// *************************************************************************** *
// *                                                                           *
// *                      Mentor Graphics Corporation                          *
// *                          All rights reserved                              *
// *                                                                           *
// *************************************************************************** *
// *                                                                           *
// * Description:         CANDB File                                           *
// * Generated at:        2019-08-28 11:46:03                                  *
// * System:              xMA19024                                             *
// * Variant:             LSPA                                                 *
// * Network:             PropulsionCAN                                        *
// *                                                                           *
// *************************************************************************** *
// *                                                                           *
// *             THIS CONFIGURATION MIGHT CONTAIN SOME ERRORS                  *
// *              IF THE INPUT MODEL WAS NOT PROPERLY FORMED!                  *
// *                    Do Not Use this File directly!                         *
// *                                                                           *
// *************************************************************************** *
VERSION "PropulsionCAN"

NS_ :

BS_:

BU_:  BECM DEM ECM EGSM ESM ETC IEM IGM ISGM MVBM MVCM MVEM OBC SRS TACM TCM VDDM VGM

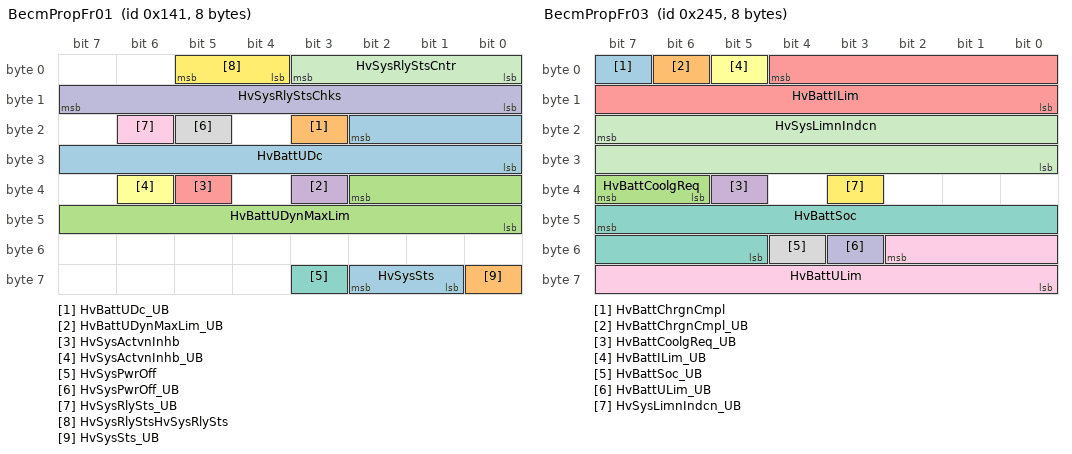
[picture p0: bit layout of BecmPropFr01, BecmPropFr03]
BO_ 321 BecmPropFr01: 8 BECM
 SG_ HvBattUDc : 18|11@0+ (0.25,0.0) [0.0|511.0] "Volt" ECM,IEM,IGM,OBC,VDDM
 SG_ HvBattUDc_UB : 19|1@0+ (1,0) [0|1] "" ECM,IEM,IGM,OBC,VDDM
 SG_ HvBattUDynMaxLim : 34|11@0+ (0.25,0.0) [0.0|511.0] "Volt" IEM,IGM,VDDM
 SG_ HvBattUDynMaxLim_UB : 35|1@0+ (1,0) [0|1] "" IEM,IGM,VDDM
 SG_ HvSysActvnInhb : 37|1@0+ (1,0) [0|1] "" ECM,VDDM
 SG_ HvSysActvnInhb_UB : 38|1@0+ (1,0) [0|1] "" ECM,VDDM
 SG_ HvSysPwrOff : 59|1@0+ (1,0) [0|1] "" ECM
 SG_ HvSysPwrOff_UB : 21|1@0+ (1,0) [0|1] "" ECM
 SG_ HvSysRlySts_UB : 22|1@0+ (1,0) [0|1] "" ECM,ESM,IEM,IGM,OBC,VDDM
 SG_ HvSysRlyStsChks : 15|8@0+ (1.0,0.0) [0.0|255.0] "Unitless" ECM,ESM,IEM,IGM,OBC,VDDM
 SG_ HvSysRlyStsCntr : 3|4@0+ (1.0,0.0) [0.0|15.0] "Unitless" ECM,ESM,IEM,IGM,OBC,VDDM
 SG_ HvSysRlyStsHvSysRlySts : 5|2@0+ (1,0) [0|3] "" ECM,ESM,IEM,IGM,OBC,VDDM
 SG_ HvSysSts : 58|2@0+ (1,0) [0|3] "" ECM,VDDM
 SG_ HvSysSts_UB : 56|1@0+ (1,0) [0|1] "" ECM,VDDM

BO_ 373 BecmPropFr02: 8 BECM
 SG_ ACChrgnConnectSts : 43|1@0+ (1,0) [0|1] "" OBC
 SG_ ACChrgnConnectSts_UB : 42|1@0+ (1,0) [0|1] "" OBC
 SG_ ACChrgnCPSts : 41|1@0+ (1,0) [0|1] "" OBC
 SG_ ACChrgnCPSts_UB : 40|1@0+ (1,0) [0|1] "" OBC
 SG_ ACChrgnCurrentLimn : 55|8@0+ (1.0,0.0) [0.0|255.0] "Unitless" OBC
 SG_ ACChrgnCurrentLimn_UB : 61|1@0+ (1,0) [0|1] "" OBC
 SG_ ACChrgnIfErr : 46|3@0+ (1.0,0.0) [0.0|7.0] "Unitless" OBC
 SG_ ACChrgnIfErr_UB : 60|1@0+ (1,0) [0|1] "" OBC
 SG_ ACChrgnS2Sts : 63|1@0+ (1,0) [0|1] "" OBC
 SG_ ACChrgnS2Sts_UB : 62|1@0+ (1,0) [0|1] "" OBC
 SG_ HvBattLimnIndcn_UB : 47|1@0+ (1,0) [0|1] "" ECM,VDDM
 SG_ HvBattLimnIndcnChks : 7|8@0+ (1.0,0.0) [0.0|255.0] "Unitless" ECM,VDDM
 SG_ HvBattLimnIndcnCntr : 31|4@0+ (1.0,0.0) [0.0|15.0] "Unitless" ECM,VDDM
 SG_ HvBattLimnIndcnHvBattLimnIndcn : 15|16@0+ (1.0,0.0) [0.0|65535.0] "Unitless" ECM,VDDM
 SG_ HvBattUDynMinLim : 26|11@0+ (0.25,0.0) [0.0|511.0] "Volt" IEM,IGM,VDDM
 SG_ HvBattUDynMinLim_UB : 27|1@0+ (1,0) [0|1] "" IEM,IGM,VDDM
 SG_ MaintainBattTFb : 59|2@0+ (1,0) [0|3] "" VDDM
 SG_ MaintainBattTFb_UB : 57|1@0+ (1,0) [0|1] "" VDDM

BO_ 581 BecmPropFr03: 8 BECM
 SG_ HvBattChrgnCmpl : 7|1@0+ (1,0) [0|1] "" ECM,OBC
 SG_ HvBattChrgnCmpl_UB : 6|1@0+ (1,0) [0|1] "" ECM,OBC
 SG_ HvBattCoolgReq : 39|2@0+ (1,0) [0|3] "" ECM,VDDM
 SG_ HvBattCoolgReq_UB : 37|1@0+ (1,0) [0|1] "" ECM,VDDM
 SG_ HvBattILim : 4|13@0+ (0.1,0.0) [0.0|819.1] "A" ECM,VDDM
 SG_ HvBattILim_UB : 5|1@0+ (1,0) [0|1] "" ECM,VDDM
 SG_ HvBattSoc : 47|11@0+ (0.05,0.0) [0.0|100.0] "%" ECM,IEM,IGM,VDDM
 SG_ HvBattSoc_UB : 52|1@0+ (1,0) [0|1] "" ECM,IEM,IGM,VDDM
 SG_ HvBattULim : 50|11@0+ (0.25,0.0) [0.0|511.0] "Volt" OBC,VDDM
 SG_ HvBattULim_UB : 51|1@0+ (1,0) [0|1] "" OBC,VDDM
 SG_ HvSysLimnIndcn : 23|16@0+ (1.0,0.0) [0.0|65535.0] "Unitless" ECM,VDDM
 SG_ HvSysLimnIndcn_UB : 35|1@0+ (1,0) [0|1] "" ECM,VDDM

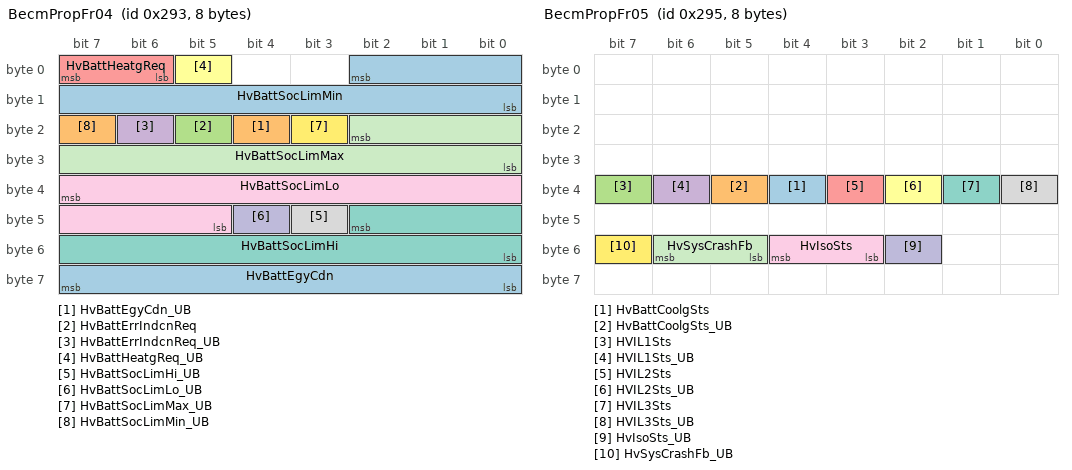
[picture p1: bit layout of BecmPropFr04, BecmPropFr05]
BO_ 659 BecmPropFr04: 8 BECM
 SG_ HvBattEgyCdn : 63|8@0+ (0.5,0.0) [0.0|100.0] "%" ECM,VDDM
 SG_ HvBattEgyCdn_UB : 20|1@0+ (1,0) [0|1] "" ECM,VDDM
 SG_ HvBattErrIndcnReq : 21|1@0+ (1,0) [0|1] "" ECM
 SG_ HvBattErrIndcnReq_UB : 22|1@0+ (1,0) [0|1] "" ECM
 SG_ HvBattHeatgReq : 7|2@0+ (1,0) [0|3] "" ECM,VDDM
 SG_ HvBattHeatgReq_UB : 5|1@0+ (1,0) [0|1] "" ECM,VDDM
 SG_ HvBattSocLimHi : 42|11@0+ (0.05,0.0) [0.0|100.0] "%" ECM,VDDM
 SG_ HvBattSocLimHi_UB : 43|1@0+ (1,0) [0|1] "" ECM,VDDM
 SG_ HvBattSocLimLo : 39|11@0+ (0.05,0.0) [0.0|100.0] "%" ECM,VDDM
 SG_ HvBattSocLimLo_UB : 44|1@0+ (1,0) [0|1] "" ECM,VDDM
 SG_ HvBattSocLimMax : 18|11@0+ (0.05,0.0) [0.0|100.0] "%" ECM,VDDM
 SG_ HvBattSocLimMax_UB : 19|1@0+ (1,0) [0|1] "" ECM,VDDM
 SG_ HvBattSocLimMin : 2|11@0+ (0.05,0.0) [0.0|100.0] "%" ECM,VDDM
 SG_ HvBattSocLimMin_UB : 23|1@0+ (1,0) [0|1] "" ECM,VDDM

BO_ 661 BecmPropFr05: 8 BECM
 SG_ HvBattCoolgSts : 36|1@0+ (1,0) [0|1] "" ECM,VDDM
 SG_ HvBattCoolgSts_UB : 37|1@0+ (1,0) [0|1] "" ECM,VDDM
 SG_ HVIL1Sts : 39|1@0+ (1,0) [0|1] "" ECM,VDDM
 SG_ HVIL1Sts_UB : 38|1@0+ (1,0) [0|1] "" ECM,VDDM
 SG_ HVIL2Sts : 35|1@0+ (1,0) [0|1] "" ECM,VDDM
 SG_ HVIL2Sts_UB : 34|1@0+ (1,0) [0|1] "" ECM,VDDM
 SG_ HVIL3Sts : 33|1@0+ (1,0) [0|1] "" ECM,VDDM
 SG_ HVIL3Sts_UB : 32|1@0+ (1,0) [0|1] "" ECM,VDDM
 SG_ HvIsoSts : 52|2@0+ (1,0) [0|3] "" ECM,VDDM
 SG_ HvIsoSts_UB : 50|1@0+ (1,0) [0|1] "" ECM,VDDM
 SG_ HvSysCrashFb : 54|2@0+ (1,0) [0|3] "" VDDM
 SG_ HvSysCrashFb_UB : 55|1@0+ (1,0) [0|1] "" VDDM

BO_ 662 BecmPropFr07: 8 BECM
 SG_ FastChrgnLockCtrl : 14|1@0+ (1,0) [0|1] "" OBC
 SG_ FastChrgnLockCtrl_UB : 13|1@0+ (1,0) [0|1] "" OBC
 SG_ HvBattCooltTReq : 7|8@0+ (1.0,-50.0) [-50.0|200.0] "degC" ECM,VDDM
 SG_ HvBattCooltTReq_UB : 15|1@0+ (1,0) [0|1] "" ECM,VDDM

BO_ 834 BecmPropFr08: 8 BECM
 SG_ HvBattCodLen : 23|8@0+ (1.0,0.0) [0.0|250.0] "Unitless" VDDM
 SG_ HvBattCodLen_UB : 39|1@0+ (1,0) [0|1] "" VDDM
 SG_ HvBattMismatchFlt : 7|1@0+ (1,0) [0|1] "" VDDM
 SG_ HvBattMismatchFlt_UB : 38|1@0+ (1,0) [0|1] "" VDDM
 SG_ HvBattNr : 31|8@0+ (1.0,0.0) [0.0|250.0] "Unitless" VDDM
 SG_ HvBattNr_UB : 37|1@0+ (1,0) [0|1] "" VDDM
 SG_ HvCellTDifFlt : 6|2@0+ (1,0) [0|3] "" VDDM
 SG_ HvCellTDifFlt_UB : 4|1@0+ (1,0) [0|1] "" VDDM
 SG_ HvCellTOverFlt : 55|2@0+ (1,0) [0|3] "" VDDM
 SG_ HvCellTOverFlt_UB : 35|1@0+ (1,0) [0|1] "" VDDM
 SG_ HvCellUDifFlt : 3|2@0+ (1,0) [0|3] "" VDDM
 SG_ HvCellUDifFlt_UB : 1|1@0+ (1,0) [0|1] "" VDDM
 SG_ HvCellUOverFlt : 53|2@0+ (1,0) [0|3] "" VDDM
 SG_ HvCellUOverFlt_UB : 34|1@0+ (1,0) [0|1] "" VDDM
 SG_ HvCellUUnderFlt : 15|2@0+ (1,0) [0|3] "" VDDM
 SG_ HvCellUUnderFlt_UB : 33|1@0+ (1,0) [0|1] "" VDDM
 SG_ HvilFlt : 0|1@0+ (1,0) [0|1] "" VDDM
 SG_ HvilFlt_UB : 42|1@0+ (1,0) [0|1] "" VDDM
 SG_ HvIsoFlt : 13|2@0+ (1,0) [0|3] "" VDDM
 SG_ HvIsoFlt_UB : 41|1@0+ (1,0) [0|1] "" VDDM
 SG_ HvPackOverChrgFlt : 11|2@0+ (1,0) [0|3] "" VDDM
 SG_ HvPackOverChrgFlt_UB : 40|1@0+ (1,0) [0|1] "" VDDM
 SG_ HvPackUOverFlt : 9|2@0+ (1,0) [0|3] "" VDDM
 SG_ HvPackUOverFlt_UB : 36|1@0+ (1,0) [0|1] "" VDDM
 SG_ HvPackUUnderFlt : 47|2@0+ (1,0) [0|3] "" VDDM
 SG_ HvPackUUnderFlt_UB : 32|1@0+ (1,0) [0|1] "" VDDM
 SG_ HvSocHiFlt : 63|2@0+ (1,0) [0|3] "" VDDM
 SG_ HvSocHiFlt_UB : 48|1@0+ (1,0) [0|1] "" VDDM
 SG_ HvSocHopFlt : 45|2@0+ (1,0) [0|3] "" VDDM
 SG_ HvSocHopFlt_UB : 43|1@0+ (1,0) [0|1] "" VDDM
 SG_ HvSocLoFlt : 51|2@0+ (1,0) [0|3] "" VDDM
 SG_ HvSocLoFlt_UB : 49|1@0+ (1,0) [0|1] "" VDDM

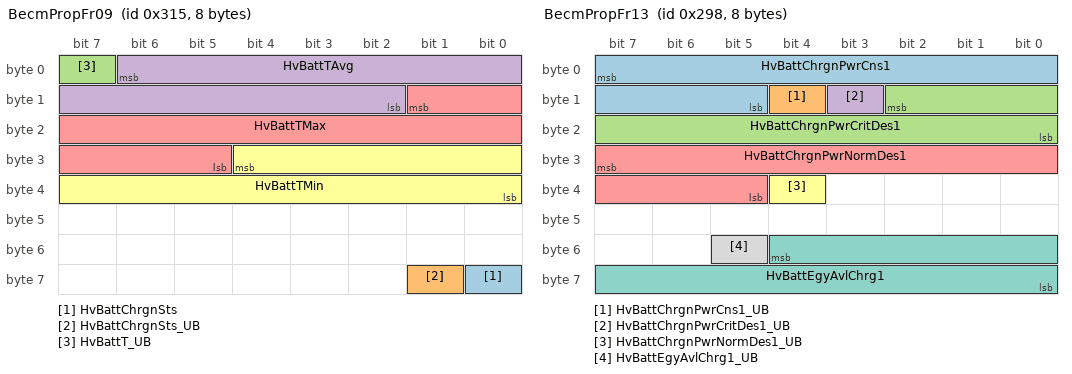
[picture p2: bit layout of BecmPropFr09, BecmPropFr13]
BO_ 789 BecmPropFr09: 8 BECM
 SG_ HvBattChrgnSts : 56|1@0+ (1,0) [0|1] "" ECM,VDDM
 SG_ HvBattChrgnSts_UB : 57|1@0+ (1,0) [0|1] "" ECM,VDDM
 SG_ HvBattT_UB : 7|1@0+ (1,0) [0|1] "" ECM,VDDM
 SG_ HvBattTAvg : 6|13@0- (0.1,0.0) [-256.0|255.9] "degC" ECM,VDDM
 SG_ HvBattTMax : 9|13@0- (0.1,0.0) [-256.0|255.9] "degC" ECM,VDDM
 SG_ HvBattTMin : 28|13@0- (0.1,0.0) [-256.0|255.9] "degC" ECM,VDDM

BO_ 817 BecmPropFr11: 8 BECM
 SG_ HvBattCoolgEgyReq1 : 7|10@0+ (20.0,0.0) [0.0|20460.0] "Wh" ECM,VDDM
 SG_ HvBattCoolgEgyReq1_UB : 39|1@0+ (1,0) [0|1] "" ECM,VDDM
 SG_ HvBattCooltFlowReq : 8|9@0+ (0.1,0.0) [0.0|51.1] "L / min" ECM,VDDM
 SG_ HvBattCooltFlowReq_UB : 38|1@0+ (1,0) [0|1] "" ECM,VDDM
 SG_ HvBattCooltT : 47|8@0+ (1.0,-50.0) [-50.0|200.0] "degC" ECM,VDDM
 SG_ HvBattCooltT_UB : 37|1@0+ (1,0) [0|1] "" ECM,VDDM

BO_ 769 BecmPropFr12: 8 BECM
 SG_ HvBattPwrCdn : 7|8@0+ (0.5,0.0) [0.0|100.0] "%" ECM,VDDM
 SG_ HvBattPwrCdn_UB : 15|1@0+ (1,0) [0|1] "" ECM,VDDM

BO_ 664 BecmPropFr13: 8 BECM
 SG_ HvBattChrgnPwrCns1 : 7|11@0+ (100.0,0.0) [0.0|204700.0] "W" ECM,VDDM
 SG_ HvBattChrgnPwrCns1_UB : 12|1@0+ (1,0) [0|1] "" ECM,VDDM
 SG_ HvBattChrgnPwrCritDes1 : 10|11@0+ (100.0,0.0) [0.0|204700.0] "W" ECM
 SG_ HvBattChrgnPwrCritDes1_UB : 11|1@0+ (1,0) [0|1] "" ECM
 SG_ HvBattChrgnPwrNormDes1 : 31|11@0+ (100.0,0.0) [0.0|204700.0] "W" ECM
 SG_ HvBattChrgnPwrNormDes1_UB : 36|1@0+ (1,0) [0|1] "" ECM
 SG_ HvBattEgyAvlChrg1 : 52|13@0+ (20.0,0.0) [0.0|163820.0] "Wh" ECM,VDDM
 SG_ HvBattEgyAvlChrg1_UB : 53|1@0+ (1,0) [0|1] "" ECM,VDDM

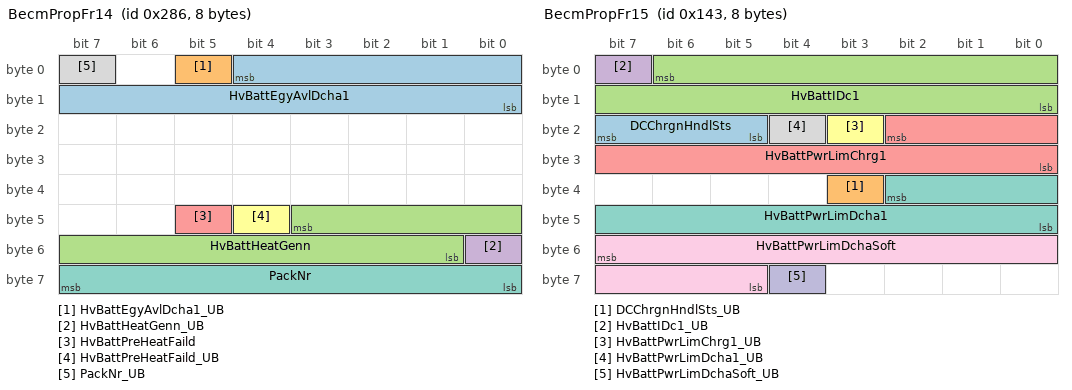
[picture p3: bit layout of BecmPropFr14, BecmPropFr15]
BO_ 646 BecmPropFr14: 8 BECM
 SG_ HvBattEgyAvlDcha1 : 4|13@0+ (20.0,0.0) [0.0|163820.0] "Wh" ECM,VDDM
 SG_ HvBattEgyAvlDcha1_UB : 5|1@0+ (1,0) [0|1] "" ECM,VDDM
 SG_ HvBattHeatGenn : 43|11@0+ (100.0,0.0) [0.0|204700.0] "W" ECM,VDDM
 SG_ HvBattHeatGenn_UB : 48|1@0+ (1,0) [0|1] "" ECM,VDDM
 SG_ HvBattPreHeatFaild : 45|1@0+ (1,0) [0|1] "" VDDM
 SG_ HvBattPreHeatFaild_UB : 44|1@0+ (1,0) [0|1] "" VDDM
 SG_ PackNr : 63|8@0+ (1.0,0.0) [0.0|250.0] "Unitless" VDDM
 SG_ PackNr_UB : 7|1@0+ (1,0) [0|1] "" VDDM

BO_ 323 BecmPropFr15: 8 BECM
 SG_ DCChrgnHndlSts : 23|3@0+ (1,0) [0|7] "" VDDM
 SG_ DCChrgnHndlSts_UB : 35|1@0+ (1,0) [0|1] "" VDDM
 SG_ HvBattIDc1 : 6|15@0+ (0.1,-1638.0) [-1638.0|1638.7000000000003] "A" ECM,VDDM
 SG_ HvBattIDc1_UB : 7|1@0+ (1,0) [0|1] "" ECM,VDDM
 SG_ HvBattPwrLimChrg1 : 18|11@0+ (0.25,0.0) [0.0|511.75] "kW" ECM
 SG_ HvBattPwrLimChrg1_UB : 19|1@0+ (1,0) [0|1] "" ECM
 SG_ HvBattPwrLimDcha1 : 34|11@0+ (0.25,0.0) [0.0|511.75] "kW" ECM
 SG_ HvBattPwrLimDcha1_UB : 20|1@0+ (1,0) [0|1] "" ECM
 SG_ HvBattPwrLimDchaSoft : 55|11@0+ (0.25,0.0) [0.0|511.75] "kW" ECM,VDDM
 SG_ HvBattPwrLimDchaSoft_UB : 60|1@0+ (1,0) [0|1] "" ECM,VDDM

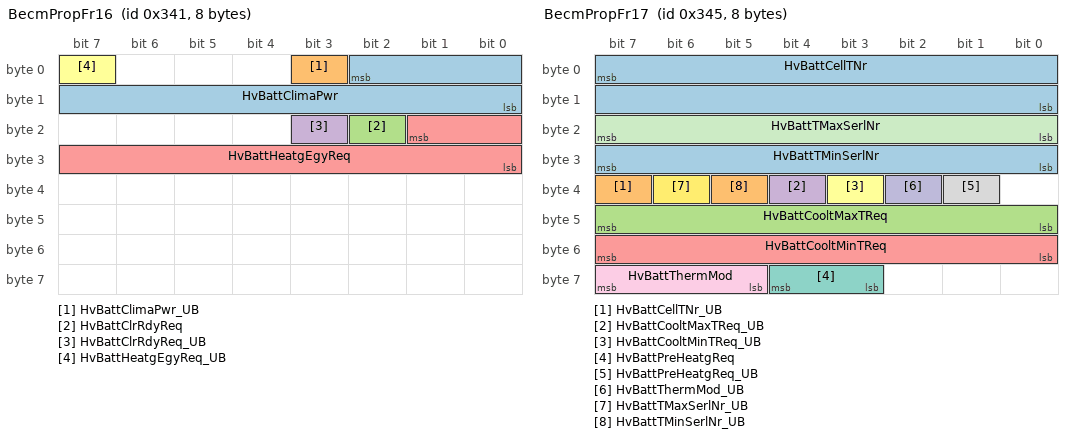
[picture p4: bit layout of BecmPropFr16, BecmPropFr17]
BO_ 833 BecmPropFr16: 8 BECM
 SG_ HvBattClimaPwr : 2|11@0+ (100.0,0.0) [0.0|204700.0] "W" ECM,VDDM
 SG_ HvBattClimaPwr_UB : 3|1@0+ (1,0) [0|1] "" ECM,VDDM
 SG_ HvBattClrRdyReq : 18|1@0+ (1,0) [0|1] "" ECM
 SG_ HvBattClrRdyReq_UB : 19|1@0+ (1,0) [0|1] "" ECM
 SG_ HvBattHeatgEgyReq : 17|10@0+ (20.0,0.0) [0.0|20460.0] "Wh" ECM,VDDM
 SG_ HvBattHeatgEgyReq_UB : 7|1@0+ (1,0) [0|1] "" ECM,VDDM

BO_ 837 BecmPropFr17: 8 BECM
 SG_ HvBattCellTNr : 7|16@0+ (1.0,0.0) [0.0|65531.0] "Unitless" VDDM
 SG_ HvBattCellTNr_UB : 39|1@0+ (1,0) [0|1] "" VDDM
 SG_ HvBattCooltMaxTReq : 47|8@0+ (1.0,-50.0) [-50.0|200.0] "degC" ECM
 SG_ HvBattCooltMaxTReq_UB : 36|1@0+ (1,0) [0|1] "" ECM
 SG_ HvBattCooltMinTReq : 55|8@0+ (1.0,-50.0) [-50.0|200.0] "degC" ECM
 SG_ HvBattCooltMinTReq_UB : 35|1@0+ (1,0) [0|1] "" ECM
 SG_ HvBattPreHeatgReq : 60|2@0+ (1,0) [0|3] "" ECM,OBC,VDDM
 SG_ HvBattPreHeatgReq_UB : 33|1@0+ (1,0) [0|1] "" ECM,OBC,VDDM
 SG_ HvBattThermMod : 63|3@0+ (1,0) [0|7] "" ECM,VDDM
 SG_ HvBattThermMod_UB : 34|1@0+ (1,0) [0|1] "" ECM,VDDM
 SG_ HvBattTMaxSerlNr : 23|8@0+ (1.0,0.0) [0.0|250.0] "Unitless" VDDM
 SG_ HvBattTMaxSerlNr_UB : 38|1@0+ (1,0) [0|1] "" VDDM
 SG_ HvBattTMinSerlNr : 31|8@0+ (1.0,0.0) [0.0|250.0] "Unitless" VDDM
 SG_ HvBattTMinSerlNr_UB : 37|1@0+ (1,0) [0|1] "" VDDM

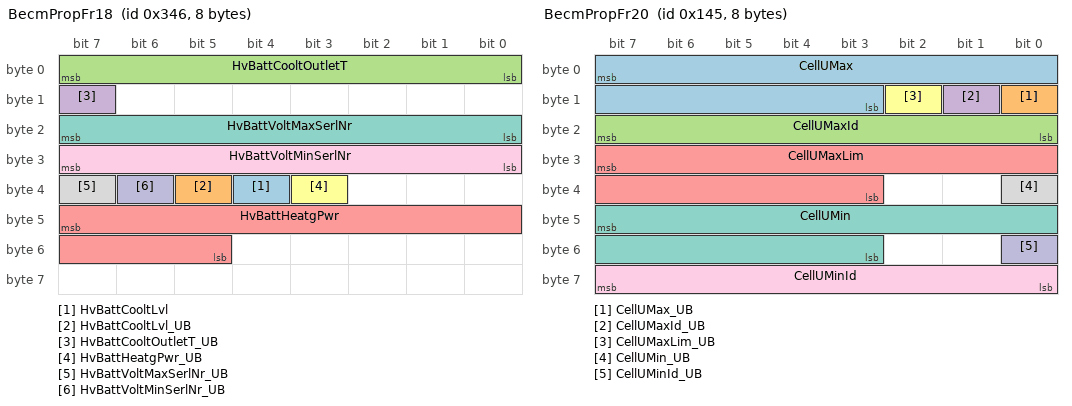
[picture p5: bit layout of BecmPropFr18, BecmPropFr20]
BO_ 838 BecmPropFr18: 8 BECM
 SG_ HvBattCooltLvl : 36|1@0+ (1,0) [0|1] "" ECM,VDDM
 SG_ HvBattCooltLvl_UB : 37|1@0+ (1,0) [0|1] "" ECM,VDDM
 SG_ HvBattCooltOutletT : 7|8@0+ (1.0,-50.0) [-50.0|200.0] "degC" ECM,VDDM
 SG_ HvBattCooltOutletT_UB : 15|1@0+ (1,0) [0|1] "" ECM,VDDM
 SG_ HvBattHeatgPwr : 47|11@0+ (100.0,0.0) [0.0|204700.0] "W" ECM,VDDM
 SG_ HvBattHeatgPwr_UB : 35|1@0+ (1,0) [0|1] "" ECM,VDDM
 SG_ HvBattVoltMaxSerlNr : 23|8@0+ (1.0,0.0) [0.0|250.0] "Unitless" VDDM
 SG_ HvBattVoltMaxSerlNr_UB : 39|1@0+ (1,0) [0|1] "" VDDM
 SG_ HvBattVoltMinSerlNr : 31|8@0+ (1.0,0.0) [0.0|250.0] "Unitless" VDDM
 SG_ HvBattVoltMinSerlNr_UB : 38|1@0+ (1,0) [0|1] "" VDDM

BO_ 839 BecmPropFr19: 8 BECM
 SG_ HvBattCod_UB : 63|1@0+ (1,0) [0|1] "" VDDM
 SG_ HvBattCodPackCodeX1 : 7|8@0+ (1.0,0.0) [0.0|255.0] "Unitless" VDDM
 SG_ HvBattCodPackCodeX2 : 15|8@0+ (1.0,0.0) [0.0|255.0] "Unitless" VDDM
 SG_ HvBattCodPackCodeX3 : 23|8@0+ (1.0,0.0) [0.0|255.0] "Unitless" VDDM
 SG_ HvBattCodPackCodeX4 : 31|8@0+ (1.0,0.0) [0.0|255.0] "Unitless" VDDM
 SG_ HvBattCodPackCodeX5 : 39|8@0+ (1.0,0.0) [0.0|255.0] "Unitless" VDDM
 SG_ HvBattCodPackCodeX6 : 47|8@0+ (1.0,0.0) [0.0|255.0] "Unitless" VDDM
 SG_ HvBattCodPackIndex : 55|8@0+ (1.0,0.0) [0.0|255.0] "Unitless" VDDM

BO_ 325 BecmPropFr20: 8 BECM
 SG_ CellUMax : 7|13@0+ (0.001,0.0) [0.0|5.0] "Volt" ECM,VDDM
 SG_ CellUMax_UB : 8|1@0+ (1,0) [0|1] "" ECM,VDDM
 SG_ CellUMaxId : 23|8@0+ (1.0,0.0) [0.0|250.0] "Unitless" ECM,VDDM
 SG_ CellUMaxId_UB : 9|1@0+ (1,0) [0|1] "" ECM,VDDM
 SG_ CellUMaxLim : 31|13@0+ (0.001,0.0) [0.0|5.0] "Volt" ECM
 SG_ CellUMaxLim_UB : 10|1@0+ (1,0) [0|1] "" ECM
 SG_ CellUMin : 47|13@0+ (0.001,0.0) [0.0|5.0] "Volt" ECM,VDDM
 SG_ CellUMin_UB : 32|1@0+ (1,0) [0|1] "" ECM,VDDM
 SG_ CellUMinId : 63|8@0+ (1.0,0.0) [0.0|250.0] "Unitless" ECM,VDDM
 SG_ CellUMinId_UB : 48|1@0+ (1,0) [0|1] "" ECM,VDDM

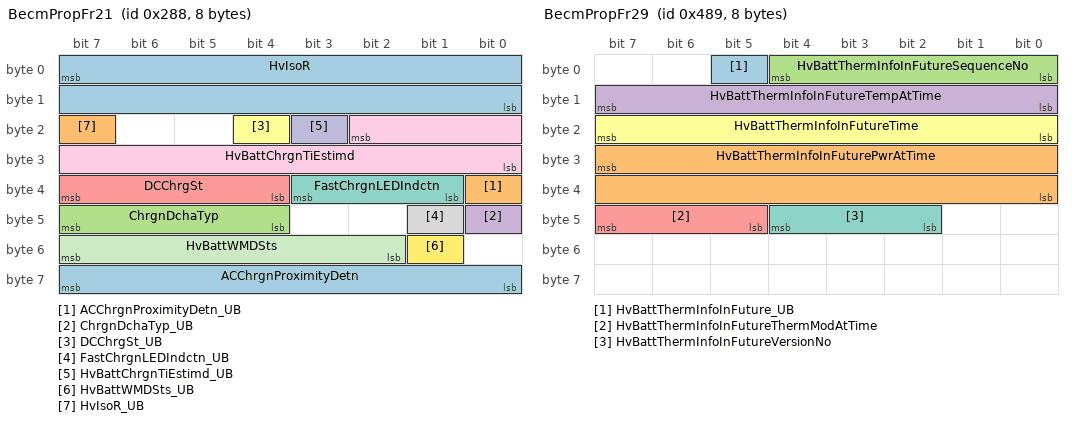
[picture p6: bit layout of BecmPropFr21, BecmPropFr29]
BO_ 648 BecmPropFr21: 8 BECM
 SG_ ACChrgnProximityDetn : 63|8@0+ (1.0,0.0) [0.0|255.0] "Unitless" OBC
 SG_ ACChrgnProximityDetn_UB : 32|1@0+ (1,0) [0|1] "" OBC
 SG_ ChrgnDchaTyp : 47|4@0+ (1.0,0.0) [0.0|15.0] "Unitless" OBC
 SG_ ChrgnDchaTyp_UB : 40|1@0+ (1,0) [0|1] "" OBC
 SG_ DCChrgSt : 39|4@0+ (1,0) [0|15] "" VDDM
 SG_ DCChrgSt_UB : 20|1@0+ (1,0) [0|1] "" VDDM
 SG_ FastChrgnLEDIndctn : 35|3@0+ (1,0) [0|7] "" Vector_XXX
 SG_ FastChrgnLEDIndctn_UB : 41|1@0+ (1,0) [0|1] "" Vector_XXX
 SG_ HvBattChrgnTiEstimd : 18|11@0+ (1.0,0.0) [0.0|2047.0] "Mins" VDDM
 SG_ HvBattChrgnTiEstimd_UB : 19|1@0+ (1,0) [0|1] "" VDDM
 SG_ HvBattWMDSts : 55|6@0+ (1.0,0.0) [0.0|63.0] "Unitless" ECM
 SG_ HvBattWMDSts_UB : 49|1@0+ (1,0) [0|1] "" ECM
 SG_ HvIsoR : 7|16@0+ (1.0,0.0) [0.0|60000.0] "kOhm" VDDM
 SG_ HvIsoR_UB : 23|1@0+ (1,0) [0|1] "" VDDM

BO_ 83 BecmPropFr22: 8 BECM
 SG_ ChrgEquipIDc : 47|15@0+ (0.1,-1638.0) [-1638.0|1638.7000000000003] "A" Vector_XXX
 SG_ ChrgEquipIDc_UB : 48|1@0+ (1,0) [0|1] "" Vector_XXX
 SG_ CpAmp : 7|8@0+ (0.1,0.0) [0.0|16.0] "Volt" OBC
 SG_ CpAmp_UB : 27|1@0+ (1,0) [0|1] "" OBC
 SG_ CpDuty : 15|8@0+ (0.5,0.0) [0.0|100.0] "%" OBC
 SG_ CpDuty_UB : 28|1@0+ (1,0) [0|1] "" OBC

BO_ 322 BecmPropFr23: 8 BECM
 SG_ HvBattCellUInfo_UB : 32|1@0+ (1,0) [0|1] "" VDDM
 SG_ HvBattCellUInfoU1 : 7|8@0+ (1.0,0.0) [0.0|255.0] "Unitless" VDDM
 SG_ HvBattCellUInfoU2 : 15|8@0+ (1.0,0.0) [0.0|255.0] "Unitless" VDDM
 SG_ HvBattCellUInfoU3 : 23|8@0+ (1.0,0.0) [0.0|255.0] "Unitless" VDDM
 SG_ HvBattCellUInfoU4 : 31|13@0+ (1.0,0.0) [0.0|8191.0] "Unitless" VDDM

BO_ 656 BecmPropFr24: 8 BECM
 SG_ HvBattCellTInfo_UB : 55|1@0+ (1,0) [0|1] "" VDDM
 SG_ HvBattCellTInfoHvBattSnsrT : 7|8@0+ (1.0,-40.0) [-40.0|215.0] "degC" VDDM
 SG_ HvBattCellTInfoHvBattTMax : 15|8@0+ (1.0,-40.0) [-40.0|215.0] "degC" VDDM
 SG_ HvBattCellTInfoHvBattTMin : 23|8@0+ (1.0,-40.0) [-40.0|215.0] "degC" VDDM
 SG_ HvBattCellTInfoHvBattTSnsrNr : 31|8@0+ (1.0,0.0) [0.0|255.0] "Unitless" VDDM
 SG_ HvBattCellTInfoHvTempSnsrTMaxsSerlNr : 39|8@0+ (1.0,0.0) [0.0|255.0] "Unitless" VDDM
 SG_ HvBattCellTInfoHvTempSnsrTMinSerlNr : 47|8@0+ (1.0,0.0) [0.0|255.0] "Unitless" VDDM

BO_ 654 BecmPropFr25: 8 BECM
 SG_ OnceChrgnEgy : 7|20@0+ (1.0,0.0) [0.0|1048574.0] "Unitless" VDDM
 SG_ OnceChrgnEgy_UB : 56|1@0+ (1,0) [0|1] "" VDDM
 SG_ OnceDchaEgy : 19|20@0+ (1.0,0.0) [0.0|1048574.0] "Unitless" VDDM
 SG_ OnceDchaEgy_UB : 57|1@0+ (1,0) [0|1] "" VDDM

BO_ 1177 BecmPropFr27: 8 BECM
 SG_ HvBattCap : 7|16@0+ (0.1,0.0) [0.0|6553.5] "Ah" VDDM
 SG_ HvBattCap_UB : 23|1@0+ (1,0) [0|1] "" VDDM
 SG_ TotChrgCap : 39|32@0+ (0.01,0.0) [0.0|42949672.95] "Ah" VDDM
 SG_ TotChrgCap_UB : 22|1@0+ (1,0) [0|1] "" VDDM

BO_ 1180 BecmPropFr28: 8 BECM
 SG_ TotDchaCap : 7|32@0+ (0.01,0.0) [0.0|42949672.95] "Ah" VDDM
 SG_ TotDchaCap_UB : 39|1@0+ (1,0) [0|1] "" VDDM

BO_ 1161 BecmPropFr29: 8 BECM
 SG_ HvBattThermInfoInFuture_UB : 5|1@0+ (1,0) [0|1] "" ECM
 SG_ HvBattThermInfoInFuturePwrAtTime : 31|16@0+ (50.0,-25000.0) [-25000.0|25000.0] "W" ECM
 SG_ HvBattThermInfoInFutureSequenceNo : 4|5@0+ (1.0,0.0) [0.0|31.0] "Unitless" ECM
 SG_ HvBattThermInfoInFutureTempAtTime : 15|8@0+ (1.0,-50.0) [-50.0|205.0] "degC" ECM
 SG_ HvBattThermInfoInFutureThermModAtTime : 47|3@0+ (1,0) [0|7] "" ECM
 SG_ HvBattThermInfoInFutureTime : 23|8@0+ (1.0,0.0) [0.0|255.0] "Unitless" ECM
 SG_ HvBattThermInfoInFutureVersionNo : 44|3@0+ (1.0,0.0) [0.0|7.0] "Unitless" ECM

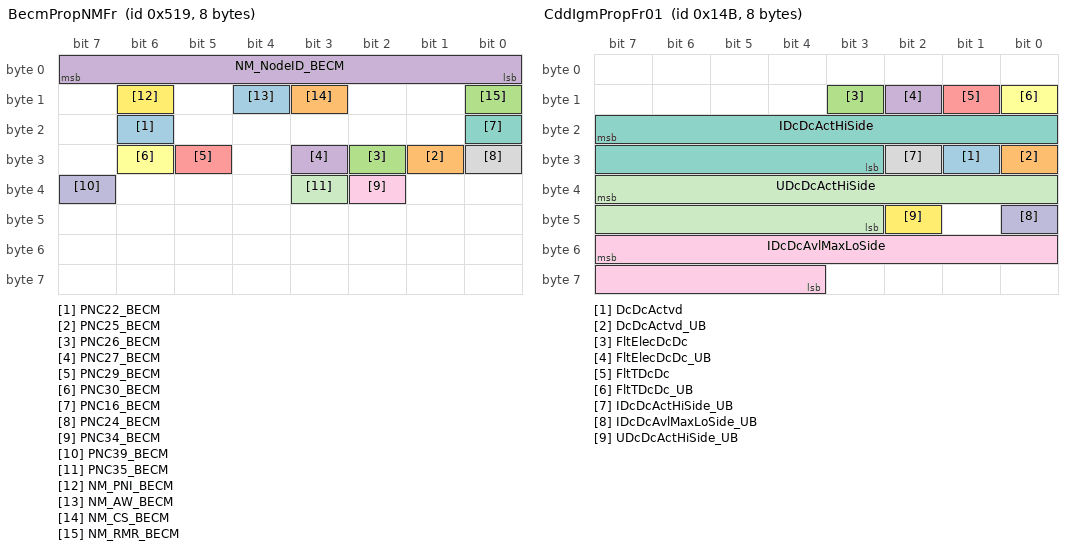
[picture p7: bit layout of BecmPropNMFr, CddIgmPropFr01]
BO_ 1305 BecmPropNMFr: 8 BECM
 SG_ PNC22_BECM : 22|1@0+ (1,0) [0|0] "" VGM
 SG_ PNC25_BECM : 25|1@0+ (1,0) [0|0] "" VGM
 SG_ PNC26_BECM : 26|1@0+ (1,0) [0|0] "" VGM
 SG_ PNC27_BECM : 27|1@0+ (1,0) [0|0] "" VGM
 SG_ PNC29_BECM : 29|1@0+ (1,0) [0|0] "" VGM
 SG_ PNC30_BECM : 30|1@0+ (1,0) [0|0] "" VGM
 SG_ PNC16_BECM : 16|1@0+ (1,0) [0|0] "" VGM
 SG_ PNC24_BECM : 24|1@0+ (1,0) [0|0] "" VGM
 SG_ PNC34_BECM : 34|1@0+ (1,0) [0|0] "" VGM
 SG_ PNC39_BECM : 39|1@0+ (1,0) [0|0] "" VGM
 SG_ PNC35_BECM : 35|1@0+ (1,0) [0|0] "" VGM
 SG_ NM_PNI_BECM : 14|1@0+ (1,0) [0|0] "" VGM
 SG_ NM_AW_BECM : 12|1@0+ (1,0) [0|0] "" VGM
 SG_ NM_CS_BECM : 11|1@0+ (1,0) [0|0] "" VGM
 SG_ NM_RMR_BECM : 8|1@0+ (1,0) [0|0] "" VGM
 SG_ NM_NodeID_BECM : 7|8@0+ (1,0) [0|0] "" VGM

BO_ 1345 BecmPropVFCVectorFr: 8 BECM
 SG_ VFCVectorBECMBlockID : 1|2@0+ (1.0,0.0) [0.0|3.0] "Unitless" ETC
 SG_ VFCVectorBECMVFCid0 : 2|1@0+ (1,0) [0|1] "" ETC
 SG_ VFCVectorBECMVFCid1 : 3|1@0+ (1,0) [0|1] "" ETC
 SG_ VFCVectorBECMVFCid10 : 12|1@0+ (1,0) [0|1] "" ETC
 SG_ VFCVectorBECMVFCid11 : 13|1@0+ (1,0) [0|1] "" ETC
 SG_ VFCVectorBECMVFCid12 : 14|1@0+ (1,0) [0|1] "" ETC
 SG_ VFCVectorBECMVFCid13 : 15|1@0+ (1,0) [0|1] "" ETC
 SG_ VFCVectorBECMVFCid14 : 16|1@0+ (1,0) [0|1] "" ETC
 SG_ VFCVectorBECMVFCid15 : 17|1@0+ (1,0) [0|1] "" ETC
 SG_ VFCVectorBECMVFCid16 : 18|1@0+ (1,0) [0|1] "" ETC
 SG_ VFCVectorBECMVFCid17 : 19|1@0+ (1,0) [0|1] "" ETC
 SG_ VFCVectorBECMVFCid18 : 20|1@0+ (1,0) [0|1] "" ETC
 SG_ VFCVectorBECMVFCid19 : 21|1@0+ (1,0) [0|1] "" ETC
 SG_ VFCVectorBECMVFCid2 : 4|1@0+ (1,0) [0|1] "" ETC
 SG_ VFCVectorBECMVFCid20 : 22|1@0+ (1,0) [0|1] "" ETC
 SG_ VFCVectorBECMVFCid21 : 23|1@0+ (1,0) [0|1] "" ETC
 SG_ VFCVectorBECMVFCid22 : 24|1@0+ (1,0) [0|1] "" ETC
 SG_ VFCVectorBECMVFCid23 : 25|1@0+ (1,0) [0|1] "" ETC
 SG_ VFCVectorBECMVFCid24 : 26|1@0+ (1,0) [0|1] "" ETC
 SG_ VFCVectorBECMVFCid25 : 27|1@0+ (1,0) [0|1] "" ETC
 SG_ VFCVectorBECMVFCid26 : 28|1@0+ (1,0) [0|1] "" ETC
 SG_ VFCVectorBECMVFCid27 : 29|1@0+ (1,0) [0|1] "" ETC
 SG_ VFCVectorBECMVFCid28 : 30|1@0+ (1,0) [0|1] "" ETC
 SG_ VFCVectorBECMVFCid29 : 31|1@0+ (1,0) [0|1] "" ETC
 SG_ VFCVectorBECMVFCid3 : 5|1@0+ (1,0) [0|1] "" ETC
 SG_ VFCVectorBECMVFCid30 : 32|1@0+ (1,0) [0|1] "" ETC
 SG_ VFCVectorBECMVFCid31 : 33|1@0+ (1,0) [0|1] "" ETC
 SG_ VFCVectorBECMVFCid32 : 34|1@0+ (1,0) [0|1] "" ETC
 SG_ VFCVectorBECMVFCid33 : 35|1@0+ (1,0) [0|1] "" ETC
 SG_ VFCVectorBECMVFCid34 : 36|1@0+ (1,0) [0|1] "" ETC
 SG_ VFCVectorBECMVFCid35 : 37|1@0+ (1,0) [0|1] "" ETC
 SG_ VFCVectorBECMVFCid36 : 38|1@0+ (1,0) [0|1] "" ETC
 SG_ VFCVectorBECMVFCid37 : 39|1@0+ (1,0) [0|1] "" ETC
 SG_ VFCVectorBECMVFCid38 : 40|1@0+ (1,0) [0|1] "" ETC
 SG_ VFCVectorBECMVFCid39 : 41|1@0+ (1,0) [0|1] "" ETC
 SG_ VFCVectorBECMVFCid4 : 6|1@0+ (1,0) [0|1] "" ETC
 SG_ VFCVectorBECMVFCid40 : 42|1@0+ (1,0) [0|1] "" ETC
 SG_ VFCVectorBECMVFCid41 : 43|1@0+ (1,0) [0|1] "" ETC
 SG_ VFCVectorBECMVFCid42 : 44|1@0+ (1,0) [0|1] "" ETC
 SG_ VFCVectorBECMVFCid43 : 45|1@0+ (1,0) [0|1] "" ETC
 SG_ VFCVectorBECMVFCid44 : 46|1@0+ (1,0) [0|1] "" ETC
 SG_ VFCVectorBECMVFCid45 : 47|1@0+ (1,0) [0|1] "" ETC
 SG_ VFCVectorBECMVFCid46 : 48|1@0+ (1,0) [0|1] "" ETC
 SG_ VFCVectorBECMVFCid47 : 49|1@0+ (1,0) [0|1] "" ETC
 SG_ VFCVectorBECMVFCid48 : 50|1@0+ (1,0) [0|1] "" ETC
 SG_ VFCVectorBECMVFCid49 : 51|1@0+ (1,0) [0|1] "" ETC
 SG_ VFCVectorBECMVFCid5 : 7|1@0+ (1,0) [0|1] "" ETC
 SG_ VFCVectorBECMVFCid50 : 52|1@0+ (1,0) [0|1] "" ETC
 SG_ VFCVectorBECMVFCid51 : 53|1@0+ (1,0) [0|1] "" ETC
 SG_ VFCVectorBECMVFCid52 : 54|1@0+ (1,0) [0|1] "" ETC
 SG_ VFCVectorBECMVFCid53 : 55|1@0+ (1,0) [0|1] "" ETC
 SG_ VFCVectorBECMVFCid54 : 56|1@0+ (1,0) [0|1] "" ETC
 SG_ VFCVectorBECMVFCid55 : 57|1@0+ (1,0) [0|1] "" ETC
 SG_ VFCVectorBECMVFCid56 : 58|1@0+ (1,0) [0|1] "" ETC
 SG_ VFCVectorBECMVFCid57 : 59|1@0+ (1,0) [0|1] "" ETC
 SG_ VFCVectorBECMVFCid58 : 60|1@0+ (1,0) [0|1] "" ETC
 SG_ VFCVectorBECMVFCid59 : 61|1@0+ (1,0) [0|1] "" ETC
 SG_ VFCVectorBECMVFCid6 : 8|1@0+ (1,0) [0|1] "" ETC
 SG_ VFCVectorBECMVFCid60 : 62|1@0+ (1,0) [0|1] "" ETC
 SG_ VFCVectorBECMVFCid61 : 63|1@0+ (1,0) [0|1] "" ETC
 SG_ VFCVectorBECMVFCid7 : 9|1@0+ (1,0) [0|1] "" ETC
 SG_ VFCVectorBECMVFCid8 : 10|1@0+ (1,0) [0|1] "" ETC
 SG_ VFCVectorBECMVFCid9 : 11|1@0+ (1,0) [0|1] "" ETC

BO_ 1589 BecmToVddmPropDiagResFrame: 8 BECM
 SG_ BecmToVddmPropDiagResNpdu : 7|64@0+ (1,0) [0|0] "" VDDM

BO_ 2026 BecmToVgmJ1979OBDPropDiagResFrame11: 8 BECM
 SG_ BecmToVgmJ1979OBDPropDiagResNpdu11 : 7|64@0+ (1,0) [0|0] "" VGM

BO_ 331 CddIgmPropFr01: 8 IGM
 SG_ DcDcActvd : 25|1@0+ (1,0) [0|1] "" ECM,VDDM
 SG_ DcDcActvd_UB : 24|1@0+ (1,0) [0|1] "" ECM,VDDM
 SG_ FltElecDcDc : 11|1@0+ (1,0) [0|1] "" VDDM
 SG_ FltElecDcDc_UB : 10|1@0+ (1,0) [0|1] "" VDDM
 SG_ FltTDcDc : 9|1@0+ (1,0) [0|1] "" VDDM
 SG_ FltTDcDc_UB : 8|1@0+ (1,0) [0|1] "" VDDM
 SG_ IDcDcActHiSide : 23|13@0+ (0.1,-410.0) [-410.0|409.1] "A" ECM,VDDM
 SG_ IDcDcActHiSide_UB : 26|1@0+ (1,0) [0|1] "" ECM,VDDM
 SG_ IDcDcAvlMaxLoSide : 55|12@0+ (0.1,0.0) [0.0|409.5] "A" VDDM
 SG_ IDcDcAvlMaxLoSide_UB : 40|1@0+ (1,0) [0|1] "" VDDM
 SG_ UDcDcActHiSide : 39|13@0+ (0.125,0.0) [0.0|1023.0] "Volt" ECM,VDDM
 SG_ UDcDcActHiSide_UB : 42|1@0+ (1,0) [0|1] "" ECM,VDDM

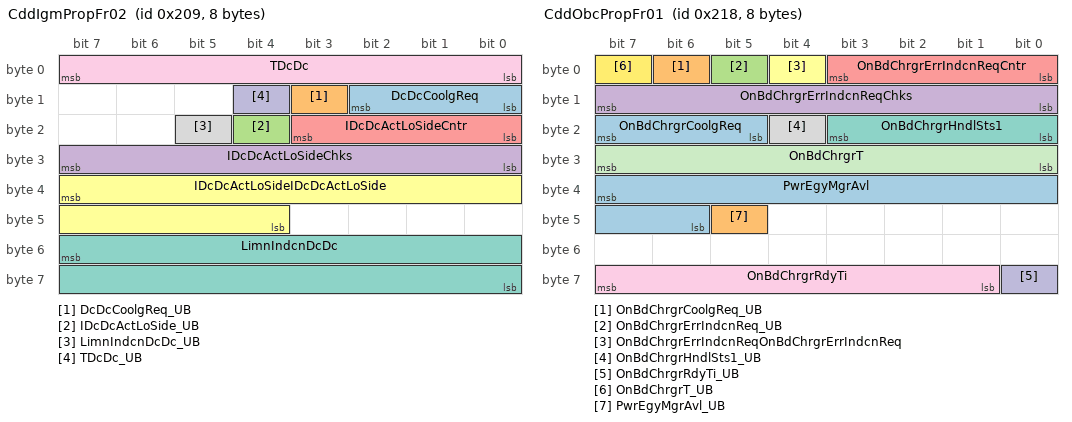
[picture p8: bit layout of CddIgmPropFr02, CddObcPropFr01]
BO_ 521 CddIgmPropFr02: 8 IGM
 SG_ DcDcCoolgReq : 10|3@0+ (1,0) [0|7] "" ECM,VDDM
 SG_ DcDcCoolgReq_UB : 11|1@0+ (1,0) [0|1] "" ECM,VDDM
 SG_ IDcDcActLoSide_UB : 20|1@0+ (1,0) [0|1] "" VDDM
 SG_ IDcDcActLoSideChks : 31|8@0+ (1.0,0.0) [0.0|255.0] "Unitless" VDDM
 SG_ IDcDcActLoSideCntr : 19|4@0+ (1.0,0.0) [0.0|15.0] "Unitless" VDDM
 SG_ IDcDcActLoSideIDcDcActLoSide : 39|12@0+ (0.1,0.0) [0.0|409.5] "A" VDDM
 SG_ LimnIndcnDcDc : 55|16@0+ (1.0,0.0) [0.0|65535.0] "Unitless" ECM,VDDM
 SG_ LimnIndcnDcDc_UB : 21|1@0+ (1,0) [0|1] "" ECM,VDDM
 SG_ TDcDc : 7|8@0+ (1.0,-40.0) [-40.0|215.0] "degC" ECM,VDDM
 SG_ TDcDc_UB : 12|1@0+ (1,0) [0|1] "" ECM,VDDM

BO_ 1109 CddIgmPropFr05: 8 IGM
 SG_ DcDcMinCooltFlow : 7|7@0+ (0.1,0.0) [0.0|12.700000000000001] "L / min" ECM
 SG_ DcDcMinCooltFlow_UB : 0|1@0+ (1,0) [0|1] "" ECM
 SG_ DcDcNetIntHeatg : 15|11@0+ (1.0,-1000.0) [-1000.0|1000.0] "W" ECM
 SG_ DcDcNetIntHeatg_UB : 20|1@0+ (1,0) [0|1] "" ECM
 SG_ TDcDcCoolt : 31|8@0+ (1.0,-40.0) [-40.0|215.0] "degC" ECM,VDDM
 SG_ TDcDcCoolt_UB : 16|1@0+ (1,0) [0|1] "" ECM,VDDM

BO_ 536 CddObcPropFr01: 8 OBC
 SG_ OnBdChrgrCoolgReq : 23|3@0+ (1,0) [0|7] "" ECM
 SG_ OnBdChrgrCoolgReq_UB : 6|1@0+ (1,0) [0|1] "" ECM
 SG_ OnBdChrgrErrIndcnReq_UB : 5|1@0+ (1,0) [0|1] "" ECM,VDDM
 SG_ OnBdChrgrErrIndcnReqChks : 15|8@0+ (1.0,0.0) [0.0|255.0] "Unitless" ECM,VDDM
 SG_ OnBdChrgrErrIndcnReqCntr : 3|4@0+ (1.0,0.0) [0.0|15.0] "Unitless" ECM,VDDM
 SG_ OnBdChrgrErrIndcnReqOnBdChrgrErrIndcnReq : 4|1@0+ (1,0) [0|1] "" ECM,VDDM
 SG_ OnBdChrgrHndlSts1 : 19|4@0+ (1,0) [0|15] "" BECM,ECM,VDDM
 SG_ OnBdChrgrHndlSts1_UB : 20|1@0+ (1,0) [0|1] "" BECM,ECM,VDDM
 SG_ OnBdChrgrRdyTi : 63|7@0+ (100.0,0.0) [0.0|12700.0] "Milliseconds" VDDM
 SG_ OnBdChrgrRdyTi_UB : 56|1@0+ (1,0) [0|1] "" VDDM
 SG_ OnBdChrgrT : 31|8@0+ (1.0,-40.0) [-40.0|215.0] "degC" ECM,VDDM
 SG_ OnBdChrgrT_UB : 7|1@0+ (1,0) [0|1] "" ECM,VDDM
 SG_ PwrEgyMgrAvl : 39|10@0+ (20.0,0.0) [0.0|20460.0] "W" BECM,ECM,VDDM
 SG_ PwrEgyMgrAvl_UB : 45|1@0+ (1,0) [0|1] "" BECM,ECM,VDDM

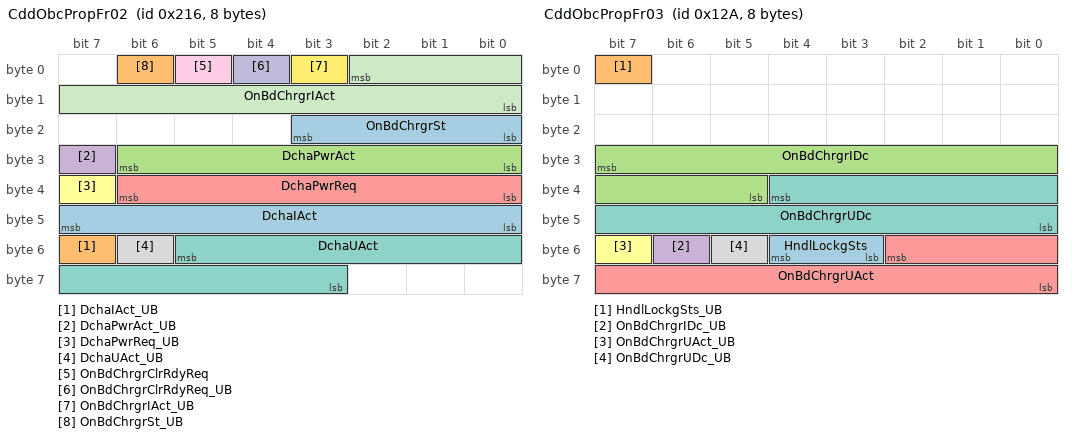
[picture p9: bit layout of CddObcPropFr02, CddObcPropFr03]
BO_ 534 CddObcPropFr02: 8 OBC
 SG_ DchaIAct : 47|8@0+ (0.1,0.0) [0.0|25.5] "A" VDDM
 SG_ DchaIAct_UB : 55|1@0+ (1,0) [0|1] "" VDDM
 SG_ DchaPwrAct : 30|7@0+ (100.0,0.0) [0.0|6600.0] "W" ECM,VDDM
 SG_ DchaPwrAct_UB : 31|1@0+ (1,0) [0|1] "" ECM,VDDM
 SG_ DchaPwrReq : 38|7@0+ (100.0,0.0) [0.0|6600.0] "W" ECM
 SG_ DchaPwrReq_UB : 39|1@0+ (1,0) [0|1] "" ECM
 SG_ DchaUAct : 53|11@0+ (0.25,0.0) [0.0|511.0] "Volt" VDDM
 SG_ DchaUAct_UB : 54|1@0+ (1,0) [0|1] "" VDDM
 SG_ OnBdChrgrClrRdyReq : 5|1@0+ (1,0) [0|1] "" ECM
 SG_ OnBdChrgrClrRdyReq_UB : 4|1@0+ (1,0) [0|1] "" ECM
 SG_ OnBdChrgrIAct : 2|11@0+ (0.05,-32.0) [-32.0|64.0] "A" BECM,VDDM
 SG_ OnBdChrgrIAct_UB : 3|1@0+ (1,0) [0|1] "" BECM,VDDM
 SG_ OnBdChrgrSt : 19|4@0+ (1,0) [0|15] "" BECM,ECM,VDDM
 SG_ OnBdChrgrSt_UB : 6|1@0+ (1,0) [0|1] "" BECM,ECM,VDDM

BO_ 298 CddObcPropFr03: 8 OBC
 SG_ HndlLockgSts : 52|2@0+ (1,0) [0|3] "" BECM,VDDM
 SG_ HndlLockgSts_UB : 7|1@0+ (1,0) [0|1] "" BECM,VDDM
 SG_ OnBdChrgrIDc : 31|11@0+ (0.05,-32.0) [-32.0|64.0] "A" BECM,VDDM
 SG_ OnBdChrgrIDc_UB : 54|1@0+ (1,0) [0|1] "" BECM,VDDM
 SG_ OnBdChrgrUAct : 50|11@0+ (0.25,0.0) [0.0|511.0] "Volt" BECM,VDDM
 SG_ OnBdChrgrUAct_UB : 55|1@0+ (1,0) [0|1] "" BECM,VDDM
 SG_ OnBdChrgrUDc : 36|13@0+ (0.1,0.0) [0.0|600.0] "Volt" BECM,VDDM
 SG_ OnBdChrgrUDc_UB : 53|1@0+ (1,0) [0|1] "" BECM,VDDM

BO_ 1041 CddObcPropFr04: 8 OBC
 SG_ OnBdChrgrCooltT : 7|8@0+ (1.0,-40.0) [-40.0|215.0] "degC" ECM
 SG_ OnBdChrgrCooltT_UB : 27|1@0+ (1,0) [0|1] "" ECM
 SG_ OnBdChrgrMinCooltFlow : 15|7@0+ (0.1,0.0) [0.0|12.700000000000001] "L / min" ECM
 SG_ OnBdChrgrMinCooltFlow_UB : 8|1@0+ (1,0) [0|1] "" ECM
 SG_ OnBdChrgrNetIntHeatg : 23|11@0+ (1.0,-1000.0) [-1000.0|1000.0] "W" ECM
 SG_ OnBdChrgrNetIntHeatg_UB : 28|1@0+ (1,0) [0|1] "" ECM

BO_ 1249 DemPropFr01: 8 DEM
 SG_ DftlCtrlInfo10 : 7|8@0+ (1.0,0.0) [0.0|255.0] "Unitless" ETC
 SG_ DftlCtrlInfo11 : 15|8@0+ (1.0,0.0) [0.0|255.0] "Unitless" ETC
 SG_ DftlCtrlInfo12 : 23|8@0+ (1.0,0.0) [0.0|255.0] "Unitless" ETC
 SG_ DftlCtrlInfo13 : 31|8@0+ (1.0,0.0) [0.0|255.0] "Unitless" ETC
 SG_ DftlCtrlInfo14 : 39|8@0+ (1.0,0.0) [0.0|255.0] "Unitless" ETC
 SG_ DftlCtrlInfo15 : 47|8@0+ (1.0,0.0) [0.0|255.0] "Unitless" ETC
 SG_ DftlCtrlInfo16 : 55|8@0+ (1.0,0.0) [0.0|255.0] "Unitless" ETC
 SG_ DftlCtrlInfo17 : 63|8@0+ (1.0,0.0) [0.0|255.0] "Unitless" ETC

BO_ 1250 DemPropFr02: 8 DEM
 SG_ DftlCtrlInfo20 : 7|8@0+ (1.0,0.0) [0.0|255.0] "Unitless" ETC
 SG_ DftlCtrlInfo21 : 15|8@0+ (1.0,0.0) [0.0|255.0] "Unitless" ETC
 SG_ DftlCtrlInfo22 : 23|8@0+ (1.0,0.0) [0.0|255.0] "Unitless" ETC
 SG_ DftlCtrlInfo23 : 31|8@0+ (1.0,0.0) [0.0|255.0] "Unitless" ETC
 SG_ DftlCtrlInfo24 : 39|8@0+ (1.0,0.0) [0.0|255.0] "Unitless" ETC
 SG_ DftlCtrlInfo25 : 47|8@0+ (1.0,0.0) [0.0|255.0] "Unitless" ETC
 SG_ DftlCtrlInfo26 : 55|8@0+ (1.0,0.0) [0.0|255.0] "Unitless" ETC
 SG_ DftlCtrlInfo27 : 63|8@0+ (1.0,0.0) [0.0|255.0] "Unitless" ETC

BO_ 1251 DemPropFr03: 8 DEM
 SG_ DftlCtrlInfo30 : 7|8@0+ (1.0,0.0) [0.0|255.0] "Unitless" ETC
 SG_ DftlCtrlInfo31 : 15|8@0+ (1.0,0.0) [0.0|255.0] "Unitless" ETC
 SG_ DftlCtrlInfo32 : 23|8@0+ (1.0,0.0) [0.0|255.0] "Unitless" ETC
 SG_ DftlCtrlInfo33 : 31|8@0+ (1.0,0.0) [0.0|255.0] "Unitless" ETC
 SG_ DftlCtrlInfo34 : 39|8@0+ (1.0,0.0) [0.0|255.0] "Unitless" ETC
 SG_ DftlCtrlInfo35 : 47|8@0+ (1.0,0.0) [0.0|255.0] "Unitless" ETC
 SG_ DftlCtrlInfo36 : 55|8@0+ (1.0,0.0) [0.0|255.0] "Unitless" ETC
 SG_ DftlCtrlInfo37 : 63|8@0+ (1.0,0.0) [0.0|255.0] "Unitless" ETC

BO_ 1252 DemPropFr04: 8 DEM
 SG_ DftlCtrlInfo40 : 7|8@0+ (1.0,0.0) [0.0|255.0] "Unitless" ETC
 SG_ DftlCtrlInfo41 : 15|8@0+ (1.0,0.0) [0.0|255.0] "Unitless" ETC
 SG_ DftlCtrlInfo42 : 23|8@0+ (1.0,0.0) [0.0|255.0] "Unitless" ETC
 SG_ DftlCtrlInfo43 : 31|8@0+ (1.0,0.0) [0.0|255.0] "Unitless" ETC
 SG_ DftlCtrlInfo44 : 39|8@0+ (1.0,0.0) [0.0|255.0] "Unitless" ETC
 SG_ DftlCtrlInfo45 : 47|8@0+ (1.0,0.0) [0.0|255.0] "Unitless" ETC
 SG_ DftlCtrlInfo46 : 55|8@0+ (1.0,0.0) [0.0|255.0] "Unitless" ETC
 SG_ DftlCtrlInfo47 : 63|8@0+ (1.0,0.0) [0.0|255.0] "Unitless" ETC

BO_ 1253 DemPropFr05: 8 DEM
 SG_ DftlCtrlInfo50 : 7|8@0+ (1.0,0.0) [0.0|255.0] "Unitless" ETC
 SG_ DftlCtrlInfo51 : 15|8@0+ (1.0,0.0) [0.0|255.0] "Unitless" ETC
 SG_ DftlCtrlInfo52 : 23|8@0+ (1.0,0.0) [0.0|255.0] "Unitless" ETC
 SG_ DftlCtrlInfo53 : 31|8@0+ (1.0,0.0) [0.0|255.0] "Unitless" ETC
 SG_ DftlCtrlInfo54 : 39|8@0+ (1.0,0.0) [0.0|255.0] "Unitless" ETC
 SG_ DftlCtrlInfo55 : 47|8@0+ (1.0,0.0) [0.0|255.0] "Unitless" ETC
 SG_ DftlCtrlInfo56 : 55|8@0+ (1.0,0.0) [0.0|255.0] "Unitless" ETC
 SG_ DftlCtrlInfo57 : 63|8@0+ (1.0,0.0) [0.0|255.0] "Unitless" ETC

BO_ 1254 DemPropFr06: 8 DEM
 SG_ DftlCtrlInfo60 : 7|8@0+ (1.0,0.0) [0.0|255.0] "Unitless" ETC
 SG_ DftlCtrlInfo61 : 15|8@0+ (1.0,0.0) [0.0|255.0] "Unitless" ETC
 SG_ DftlCtrlInfo62 : 23|8@0+ (1.0,0.0) [0.0|255.0] "Unitless" ETC
 SG_ DftlCtrlInfo63 : 31|8@0+ (1.0,0.0) [0.0|255.0] "Unitless" ETC
 SG_ DftlCtrlInfo64 : 39|8@0+ (1.0,0.0) [0.0|255.0] "Unitless" ETC
 SG_ DftlCtrlInfo65 : 47|8@0+ (1.0,0.0) [0.0|255.0] "Unitless" ETC
 SG_ DftlCtrlInfo66 : 55|8@0+ (1.0,0.0) [0.0|255.0] "Unitless" ETC
 SG_ DftlCtrlInfo67 : 63|8@0+ (1.0,0.0) [0.0|255.0] "Unitless" ETC

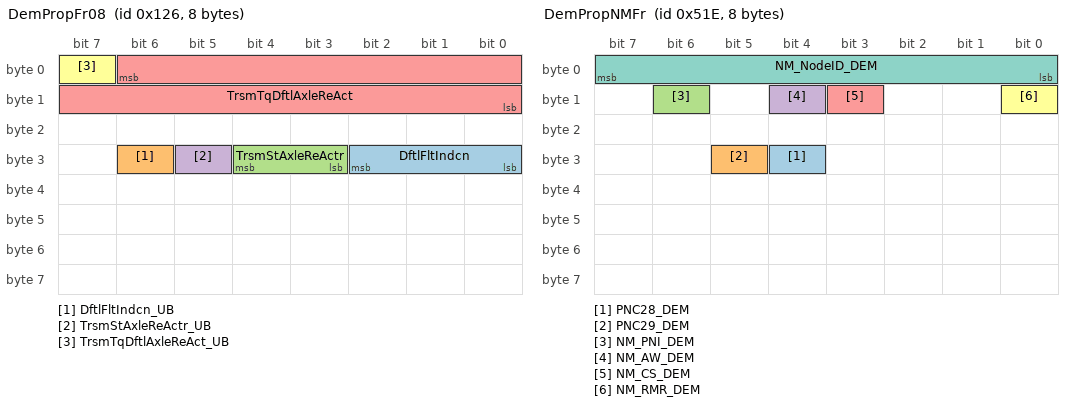
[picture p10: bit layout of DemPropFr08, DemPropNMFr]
BO_ 294 DemPropFr08: 8 DEM
 SG_ DftlFltIndcn : 26|3@0+ (1,0) [0|7] "" VDDM
 SG_ DftlFltIndcn_UB : 30|1@0+ (1,0) [0|1] "" VDDM
 SG_ TrsmStAxleReActr : 28|2@0+ (1,0) [0|3] "" ECM,VDDM
 SG_ TrsmStAxleReActr_UB : 29|1@0+ (1,0) [0|1] "" ECM,VDDM
 SG_ TrsmTqDftlAxleReAct : 6|15@0- (0.6103515625,0.0) [-10000.0|9999.3896484375] "NewtonMeter" ECM,TCM
 SG_ TrsmTqDftlAxleReAct_UB : 7|1@0+ (1,0) [0|1] "" ECM,TCM

BO_ 1310 DemPropNMFr: 8 DEM
 SG_ PNC28_DEM : 28|1@0+ (1,0) [0|0] "" Vector_XXX
 SG_ PNC29_DEM : 29|1@0+ (1,0) [0|0] "" Vector_XXX
 SG_ NM_PNI_DEM : 14|1@0+ (1,0) [0|0] "" Vector_XXX
 SG_ NM_AW_DEM : 12|1@0+ (1,0) [0|0] "" Vector_XXX
 SG_ NM_CS_DEM : 11|1@0+ (1,0) [0|0] "" Vector_XXX
 SG_ NM_RMR_DEM : 8|1@0+ (1,0) [0|0] "" Vector_XXX
 SG_ NM_NodeID_DEM : 7|8@0+ (1,0) [0|0] "" Vector_XXX

BO_ 1431 DEMtoETCXcpFr01: 8 DEM

BO_ 1432 DEMtoETCXcpFr02: 8 DEM

BO_ 1433 DEMtoETCXcpFr03: 8 DEM

BO_ 1434 DEMtoETCXcpFr04: 8 DEM

BO_ 1435 DEMtoETCXcpFr05: 8 DEM

BO_ 1436 DEMtoETCXcpFr06: 8 DEM

BO_ 1592 DemToVddmPropDiagResFrame: 8 DEM
 SG_ DemToVddmPropDiagResNpdu : 7|64@0+ (1,0) [0|0] "" VDDM

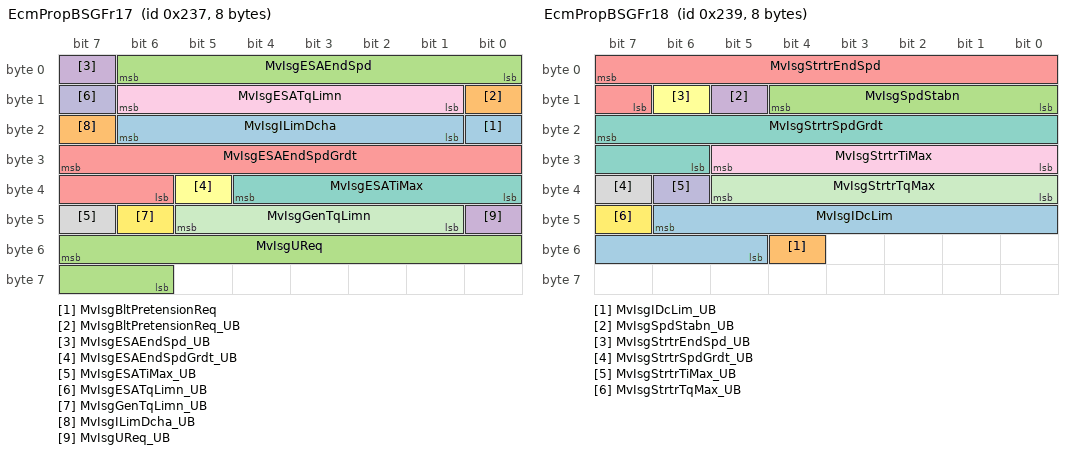
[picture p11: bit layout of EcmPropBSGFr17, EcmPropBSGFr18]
BO_ 567 EcmPropBSGFr17: 8 ECM
 SG_ MvIsgBltPretensionReq : 16|1@0+ (1,0) [0|1] "" ISGM
 SG_ MvIsgBltPretensionReq_UB : 8|1@0+ (1,0) [0|1] "" ISGM
 SG_ MvIsgESAEndSpd : 6|7@0+ (10.0,0.0) [0.0|1000.0] "rpm" ISGM
 SG_ MvIsgESAEndSpd_UB : 7|1@0+ (1,0) [0|1] "" ISGM
 SG_ MvIsgESAEndSpdGrdt : 31|10@0+ (-10.0,0.0) [-8000.0|0.0] "RpmPerSec" ISGM
 SG_ MvIsgESAEndSpdGrdt_UB : 37|1@0+ (1,0) [0|1] "" ISGM
 SG_ MvIsgESATiMax : 36|5@0+ (0.1,0.0) [0.0|2.0] "s" ISGM
 SG_ MvIsgESATiMax_UB : 47|1@0+ (1,0) [0|1] "" ISGM
 SG_ MvIsgESATqLimn : 14|6@0+ (-1.0,0.0) [-44.0|0.0] "NewtonMeter" ISGM
 SG_ MvIsgESATqLimn_UB : 15|1@0+ (1,0) [0|1] "" ISGM
 SG_ MvIsgGenTqLimn : 45|5@0+ (-1.0,0.0) [-30.0|0.0] "NewtonMeter" ISGM
 SG_ MvIsgGenTqLimn_UB : 46|1@0+ (1,0) [0|1] "" ISGM
 SG_ MvIsgILimDcha : 22|6@0+ (0.1,0.0) [0.0|5.0] "A" ISGM
 SG_ MvIsgILimDcha_UB : 23|1@0+ (1,0) [0|1] "" ISGM
 SG_ MvIsgUReq : 55|10@0+ (0.1,0.0) [0.0|102.30000000000001] "Volt" ISGM
 SG_ MvIsgUReq_UB : 40|1@0+ (1,0) [0|1] "" ISGM

BO_ 569 EcmPropBSGFr18: 8 ECM
 SG_ MvIsgIDcLim : 46|10@0+ (1.0,-410.0) [-410.0|410.0] "A" ISGM
 SG_ MvIsgIDcLim_UB : 52|1@0+ (1,0) [0|1] "" ISGM
 SG_ MvIsgSpdStabn : 12|5@0+ (0.1,0.0) [0.0|2.0] "s" ISGM
 SG_ MvIsgSpdStabn_UB : 13|1@0+ (1,0) [0|1] "" ISGM
 SG_ MvIsgStrtrEndSpd : 7|9@0+ (10.0,0.0) [0.0|3000.0] "rpm" ISGM
 SG_ MvIsgStrtrEndSpd_UB : 14|1@0+ (1,0) [0|1] "" ISGM
 SG_ MvIsgStrtrSpdGrdt : 23|10@0+ (10.0,0.0) [0.0|8000.0] "RpmPerSec" ISGM
 SG_ MvIsgStrtrSpdGrdt_UB : 39|1@0+ (1,0) [0|1] "" ISGM
 SG_ MvIsgStrtrTiMax : 29|6@0+ (0.1,0.0) [0.1|5.0] "s" ISGM
 SG_ MvIsgStrtrTiMax_UB : 38|1@0+ (1,0) [0|1] "" ISGM
 SG_ MvIsgStrtrTqMax : 37|6@0+ (1.0,0.0) [0.0|55.0] "NewtonMeter" ISGM
 SG_ MvIsgStrtrTqMax_UB : 47|1@0+ (1,0) [0|1] "" ISGM

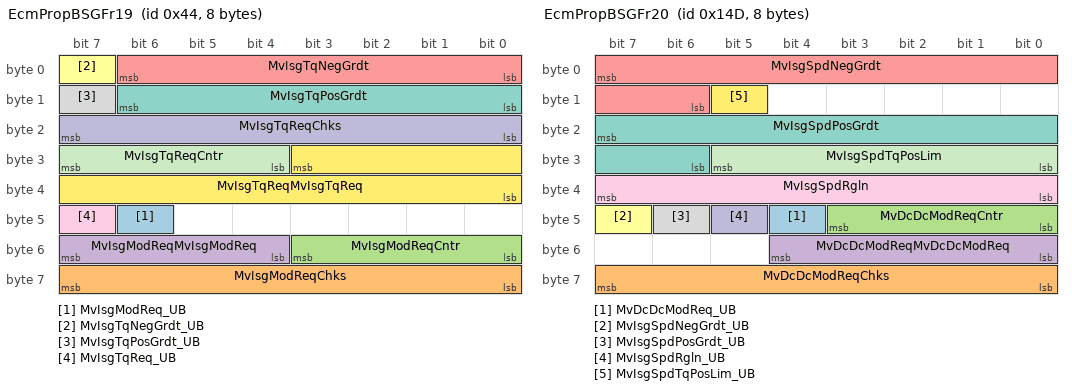
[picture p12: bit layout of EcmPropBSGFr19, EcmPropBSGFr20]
BO_ 68 EcmPropBSGFr19: 8 ECM
 SG_ MvIsgModReq_UB : 46|1@0+ (1,0) [0|1] "" ISGM
 SG_ MvIsgModReqChks : 63|8@0+ (1.0,0.0) [0.0|255.0] "Unitless" ISGM
 SG_ MvIsgModReqCntr : 51|4@0+ (1.0,0.0) [0.0|15.0] "Unitless" ISGM
 SG_ MvIsgModReqMvIsgModReq : 55|4@0+ (1,0) [0|15] "" ISGM
 SG_ MvIsgTqNegGrdt : 6|7@0+ (-10.0,0.0) [-1000.0|0.0] "Nm/s" ISGM
 SG_ MvIsgTqNegGrdt_UB : 7|1@0+ (1,0) [0|1] "" ISGM
 SG_ MvIsgTqPosGrdt : 14|7@0+ (10.0,0.0) [0.0|1000.0] "Nm/s" ISGM
 SG_ MvIsgTqPosGrdt_UB : 15|1@0+ (1,0) [0|1] "" ISGM
 SG_ MvIsgTqReq_UB : 47|1@0+ (1,0) [0|1] "" ISGM
 SG_ MvIsgTqReqChks : 23|8@0+ (1.0,0.0) [0.0|255.0] "Unitless" ISGM
 SG_ MvIsgTqReqCntr : 31|4@0+ (1.0,0.0) [0.0|15.0] "Unitless" ISGM
 SG_ MvIsgTqReqMvIsgTqReq : 27|12@0+ (0.1,-70.0) [-70.0|70.0] "NewtonMeter" ISGM

BO_ 333 EcmPropBSGFr20: 8 ECM
 SG_ MvDcDcModReq_UB : 44|1@0+ (1,0) [0|1] "" MVBM,MVCM
 SG_ MvDcDcModReqChks : 63|8@0+ (1.0,0.0) [0.0|255.0] "Unitless" MVBM,MVCM
 SG_ MvDcDcModReqCntr : 43|4@0+ (1.0,0.0) [0.0|15.0] "Unitless" MVBM,MVCM
 SG_ MvDcDcModReqMvDcDcModReq : 52|5@0+ (1,0) [0|31] "" MVBM,MVCM
 SG_ MvIsgSpdNegGrdt : 7|10@0+ (-10.0,0.0) [-8000.0|0.0] "RpmPerSec" ISGM
 SG_ MvIsgSpdNegGrdt_UB : 47|1@0+ (1,0) [0|1] "" ISGM
 SG_ MvIsgSpdPosGrdt : 23|10@0+ (10.0,0.0) [0.0|8000.0] "RpmPerSec" ISGM
 SG_ MvIsgSpdPosGrdt_UB : 46|1@0+ (1,0) [0|1] "" ISGM
 SG_ MvIsgSpdRgln : 39|8@0+ (50.0,0.0) [1500.0|12000.0] "rpm" ISGM
 SG_ MvIsgSpdRgln_UB : 45|1@0+ (1,0) [0|1] "" ISGM
 SG_ MvIsgSpdTqPosLim : 29|6@0+ (1.0,0.0) [0.0|44.0] "NewtonMeter" ISGM
 SG_ MvIsgSpdTqPosLim_UB : 13|1@0+ (1,0) [0|1] "" ISGM

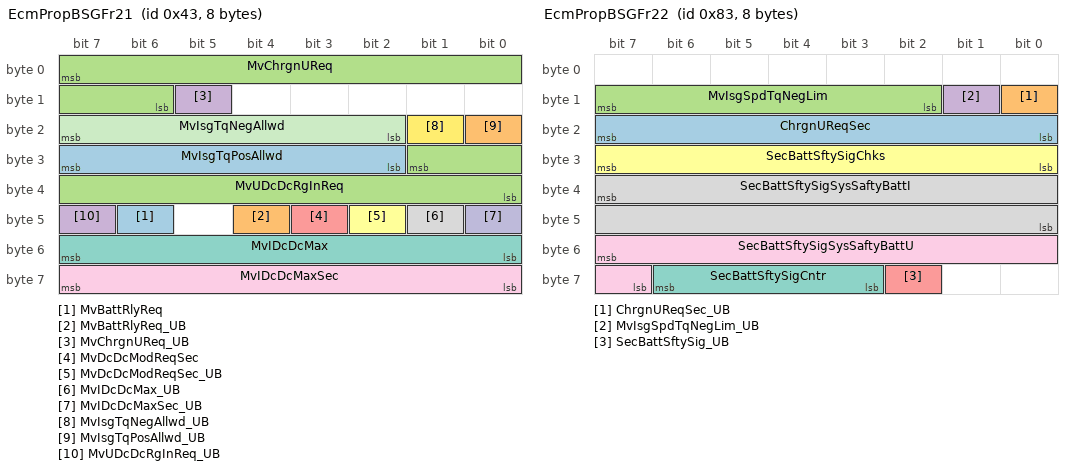
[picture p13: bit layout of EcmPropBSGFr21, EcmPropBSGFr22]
BO_ 67 EcmPropBSGFr21: 8 ECM
 SG_ MvBattRlyReq : 46|1@0+ (1,0) [0|1] "" MVBM
 SG_ MvBattRlyReq_UB : 44|1@0+ (1,0) [0|1] "" MVBM
 SG_ MvChrgnUReq : 7|10@0+ (0.1,0.0) [0.0|102.30000000000001] "Volt" MVCM
 SG_ MvChrgnUReq_UB : 13|1@0+ (1,0) [0|1] "" MVCM
 SG_ MvDcDcModReqSec : 43|1@0+ (1,0) [0|1] "" MVCM
 SG_ MvDcDcModReqSec_UB : 42|1@0+ (1,0) [0|1] "" MVCM
 SG_ MvIDcDcMax : 55|8@0+ (1.0,0.0) [0.0|255.0] "A" MVCM
 SG_ MvIDcDcMax_UB : 41|1@0+ (1,0) [0|1] "" MVCM
 SG_ MvIDcDcMaxSec : 63|8@0+ (1.0,0.0) [0.0|255.0] "A" MVCM
 SG_ MvIDcDcMaxSec_UB : 40|1@0+ (1,0) [0|1] "" MVCM
 SG_ MvIsgTqNegAllwd : 23|6@0+ (-1.0,0.0) [-44.0|0.0] "NewtonMeter" ISGM
 SG_ MvIsgTqNegAllwd_UB : 17|1@0+ (1,0) [0|1] "" ISGM
 SG_ MvIsgTqPosAllwd : 31|6@0+ (1.0,0.0) [0.0|55.0] "NewtonMeter" ISGM
 SG_ MvIsgTqPosAllwd_UB : 16|1@0+ (1,0) [0|1] "" ISGM
 SG_ MvUDcDcRgInReq : 25|10@0+ (0.1,0.0) [0.0|102.30000000000001] "Volt" MVCM
 SG_ MvUDcDcRgInReq_UB : 47|1@0+ (1,0) [0|1] "" MVCM

BO_ 131 EcmPropBSGFr22: 8 ECM
 SG_ ChrgnUReqSec : 23|8@0+ (0.025,10.6) [10.6|16.0] "Volt" MVCM
 SG_ ChrgnUReqSec_UB : 8|1@0+ (1,0) [0|1] "" MVCM
 SG_ MvIsgSpdTqNegLim : 15|6@0+ (-1.0,0.0) [-44.0|0.0] "NewtonMeter" ISGM
 SG_ MvIsgSpdTqNegLim_UB : 9|1@0+ (1,0) [0|1] "" ISGM
 SG_ SecBattSftySig_UB : 58|1@0+ (1,0) [0|1] "" MVCM
 SG_ SecBattSftySigChks : 31|8@0+ (1.0,0.0) [0.0|255.0] "Unitless" MVCM
 SG_ SecBattSftySigCntr : 62|4@0+ (1.0,0.0) [0.0|15.0] "Unitless" MVCM
 SG_ SecBattSftySigSysSaftyBattI : 39|16@0+ (0.015625,-512.0) [-512.0|511.984375] "A" MVCM
 SG_ SecBattSftySigSysSaftyBattU : 55|9@0+ (0.025,5.0) [5.0|17.775] "Volt" MVCM

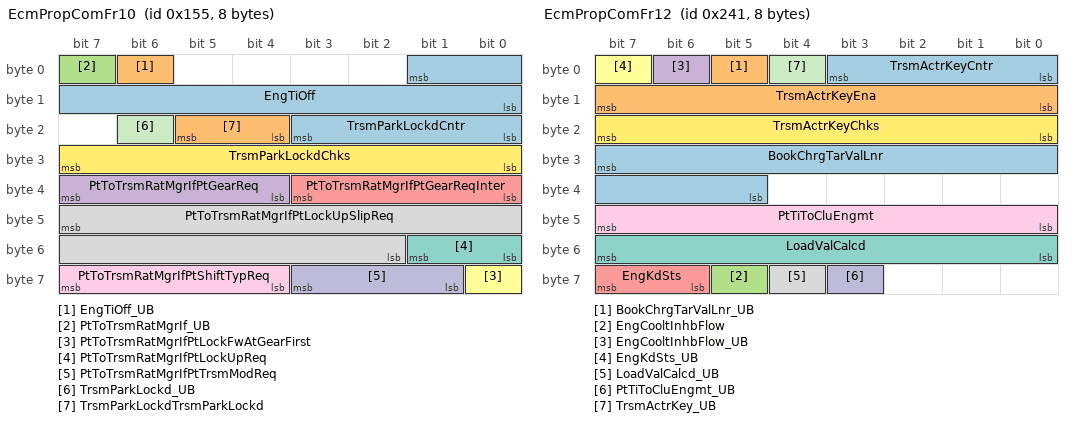
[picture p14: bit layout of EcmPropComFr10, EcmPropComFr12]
BO_ 341 EcmPropComFr10: 8 ECM
 SG_ EngTiOff : 1|10@0+ (1.0,0.0) [0.0|1023.0] "Mins" TCM
 SG_ EngTiOff_UB : 6|1@0+ (1,0) [0|1] "" TCM
 SG_ PtToTrsmRatMgrIf_UB : 7|1@0+ (1,0) [0|1] "" TCM
 SG_ PtToTrsmRatMgrIfPtGearReq : 39|4@0+ (1,0) [0|15] "" TCM
 SG_ PtToTrsmRatMgrIfPtGearReqInter : 35|4@0+ (1,0) [0|15] "" TCM
 SG_ PtToTrsmRatMgrIfPtLockFwAtGearFirst : 56|1@0+ (1,0) [0|1] "" TCM
 SG_ PtToTrsmRatMgrIfPtLockUpReq : 49|2@0+ (1,0) [0|3] "" TCM
 SG_ PtToTrsmRatMgrIfPtLockUpSlipReq : 47|14@0+ (1.0,-8191.0) [-8191.0|8192.0] "rpm" TCM
 SG_ PtToTrsmRatMgrIfPtShiftTypReq : 63|4@0+ (1,0) [0|15] "" TCM
 SG_ PtToTrsmRatMgrIfPtTrsmModReq : 59|3@0+ (1,0) [0|7] "" TCM
 SG_ TrsmParkLockd_UB : 22|1@0+ (1,0) [0|1] "" EGSM,TACM,TCM,VDDM
 SG_ TrsmParkLockdChks : 31|8@0+ (1.0,0.0) [0.0|255.0] "Unitless" EGSM,TACM,TCM,VDDM
 SG_ TrsmParkLockdCntr : 19|4@0+ (1.0,0.0) [0.0|15.0] "Unitless" EGSM,TACM,TCM,VDDM
 SG_ TrsmParkLockdTrsmParkLockd : 21|2@0+ (1,0) [0|3] "" EGSM,TACM,TCM,VDDM

BO_ 577 EcmPropComFr12: 8 ECM
 SG_ BookChrgTarValLnr : 31|11@0+ (0.05,0.0) [0.0|100.0] "%" BECM
 SG_ BookChrgTarValLnr_UB : 5|1@0+ (1,0) [0|1] "" BECM
 SG_ EngCooltInhbFlow : 61|1@0+ (1,0) [0|1] "" IGM
 SG_ EngCooltInhbFlow_UB : 6|1@0+ (1,0) [0|1] "" IGM
 SG_ EngKdSts : 63|2@0+ (1,0) [0|3] "" TCM
 SG_ EngKdSts_UB : 7|1@0+ (1,0) [0|1] "" TCM
 SG_ LoadValCalcd : 55|8@0+ (0.392156862745,0.0) [0.0|99.999999999975] "%" BECM,IEM,IGM,ISGM,MVBM,OBC,TCM,VDDM
 SG_ LoadValCalcd_UB : 60|1@0+ (1,0) [0|1] "" BECM,IEM,IGM,ISGM,MVBM,OBC,TCM,VDDM
 SG_ PtTiToCluEngmt : 47|8@0+ (0.01,0.0) [0.0|2.5500000000000003] "s" DEM,VDDM
 SG_ PtTiToCluEngmt_UB : 59|1@0+ (1,0) [0|1] "" DEM,VDDM
 SG_ TrsmActrKey_UB : 4|1@0+ (1,0) [0|1] "" TACM
 SG_ TrsmActrKeyChks : 23|8@0+ (1.0,0.0) [0.0|255.0] "Unitless" TACM
 SG_ TrsmActrKeyCntr : 3|4@0+ (1.0,0.0) [0.0|15.0] "Unitless" TACM
 SG_ TrsmActrKeyEna : 15|8@0+ (1.0,0.0) [0.0|255.0] "Unitless" TACM

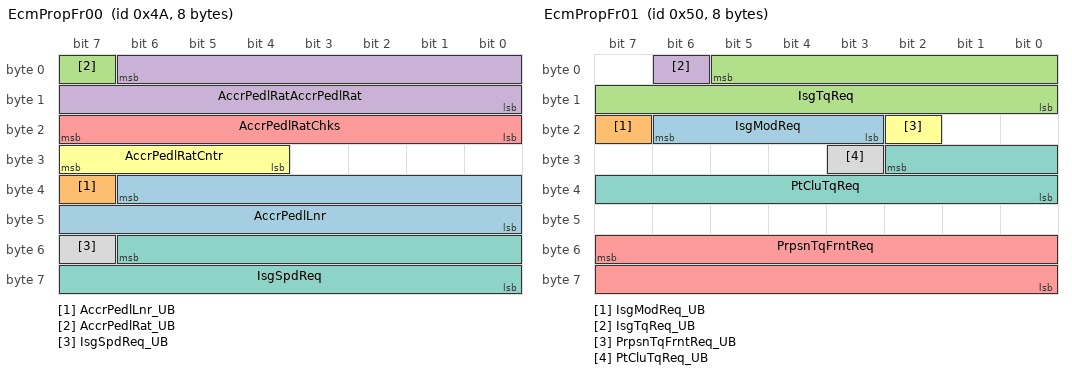
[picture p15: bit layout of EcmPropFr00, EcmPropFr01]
BO_ 74 EcmPropFr00: 8 ECM
 SG_ AccrPedlLnr : 38|15@0+ (0.00390625,0.0) [0.0|100.0] "%" TCM,VDDM
 SG_ AccrPedlLnr_UB : 39|1@0+ (1,0) [0|1] "" TCM,VDDM
 SG_ AccrPedlRat_UB : 7|1@0+ (1,0) [0|1] "" DEM,ESM,ISGM,MVBM,TCM,VDDM
 SG_ AccrPedlRatAccrPedlRat : 6|15@0+ (0.00390625,0.0) [0.0|100.0] "%" DEM,ESM,ISGM,MVBM,TCM,VDDM
 SG_ AccrPedlRatChks : 23|8@0+ (1.0,0.0) [0.0|255.0] "Unitless" DEM,ESM,ISGM,MVBM,TCM,VDDM
 SG_ AccrPedlRatCntr : 31|4@0+ (1.0,0.0) [0.0|15.0] "Unitless" DEM,ESM,ISGM,MVBM,TCM,VDDM
 SG_ IsgSpdReq : 54|15@0- (1.0,0.0) [-16384.0|16383.0] "rpm" IGM
 SG_ IsgSpdReq_UB : 55|1@0+ (1,0) [0|1] "" IGM

BO_ 80 EcmPropFr01: 8 ECM
 SG_ IsgModReq : 22|4@0+ (1,0) [0|15] "" IGM,VDDM
 SG_ IsgModReq_UB : 23|1@0+ (1,0) [0|1] "" IGM,VDDM
 SG_ IsgTqReq : 5|14@0+ (1.0,-8188.0) [-8188.0|8192.0] "NewtonMeter" IGM,VDDM
 SG_ IsgTqReq_UB : 6|1@0+ (1,0) [0|1] "" IGM,VDDM
 SG_ PrpsnTqFrntReq : 55|16@0- (1.0,0.0) [-20000.0|20000.0] "NewtonMeter" DEM,VDDM
 SG_ PrpsnTqFrntReq_UB : 18|1@0+ (1,0) [0|1] "" DEM,VDDM
 SG_ PtCluTqReq : 26|11@0+ (1.0,-1024.0) [-1024.0|1023.0] "NewtonMeter" TCM
 SG_ PtCluTqReq_UB : 27|1@0+ (1,0) [0|1] "" TCM

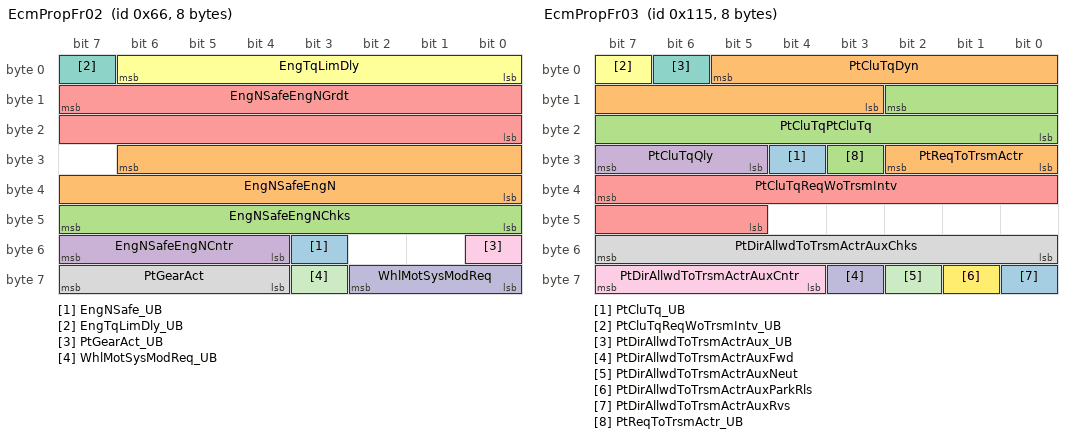
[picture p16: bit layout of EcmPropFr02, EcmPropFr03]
BO_ 102 EcmPropFr02: 8 ECM
 SG_ EngNSafe_UB : 51|1@0+ (1,0) [0|1] "" BECM,DEM,IEM,IGM,MVBM,OBC,TCM
 SG_ EngNSafeEngN : 30|15@0+ (0.5,0.0) [0.0|16383.5] "rpm" BECM,DEM,IEM,IGM,MVBM,OBC,TCM
 SG_ EngNSafeEngNChks : 47|8@0+ (1.0,0.0) [0.0|255.0] "Unitless" BECM,DEM,IEM,IGM,MVBM,OBC,TCM
 SG_ EngNSafeEngNCntr : 55|4@0+ (1.0,0.0) [0.0|15.0] "Unitless" BECM,DEM,IEM,IGM,MVBM,OBC,TCM
 SG_ EngNSafeEngNGrdt : 15|16@0- (1.0,0.0) [-30000.0|32767.0] "RpmPerSec" BECM,DEM,IEM,IGM,MVBM,OBC,TCM
 SG_ EngTqLimDly : 6|7@0+ (5.0,0.0) [0.0|635.0] "Milliseconds" TCM
 SG_ EngTqLimDly_UB : 7|1@0+ (1,0) [0|1] "" TCM
 SG_ PtGearAct : 63|4@0+ (1,0) [0|15] "" DEM,TCM,VDDM
 SG_ PtGearAct_UB : 48|1@0+ (1,0) [0|1] "" DEM,TCM,VDDM
 SG_ WhlMotSysModReq : 58|3@0+ (1,0) [0|7] "" IEM,VDDM
 SG_ WhlMotSysModReq_UB : 59|1@0+ (1,0) [0|1] "" IEM,VDDM

BO_ 277 EcmPropFr03: 8 ECM
 SG_ PtCluTq_UB : 28|1@0+ (1,0) [0|1] "" TCM,VDDM
 SG_ PtCluTqDyn : 5|11@0+ (1.0,-1024.0) [-1024.0|1023.0] "NewtonMeter" TCM,VDDM
 SG_ PtCluTqPtCluTq : 10|11@0+ (1.0,-1024.0) [-1024.0|1023.0] "NewtonMeter" TCM,VDDM
 SG_ PtCluTqQly : 31|3@0+ (1,0) [0|7] "" TCM,VDDM
 SG_ PtCluTqReqWoTrsmIntv : 39|11@0+ (1.0,-1024.0) [-1024.0|1023.0] "NewtonMeter" TCM
 SG_ PtCluTqReqWoTrsmIntv_UB : 7|1@0+ (1,0) [0|1] "" TCM
 SG_ PtDirAllwdToTrsmActrAux_UB : 6|1@0+ (1,0) [0|1] "" TCM
 SG_ PtDirAllwdToTrsmActrAuxChks : 55|8@0+ (1.0,0.0) [0.0|255.0] "Unitless" TCM
 SG_ PtDirAllwdToTrsmActrAuxCntr : 63|4@0+ (1.0,0.0) [0.0|15.0] "Unitless" TCM
 SG_ PtDirAllwdToTrsmActrAuxFwd : 59|1@0+ (1,0) [0|1] "" TCM
 SG_ PtDirAllwdToTrsmActrAuxNeut : 58|1@0+ (1,0) [0|1] "" TCM
 SG_ PtDirAllwdToTrsmActrAuxParkRls : 57|1@0+ (1,0) [0|1] "" TCM
 SG_ PtDirAllwdToTrsmActrAuxRvs : 56|1@0+ (1,0) [0|1] "" TCM
 SG_ PtReqToTrsmActr : 26|3@0+ (1,0) [0|7] "" TACM,VDDM
 SG_ PtReqToTrsmActr_UB : 27|1@0+ (1,0) [0|1] "" TACM,VDDM

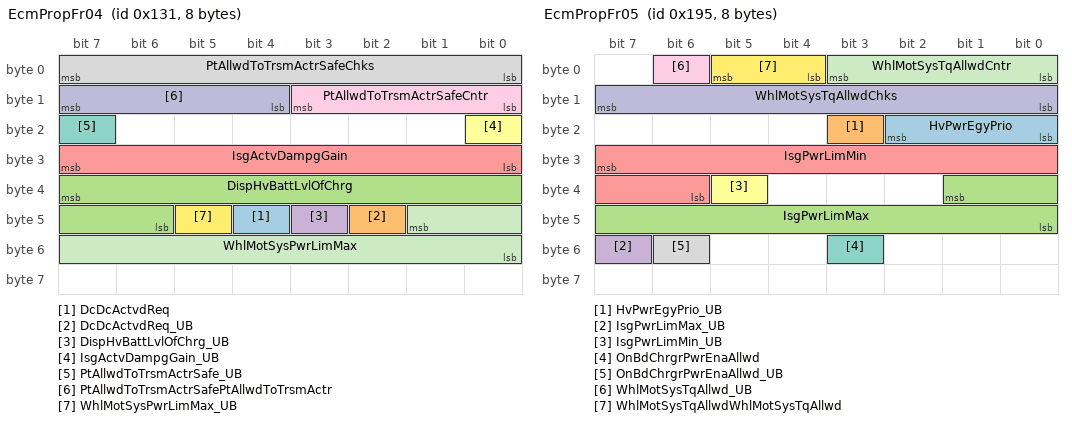
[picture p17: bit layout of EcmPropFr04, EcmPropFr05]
BO_ 305 EcmPropFr04: 8 ECM
 SG_ DcDcActvdReq : 44|1@0+ (1,0) [0|1] "" IGM,VDDM
 SG_ DcDcActvdReq_UB : 42|1@0+ (1,0) [0|1] "" IGM,VDDM
 SG_ DispHvBattLvlOfChrg : 39|10@0+ (0.1,0.0) [0.0|102.30000000000001] "%" BECM,OBC,VDDM
 SG_ DispHvBattLvlOfChrg_UB : 43|1@0+ (1,0) [0|1] "" BECM,OBC,VDDM
 SG_ IsgActvDampgGain : 31|8@0+ (0.0002,0.0) [0.0|0.051000000000000004] "Unitless" IGM
 SG_ IsgActvDampgGain_UB : 16|1@0+ (1,0) [0|1] "" IGM
 SG_ PtAllwdToTrsmActrSafe_UB : 23|1@0+ (1,0) [0|1] "" TACM,TCM,VDDM
 SG_ PtAllwdToTrsmActrSafeChks : 7|8@0+ (1.0,0.0) [0.0|255.0] "Unitless" TACM,TCM,VDDM
 SG_ PtAllwdToTrsmActrSafeCntr : 11|4@0+ (1.0,0.0) [0.0|15.0] "Unitless" TACM,TCM,VDDM
 SG_ PtAllwdToTrsmActrSafePtAllwdToTrsmActr : 15|4@0+ (1,0) [0|15] "" TACM,TCM,VDDM
 SG_ WhlMotSysPwrLimMax : 41|10@0+ (0.5,0.0) [0.0|511.0] "kW" IEM
 SG_ WhlMotSysPwrLimMax_UB : 45|1@0+ (1,0) [0|1] "" IEM

BO_ 405 EcmPropFr05: 8 ECM
 SG_ HvPwrEgyPrio : 18|3@0+ (1,0) [0|7] "" VDDM
 SG_ HvPwrEgyPrio_UB : 19|1@0+ (1,0) [0|1] "" VDDM
 SG_ IsgPwrLimMax : 33|10@0+ (0.5,0.0) [0.0|511.0] "kW" IGM
 SG_ IsgPwrLimMax_UB : 55|1@0+ (1,0) [0|1] "" IGM
 SG_ IsgPwrLimMin : 31|10@0+ (0.5,-511.0) [-511.0|0.0] "kW" IGM
 SG_ IsgPwrLimMin_UB : 37|1@0+ (1,0) [0|1] "" IGM
 SG_ OnBdChrgrPwrEnaAllwd : 51|1@0+ (1,0) [0|1] "" BECM,OBC,VDDM
 SG_ OnBdChrgrPwrEnaAllwd_UB : 54|1@0+ (1,0) [0|1] "" BECM,OBC,VDDM
 SG_ WhlMotSysTqAllwd_UB : 6|1@0+ (1,0) [0|1] "" IEM
 SG_ WhlMotSysTqAllwdChks : 15|8@0+ (1.0,0.0) [0.0|255.0] "Unitless" IEM
 SG_ WhlMotSysTqAllwdCntr : 3|4@0+ (1.0,0.0) [0.0|15.0] "Unitless" IEM
 SG_ WhlMotSysTqAllwdWhlMotSysTqAllwd : 5|2@0+ (1.0,0.0) [0.0|3.0] "Unitless" IEM

BO_ 816 EcmPropFr06: 8 ECM
 SG_ HvCooltHeatrStsSig : 15|3@0+ (1,0) [0|7] "" VDDM
 SG_ HvCooltHeatrStsSig_UB : 12|1@0+ (1,0) [0|1] "" VDDM
 SG_ HvCooltWtrHeatrWtrTInOutl : 7|8@0+ (1.0,-40.0) [-40.0|215.0] "degC" VDDM
 SG_ HvCooltWtrHeatrWtrTInOutl_UB : 11|1@0+ (1,0) [0|1] "" VDDM

BO_ 512 EcmPropFr07: 8 ECM
 SG_ PtTqAtWhlFrntAct_UB : 56|1@0+ (1,0) [0|1] "" DEM
 SG_ PtTqAtWhlFrntActPtTqAtWhlFrntAct : 7|16@0- (1.0,0.0) [-20000.0|20000.0] "NewtonMeter" DEM
 SG_ PtTqAtWhlFrntActPtTqAtWhlFrntLeAct : 23|16@0- (1.0,0.0) [-20000.0|20000.0] "NewtonMeter" DEM
 SG_ PtTqAtWhlFrntActPtTqAtWhlFrntQly : 59|3@0+ (1,0) [0|7] "" DEM
 SG_ PtTqAtWhlFrntActPtTqAtWhlFrntRiAct : 39|16@0- (1.0,0.0) [-20000.0|20000.0] "NewtonMeter" DEM
 SG_ PtTqAtWhlFrntActRecChks : 55|8@0+ (1.0,0.0) [0.0|255.0] "Unitless" DEM
 SG_ PtTqAtWhlFrntActRecCntr : 63|4@0+ (1.0,0.0) [0.0|15.0] "Unitless" DEM

BO_ 545 EcmPropFr08: 8 ECM
 SG_ EngNLim : 55|8@0+ (64.0,0.0) [0.0|16320.0] "rpm" TCM
 SG_ EngNLim_UB : 35|1@0+ (1,0) [0|1] "" TCM
 SG_ EngT_UB : 34|1@0+ (1,0) [0|1] "" BECM,IEM,IGM,ISGM,MVBM,OBC,TCM,VDDM
 SG_ EngTEngT : 47|8@0+ (1.0,-50.0) [-50.0|200.0] "degC" BECM,IEM,IGM,ISGM,MVBM,OBC,TCM,VDDM
 SG_ EngTQf : 33|2@0+ (1,0) [0|3] "" BECM,IEM,IGM,ISGM,MVBM,OBC,TCM,VDDM
 SG_ GearLvrEna : 11|1@0+ (1,0) [0|1] "" TCM
 SG_ GearLvrEna_UB : 10|1@0+ (1,0) [0|1] "" TCM
 SG_ HvBattCoolgCmd : 63|2@0+ (1,0) [0|3] "" BECM
 SG_ HvBattCoolgCmd_UB : 61|1@0+ (1,0) [0|1] "" BECM
 SG_ HvOnMaiReq : 60|2@0+ (1,0) [0|3] "" BECM,VDDM
 SG_ HvOnMaiReq_UB : 58|1@0+ (1,0) [0|1] "" BECM,VDDM
 SG_ IsgActvDampgModReq : 39|2@0+ (1,0) [0|3] "" IGM
 SG_ IsgActvDampgModReq_UB : 37|1@0+ (1,0) [0|1] "" IGM
 SG_ PrpsnFbLimnIndcn : 22|4@0+ (1.0,0.0) [0.0|15.0] "Unitless" BECM,IEM,IGM,TCM,VDDM
 SG_ PrpsnFbLimnIndcn_UB : 23|1@0+ (1,0) [0|1] "" BECM,IEM,IGM,TCM,VDDM
 SG_ PtRatMgrMod : 17|10@0+ (1.0,0.0) [0.0|1023.0] "Unitless" TCM
 SG_ PtRatMgrMod_UB : 18|1@0+ (1,0) [0|1] "" TCM
 SG_ ThrPos : 7|8@0+ (0.5,0.0) [0.0|100.0] "%" BECM,IEM,IGM,ISGM,MVBM,OBC,SRS,TCM,VDDM
 SG_ ThrPos_UB : 15|1@0+ (1,0) [0|1] "" BECM,IEM,IGM,ISGM,MVBM,OBC,SRS,TCM,VDDM
 SG_ WrmUpCyc : 9|1@0+ (1,0) [0|1] "" TCM,VDDM
 SG_ WrmUpCyc_UB : 8|1@0+ (1,0) [0|1] "" TCM,VDDM

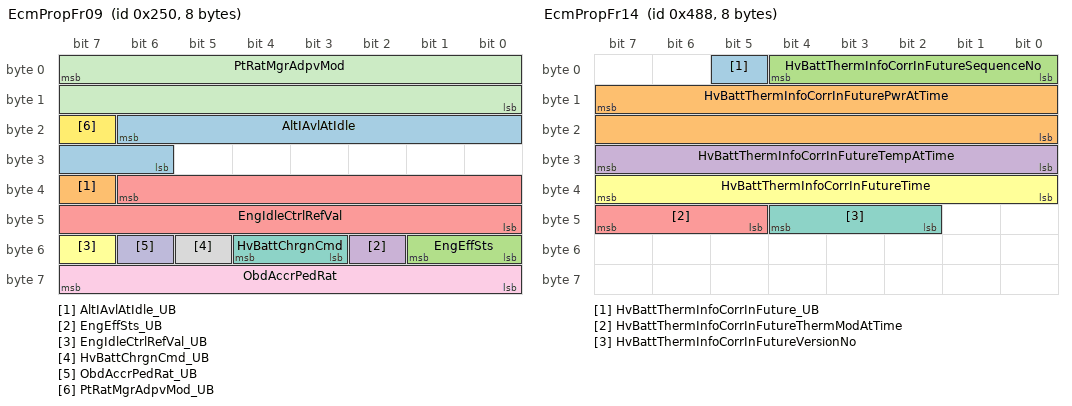
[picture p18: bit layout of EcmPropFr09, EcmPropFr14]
BO_ 592 EcmPropFr09: 8 ECM
 SG_ AltIAvlAtIdle : 22|9@0+ (1.0,0.0) [0.0|511.0] "A" VDDM
 SG_ AltIAvlAtIdle_UB : 39|1@0+ (1,0) [0|1] "" VDDM
 SG_ EngEffSts : 49|2@0+ (1,0) [0|3] "" VDDM
 SG_ EngEffSts_UB : 50|1@0+ (1,0) [0|1] "" VDDM
 SG_ EngIdleCtrlRefVal : 38|15@0+ (0.5,0.0) [0.0|16383.5] "rpm" TCM
 SG_ EngIdleCtrlRefVal_UB : 55|1@0+ (1,0) [0|1] "" TCM
 SG_ HvBattChrgnCmd : 52|2@0+ (1,0) [0|3] "" BECM
 SG_ HvBattChrgnCmd_UB : 53|1@0+ (1,0) [0|1] "" BECM
 SG_ ObdAccrPedRat : 63|8@0+ (0.3921568628,0.0) [0.0|100.00000001400001] "%" TCM,VDDM
 SG_ ObdAccrPedRat_UB : 54|1@0+ (1,0) [0|1] "" TCM,VDDM
 SG_ PtRatMgrAdpvMod : 7|16@0+ (1.0,0.0) [0.0|65535.0] "Unitless" TCM
 SG_ PtRatMgrAdpvMod_UB : 23|1@0+ (1,0) [0|1] "" TCM

BO_ 647 EcmPropFr11: 8 ECM
 SG_ BookChargeSetResponse : 62|2@0+ (1,0) [0|3] "" OBC,VDDM
 SG_ BookChargeSetResponse_UB : 56|1@0+ (1,0) [0|1] "" OBC,VDDM
 SG_ ChrgnSts : 44|3@0+ (1,0) [0|7] "" BECM,VDDM
 SG_ ChrgnSts_UB : 63|1@0+ (1,0) [0|1] "" BECM,VDDM
 SG_ CmptmtCoolgSts : 3|4@0+ (1,0) [0|15] "" BECM,VDDM
 SG_ CmptmtCoolgSts_UB : 4|1@0+ (1,0) [0|1] "" BECM,VDDM
 SG_ CooltFlowForDtElec : 41|9@0+ (0.1,0.0) [0.0|51.1] "L / min" IEM,IGM
 SG_ CooltFlowForDtElec_UB : 6|1@0+ (1,0) [0|1] "" IEM,IGM
 SG_ CooltTSigForDtElec : 39|11@0+ (0.1,-40.0) [-40.0|140.0] "degC" IEM,IGM,VDDM
 SG_ CooltTSigForDtElec_UB : 5|1@0+ (1,0) [0|1] "" IEM,IGM,VDDM
 SG_ DeactvtTestCom : 60|1@0+ (1,0) [0|1] "" OBC,VDDM
 SG_ DeactvtTestCom_UB : 57|1@0+ (1,0) [0|1] "" OBC,VDDM
 SG_ EngAmbTCalcd : 16|9@0+ (0.5,-60.0) [-60.0|195.5] "Unitless" BECM,TCM,VDDM
 SG_ EngAmbTCalcd_UB : 17|1@0+ (1,0) [0|1] "" BECM,TCM,VDDM
 SG_ HvConvPwrAllwd : 15|10@0+ (20.0,0.0) [0.0|20460.0] "W" IGM
 SG_ HvConvPwrAllwd_UB : 7|1@0+ (1,0) [0|1] "" IGM
 SG_ MonrCycCmpl : 18|1@0+ (1,0) [0|1] "" BECM,IEM,IGM,ISGM,MVBM,MVCM,OBC,TCM
 SG_ MonrCycCmpl_UB : 19|1@0+ (1,0) [0|1] "" BECM,IEM,IGM,ISGM,MVBM,MVCM,OBC,TCM
 SG_ PrpsnSysActv : 20|1@0+ (1,0) [0|1] "" BECM,ISGM,MVBM,MVCM,OBC,TCM
 SG_ PrpsnSysActv_UB : 21|1@0+ (1,0) [0|1] "" BECM,ISGM,MVBM,MVCM,OBC,TCM

BO_ 1160 EcmPropFr14: 8 ECM
 SG_ HvBattThermInfoCorrInFuture_UB : 5|1@0+ (1,0) [0|1] "" VDDM
 SG_ HvBattThermInfoCorrInFuturePwrAtTime : 15|16@0+ (50.0,-25000.0) [-25000.0|25000.0] "W" VDDM
 SG_ HvBattThermInfoCorrInFutureSequenceNo : 4|5@0+ (1.0,0.0) [0.0|31.0] "Unitless" VDDM
 SG_ HvBattThermInfoCorrInFutureTempAtTime : 31|8@0+ (1.0,-50.0) [-50.0|205.0] "degC" VDDM
 SG_ HvBattThermInfoCorrInFutureThermModAtTime : 47|3@0+ (1,0) [0|7] "" VDDM
 SG_ HvBattThermInfoCorrInFutureTime : 39|8@0+ (1.0,0.0) [0.0|255.0] "Unitless" VDDM
 SG_ HvBattThermInfoCorrInFutureVersionNo : 44|3@0+ (1.0,0.0) [0.0|7.0] "Unitless" VDDM

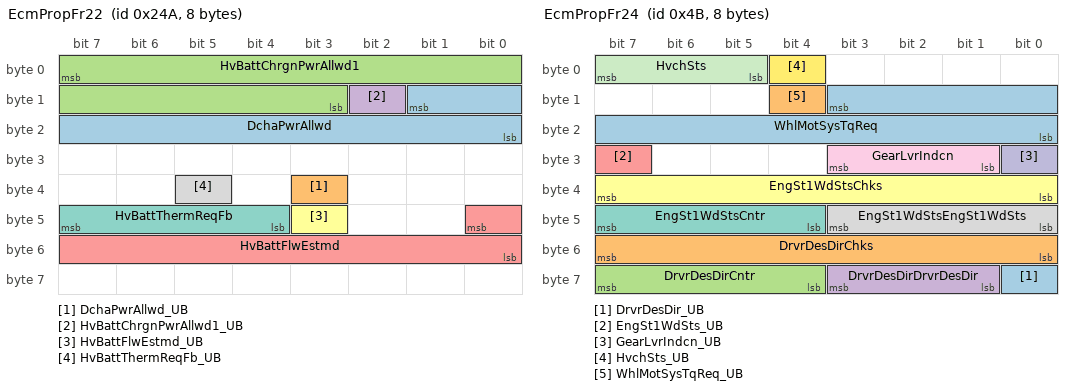
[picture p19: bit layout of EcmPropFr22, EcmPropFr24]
BO_ 586 EcmPropFr22: 8 ECM
 SG_ DchaPwrAllwd : 9|10@0+ (20.0,0.0) [0.0|20460.0] "W" OBC
 SG_ DchaPwrAllwd_UB : 35|1@0+ (1,0) [0|1] "" OBC
 SG_ HvBattChrgnPwrAllwd1 : 7|13@0+ (20.0,0.0) [0.0|163820.0] "W" BECM
 SG_ HvBattChrgnPwrAllwd1_UB : 10|1@0+ (1,0) [0|1] "" BECM
 SG_ HvBattFlwEstmd : 40|9@0+ (0.1,0.0) [0.0|51.1] "L / min" BECM
 SG_ HvBattFlwEstmd_UB : 43|1@0+ (1,0) [0|1] "" BECM
 SG_ HvBattThermReqFb : 47|4@0+ (1,0) [0|15] "" BECM,VDDM
 SG_ HvBattThermReqFb_UB : 37|1@0+ (1,0) [0|1] "" BECM,VDDM

BO_ 75 EcmPropFr24: 8 ECM
 SG_ DrvrDesDir_UB : 56|1@0+ (1,0) [0|1] "" ESM,VDDM
 SG_ DrvrDesDirChks : 55|8@0+ (1.0,0.0) [0.0|255.0] "Unitless" ESM,VDDM
 SG_ DrvrDesDirCntr : 63|4@0+ (1.0,0.0) [0.0|15.0] "Unitless" ESM,VDDM
 SG_ DrvrDesDirDrvrDesDir : 59|3@0+ (1,0) [0|7] "" ESM,VDDM
 SG_ EngSt1WdSts_UB : 31|1@0+ (1,0) [0|1] "" BECM,ESM,IEM,IGM,ISGM,MVBM,MVCM
 SG_ EngSt1WdStsChks : 39|8@0+ (1.0,0.0) [0.0|255.0] "Unitless" BECM,ESM,IEM,IGM,ISGM,MVBM,MVCM
 SG_ EngSt1WdStsCntr : 47|4@0+ (1.0,0.0) [0.0|15.0] "Unitless" BECM,ESM,IEM,IGM,ISGM,MVBM,MVCM
 SG_ EngSt1WdStsEngSt1WdSts : 43|4@0+ (1,0) [0|15] "" BECM,ESM,IEM,IGM,ISGM,MVBM,MVCM
 SG_ GearLvrIndcn : 27|3@0+ (1,0) [0|7] "" EGSM
 SG_ GearLvrIndcn_UB : 24|1@0+ (1,0) [0|1] "" EGSM
 SG_ HvchSts : 7|3@0+ (1,0) [0|7] "" BECM,VDDM
 SG_ HvchSts_UB : 4|1@0+ (1,0) [0|1] "" BECM,VDDM
 SG_ WhlMotSysTqReq : 11|12@0+ (4.0,-8188.0) [-8188.0|8192.0] "NewtonMeter" IEM,VDDM
 SG_ WhlMotSysTqReq_UB : 12|1@0+ (1,0) [0|1] "" IEM,VDDM

BO_ 2026 MvbmToVgmJ1979OBDPropCanResFrame11: 8 MVBM
 SG_ MvbmToVgmJ1979OBDPropCanResNpdu11 : 7|64@0+ (1,0) [0|0] "" VGM

// Node Comments
CM_ BU_ BECM "Battery Energy Control Module";
CM_ BU_ DEM "Differential Electronic Module";
CM_ BU_ ECM "Engine Control Module";
CM_ BU_ EGSM "Electronic Gear Selector Module";
CM_ BU_ ESM "Exterior Sound Module ";
CM_ BU_ ETC "External Tester Connector";
CM_ BU_ IEM "Inverter Electric rear axle drive Module";
CM_ BU_ IGM "Inverter Generator Module";
CM_ BU_ SRS "Supplementary Restraint System";
CM_ BU_ TACM "Transmission Actuator Control Module ";
CM_ BU_ VDDM "Vehicle Dynamics Domain Master
";
CM_ BU_ VGM "Vehicle Connectivity Module";

// Signal Comments
CM_ SG_ 321 HvBattUDc "Actual Hv Battery pack voltage (measuered before contactors, i.e. always giving pack voltage).";
CM_ SG_ 321 HvBattUDynMaxLim "The pack voltage high limit of the Hv Battery, dynamically based on cell voltage distribution. At pack voltages above this limit, there is risk for contactor openeing due to too high cell voltage. ";
CM_ SG_ 321 HvSysActvnInhb "Closing of the contactors is inhibited due to Hv System fault or safety issue.Ok: No fault/issue present,contactors are allowed to be closed.NotOk: Fault/issue present, contactors are inhibited to close.";
CM_ SG_ 321 HvSysPwrOff "Informs vehicle that Hv contactors will open in 2s due to Hv System fault or safety issue (BPO).
Ok: No fault present, contactor will not open.
NotOk: Fault present, contactors will open.";
CM_ SG_ 321 HvSysRlyStsChks "Counter for E2E";
CM_ SG_ 321 HvSysRlyStsCntr "Checksum for E2E";
CM_ SG_ 321 HvSysRlyStsHvSysRlySts "Actual state of the main contactors.";
CM_ SG_ 321 HvSysSts "Hv System Status during integrity test. Informs vehicle that longer Hv System start up time is necessary to perform Extended Integrity Test due to Hv System fault or safety issue.";
CM_ SG_ 373 ACChrgnConnectSts "AC charging/discharging connection status";
CM_ SG_ 373 ACChrgnCPSts "CP status";
CM_ SG_ 373 ACChrgnCurrentLimn "AC charging current limitation";
CM_ SG_ 373 ACChrgnIfErr "AC charging or discharging interface status";
CM_ SG_ 373 ACChrgnS2Sts "S2 switch open or close status";
CM_ SG_ 373 HvBattLimnIndcnChks "Checksum for E2E";
CM_ SG_ 373 HvBattLimnIndcnCntr "Counter for E2E";
CM_ SG_ 373 HvBattLimnIndcnHvBattLimnIndcn "Propulsion related Limited Operation Strategy information from Hv Battery. LOS";
CM_ SG_ 373 HvBattUDynMinLim "The pack voltage low limit of the Hv Battery, dynamically based on cell voltage distribution. At pack voltages below this limit, there is risk for contactor openeing due to too low cell voltage";
CM_ SG_ 373 MaintainBattTFb "Battery temperature maintain function control feedback.";
CM_ SG_ 581 HvBattChrgnCmpl "Plug-in charging of the Hv Battery is completed/not completed.";
CM_ SG_ 581 HvBattCoolgReq "Hv Battery request level for cooling .";
CM_ SG_ 581 HvBattILim "Maximum current limit for Hv Battery plug-in charging. Is also used for controlling the charging sequence.";
CM_ SG_ 581 HvBattSoc "Actual state of charge of the Hv Battery.";
CM_ SG_ 581 HvBattULim "Maximum voltage limit for Hv Battery plug-in charging. Is also used for controlling the charging sequence.";
CM_ SG_ 581 HvSysLimnIndcn "Propulsion related LOS (Limited Operation Strategy) information from Hv System.";
CM_ SG_ 659 HvBattEgyCdn "Hv Battery State-of-Health Energy, i.e. ratio of current maximum energy capacity versus that at beginning of life.SOH";
CM_ SG_ 659 HvBattErrIndcnReq "MIL ilumination req from BECU ";
CM_ SG_ 659 HvBattHeatgReq "Hv Battery request level for heating.";
CM_ SG_ 659 HvBattSocLimHi "Upper Hv Battery SOC soft limit: Up to this point nominal power available, linear charge power limit decrease between this limit and HvBattSocLimMax.";
CM_ SG_ 659 HvBattSocLimLo "Lower Hv Battery SOC soft limit: Down to this point nominal power available, linear discharge power limit decrease between this limit and HvBattSocLimMin.";
CM_ SG_ 659 HvBattSocLimMax "Maximum allowable state of charge of the Hv Battery. Used for protection of Hv Battery System.";
CM_ SG_ 659 HvBattSocLimMin "Minimum allowable state of charge of the high voltage battery.   Used for protection of Traction Battery System.";
CM_ SG_ 661 HvBattCoolgSts "Hv Battery cooling request as part of the HVEPM energy prioritization.";
CM_ SG_ 661 HVIL1Sts "HVIL status of Hv Battery connectors";
CM_ SG_ 661 HVIL2Sts "HVIL status of other HV component connectors except Hv Battery ";
CM_ SG_ 661 HVIL3Sts "HVIL status of other HV component connectors except Hv Battery ";
CM_ SG_ 661 HvIsoSts "Isolation status of Hv Battery or Hv System.";
CM_ SG_ 661 HvSysCrashFb "Isolation resistance status after crash: Idle, Ok, Evaluating, Nok.";
CM_ SG_ 662 FastChrgnLockCtrl "Fast charging port locking control request. Off is unlock,on is lock.";
CM_ SG_ 662 HvBattCooltTReq "HvBatt requested coolant temperature.";
CM_ SG_ 834 HvBattCodLen "The coding length of pack";
CM_ SG_ 834 HvBattMismatchFlt "the fault of BMSH Battery Mismatching";
CM_ SG_ 834 HvBattNr "the number of the battery subsystem";
CM_ SG_ 834 HvCellTDifFlt "the fault of BMSH CellTemp Uniformity";
CM_ SG_ 834 HvCellTOverFlt "the fault of BMSH Over Temperature";
CM_ SG_ 834 HvCellUDifFlt "the fault of BMSH CellVolt Uniformity";
CM_ SG_ 834 HvCellUOverFlt "the fault of BMSH Cell OverVoltage";
CM_ SG_ 834 HvCellUUnderFlt "the fault of BMSH Cell underVoltage";
CM_ SG_ 834 HvilFlt "the fault of VCU TBOX HVILState";
CM_ SG_ 834 HvIsoFlt "the fault of BMSH InsulationRes Fault";
CM_ SG_ 834 HvPackOverChrgFlt "the fault of BMSH Pack Overcharge";
CM_ SG_ 834 HvPackUOverFlt "the fault of BMSH Pack OverVoltage";
CM_ SG_ 834 HvPackUUnderFlt "the fault of BMSH Pack UnderVoltage";
CM_ SG_ 834 HvSocHiFlt "the fualt of BMSH Over SOC";
CM_ SG_ 834 HvSocHopFlt "the fault of BMSH SOC Hop";
CM_ SG_ 834 HvSocLoFlt "the fualt of BMSH Low SOC";
CM_ SG_ 789 HvBattChrgnSts "Hv Battery charging request as part of the HVEPM energy prioritization ";
CM_ SG_ 789 HvBattTAvg " High Voltage Battery Average Cell Temperature";
CM_ SG_ 789 HvBattTMax "High Voltage Battery Max Cell Temperature";
CM_ SG_ 789 HvBattTMin "High Voltage Battery Min Cell Temperature";
CM_ SG_ 817 HvBattCoolgEgyReq1 "Estimated energy required to cool Hv Battery to target temperature. Part of the HVEPM interface.";
CM_ SG_ 817 HvBattCooltFlowReq "Estimated coolant flow in the Hv Battery Coolant circuit. The estimate is based on pump speed and coolant temperature input";
CM_ SG_ 817 HvBattCooltT "Hv Battery coolant temperature as measured at battery inlet.";
CM_ SG_ 769 HvBattPwrCdn "Hv Battery State-of-Health Power, i.e. ratio of current maximum power capacity versus that at beginning of life. SOH power";
CM_ SG_ 664 HvBattChrgnPwrCns1 "Reports the Hv Battery actual power consumption as part of the HVEPM interface.";
CM_ SG_ 664 HvBattChrgnPwrCritDes1 "Hv Battery critically desired charging power as part of the HVEPM interface.Battery critically";
CM_ SG_ 664 HvBattChrgnPwrNormDes1 "Hv Battery desired charging power as part of the HVEPM interface.";
CM_ SG_ 664 HvBattEgyAvlChrg1 "Usable charge energy up to SOC max limit.";
CM_ SG_ 646 HvBattEgyAvlDcha1 "Usable discharge energy down to SOC low limit ";
CM_ SG_ 646 HvBattHeatGenn "An estimated heat generation in the component. This is used to predict the cooling need.";
CM_ SG_ 646 HvBattPreHeatFaild "Hv Battery charging preheating failed due to small charging power of OBC.";
CM_ SG_ 646 PackNr "the serial number of the pack subsystem";
CM_ SG_ 323 DCChrgnHndlSts "Fast charging gun connect state";
CM_ SG_ 323 HvBattIDc1 "Hv Battery current. Positive current is discharging the battery.";
CM_ SG_ 323 HvBattPwrLimChrg1 "Amount of power that the Hv Battery can receive (i.e. max charge power limit).";
CM_ SG_ 323 HvBattPwrLimDcha1 "Amount of power that the Hv Battery can provide (i.e. max discharge power limit).";
CM_ SG_ 323 HvBattPwrLimDchaSoft "Long time horizon discharge power limit for drivability ";
CM_ SG_ 833 HvBattClimaPwr "A continuos estimated battery climatization performance shall be estimated and published by HvBattClimaPwr.";
CM_ SG_ 833 HvBattClrRdyReq "HvBattClrRdyReq is used to clear all DTCs after a reprogramming event.";
CM_ SG_ 833 HvBattHeatgEgyReq "Estimated energy required to cool Hv Battery to target temperature. Part of the HVEPM interface.";
CM_ SG_ 837 HvBattCellTNr "the total number of all cell temperature sensors";
CM_ SG_ 837 HvBattCooltMaxTReq "The maximal coolant temperature be requested";
CM_ SG_ 837 HvBattCooltMinTReq "The minimal coolant temperature be requested.";
CM_ SG_ 837 HvBattPreHeatgReq "Battery preheating request before charging.";
CM_ SG_ 837 HvBattThermMod "Hv battery thermal management mode";
CM_ SG_ 837 HvBattTMaxSerlNr "the serial number of the max celltemperature subsystem";
CM_ SG_ 837 HvBattTMinSerlNr "the serial number of the min celltemperature subsystem";
CM_ SG_ 838 HvBattCooltLvl "HV battery coolant level";
CM_ SG_ 838 HvBattCooltOutletT "Hv Battery coolant temperature as measured at battery Outlet.";
CM_ SG_ 838 HvBattHeatgPwr "A continuos estimated battery heating performance shall be estimated and published by HvBattHeatgPwr, ";
CM_ SG_ 838 HvBattVoltMaxSerlNr "the serial number of the max cellvoltage subsystem";
CM_ SG_ 838 HvBattVoltMinSerlNr "the serial number of the min cellvoltage subsystem";
CM_ SG_ 839 HvBattCodPackCodeX1 "Pack code X1/X7/X13/X19";
CM_ SG_ 839 HvBattCodPackCodeX2 "Pack code X2/X8/X14/X20";
CM_ SG_ 839 HvBattCodPackCodeX3 "Pack code X3/X9/X15/X21";
CM_ SG_ 839 HvBattCodPackCodeX4 "Pack code X4/X10/X16/22";
CM_ SG_ 839 HvBattCodPackCodeX5 "Pack code X5/X11/X17/X23";
CM_ SG_ 839 HvBattCodPackCodeX6 "Pack code X6/X12/18/24";
CM_ SG_ 839 HvBattCodPackIndex "message pack index";
CM_ SG_ 325 CellUMax "Highest voltage currently measured in any cell of the HV battery";
CM_ SG_ 325 CellUMaxId "Number of the HV-battery cell which currently has the highest measured voltage. ";
CM_ SG_ 325 CellUMaxLim "The limiting of highest cell voltage for charging.";
CM_ SG_ 325 CellUMin "Lowest voltage currently measured in any cell of the HV battery";
CM_ SG_ 325 CellUMinId "Number of the HV-battery cell which currently has the lowest measured voltage.";
CM_ SG_ 648 ACChrgnProximityDetn "AC charging/discharging proximity resistor value";
CM_ SG_ 648 ChrgnDchaTyp "Charging type";
CM_ SG_ 648 DCChrgSt "DC charging state";
CM_ SG_ 648 FastChrgnLEDIndctn "The fast charging indicator state .";
CM_ SG_ 648 HvBattChrgnTiEstimd "The estimated charging time left.";
CM_ SG_ 648 HvBattWMDSts "The working state of BECM.";
CM_ SG_ 648 HvIsoR "BMSH Pack InsulationRes";
CM_ SG_ 83 ChrgEquipIDc "The maximal output current from DC charging equipment .";
CM_ SG_ 83 CpAmp "CP amplitude signal";
CM_ SG_ 83 CpDuty "CP duty signal";
CM_ SG_ 322 HvBattCellUInfoU1 "message pack index";
CM_ SG_ 322 HvBattCellUInfoU2 "total pack data number";
CM_ SG_ 322 HvBattCellUInfoU3 "U3 is Cell Total Num(for the first message) U3 is The number of cell that has the maximal voltage in pack(for the second message) U3 is The number of cell that has the minimal voltage in  pack(for the third message) U3 is The cell voltage number(for the fourth,fifth...message) ";
CM_ SG_ 322 HvBattCellUInfoU4 "U4 is The battery voltage (for the first message)U4 is The maximal cell voltage value in pack  (for the second message)U4 is The minimal cell voltage value in pack  (for the third message)U4 is The cell voltage(for the fourth,fifth...message) ";
CM_ SG_ 656 HvBattCellTInfoHvBattSnsrT "The cell temperature of Hv battery";
CM_ SG_ 656 HvBattCellTInfoHvBattTMax "High Voltage Battery Max Cell Temperature";
CM_ SG_ 656 HvBattCellTInfoHvBattTMin "High Voltage Battery Min Cell Temperature";
CM_ SG_ 656 HvBattCellTInfoHvBattTSnsrNr "Hv battery temperature sensor number";
CM_ SG_ 656 HvBattCellTInfoHvTempSnsrTMaxsSerlNr "The serial number of max temperature sensor in Hv battery";
CM_ SG_ 656 HvBattCellTInfoHvTempSnsrTMinSerlNr "The serial number of min temperature sensor in Hv battery";
CM_ SG_ 654 OnceChrgnEgy "Charge energy of each charging event (Ah)";
CM_ SG_ 654 OnceDchaEgy "Discharge energy during every two charging events (Ah)";
CM_ SG_ 1177 HvBattCap "Rated capacity of the battery.";
CM_ SG_ 1177 TotChrgCap "Total accumulated charge capacity,only for plug-in charging.";
CM_ SG_ 1180 TotDchaCap "Total accumulated discharge capacity,except charging.";
CM_ SG_ 1161 HvBattThermInfoInFuturePwrAtTime "The power required for HV battery thermal managemnt in the future";
CM_ SG_ 1161 HvBattThermInfoInFutureSequenceNo "Data sequence number";
CM_ SG_ 1161 HvBattThermInfoInFutureTempAtTime "Hv Battery temperature in the future";
CM_ SG_ 1161 HvBattThermInfoInFutureThermModAtTime "The  HV battery thermal managemnt  mode in the future";
CM_ SG_ 1161 HvBattThermInfoInFutureTime "Time in the future";
CM_ SG_ 1161 HvBattThermInfoInFutureVersionNo "Data version number";
CM_ SG_ 1345 VFCVectorBECMBlockID "Block Identifier";
CM_ SG_ 1345 VFCVectorBECMVFCid0 "AdjustableDriveControls";
CM_ SG_ 1345 VFCVectorBECMVFCid1 "ParkingDrivingClimatization";
CM_ SG_ 1345 VFCVectorBECMVFCid10 "ExteriorLighting";
CM_ SG_ 1345 VFCVectorBECMVFCid11 "Reserved";
CM_ SG_ 1345 VFCVectorBECMVFCid12 "Alarm";
CM_ SG_ 1345 VFCVectorBECMVFCid13 "Reserved";
CM_ SG_ 1345 VFCVectorBECMVFCid14 "InteriorLighting";
CM_ SG_ 1345 VFCVectorBECMVFCid15 "InteriorLightingEntrance";
CM_ SG_ 1345 VFCVectorBECMVFCid16 "Locking";
CM_ SG_ 1345 VFCVectorBECMVFCid17 "RemoteKey";
CM_ SG_ 1345 VFCVectorBECMVFCid18 "PropulsionStart";
CM_ SG_ 1345 VFCVectorBECMVFCid19 "PassiveSafetyAndRestraints";
CM_ SG_ 1345 VFCVectorBECMVFCid2 "PostClimatisation";
CM_ SG_ 1345 VFCVectorBECMVFCid20 "Reserved";
CM_ SG_ 1345 VFCVectorBECMVFCid21 "PowerOperatedTailgate";
CM_ SG_ 1345 VFCVectorBECMVFCid22 "VehicleDriving";
CM_ SG_ 1345 VFCVectorBECMVFCid23 "Reserved";
CM_ SG_ 1345 VFCVectorBECMVFCid24 "UserProfileInput";
CM_ SG_ 1345 VFCVectorBECMVFCid25 "SeatComfortFunctions";
CM_ SG_ 1345 VFCVectorBECMVFCid26 "Brake";
CM_ SG_ 1345 VFCVectorBECMVFCid27 "InformationPoll";
CM_ SG_ 1345 VFCVectorBECMVFCid28 "HVEnergyStorage";
CM_ SG_ 1345 VFCVectorBECMVFCid29 "Reserved";
CM_ SG_ 1345 VFCVectorBECMVFCid3 "PowertrainParkingClimatization";
CM_ SG_ 1345 VFCVectorBECMVFCid30 "TelematicsConnectivity";
CM_ SG_ 1345 VFCVectorBECMVFCid31 "Reserved";
CM_ SG_ 1345 VFCVectorBECMVFCid32 "Entertainment";
CM_ SG_ 1345 VFCVectorBECMVFCid33 "Diagnostics";
CM_ SG_ 1345 VFCVectorBECMVFCid34 "AllECUs";
CM_ SG_ 1345 VFCVectorBECMVFCid35 "TrailerCaravanFunctions";
CM_ SG_ 1345 VFCVectorBECMVFCid36 "Immobilizer";
CM_ SG_ 1345 VFCVectorBECMVFCid37 "Windows";
CM_ SG_ 1345 VFCVectorBECMVFCid38 "Visibility";
CM_ SG_ 1345 VFCVectorBECMVFCid39 "WarningSounds";
CM_ SG_ 1345 VFCVectorBECMVFCid4 "Reserved";
CM_ SG_ 1345 VFCVectorBECMVFCid40 "Entrance";
CM_ SG_ 1345 VFCVectorBECMVFCid41 "InfotainmentPush";
CM_ SG_ 1345 VFCVectorBECMVFCid42 "ChargingHV";
CM_ SG_ 1345 VFCVectorBECMVFCid43 "BodyPreClimatisation";
CM_ SG_ 1345 VFCVectorBECMVFCid44 "Crash";
CM_ SG_ 1345 VFCVectorBECMVFCid45 "GlobalShortDuration";
CM_ SG_ 1345 VFCVectorBECMVFCid46 "Hazard";
CM_ SG_ 1345 VFCVectorBECMVFCid47 "Reserved";
CM_ SG_ 1345 VFCVectorBECMVFCid48 "DoorOpenWarning";
CM_ SG_ 1345 VFCVectorBECMVFCid49 "ChargingInit";
CM_ SG_ 1345 VFCVectorBECMVFCid5 "Reserved";
CM_ SG_ 1345 VFCVectorBECMVFCid50 "Reserved";
CM_ SG_ 1345 VFCVectorBECMVFCid51 "Reserved";
CM_ SG_ 1345 VFCVectorBECMVFCid52 "ThermalRunaway";
CM_ SG_ 1345 VFCVectorBECMVFCid53 "Reserved";
CM_ SG_ 1345 VFCVectorBECMVFCid54 "Reserved";
CM_ SG_ 1345 VFCVectorBECMVFCid55 "Reserved";
CM_ SG_ 1345 VFCVectorBECMVFCid56 "Reserved";
CM_ SG_ 1345 VFCVectorBECMVFCid57 "Reserved";
CM_ SG_ 1345 VFCVectorBECMVFCid58 "Reserved";
CM_ SG_ 1345 VFCVectorBECMVFCid59 "Reserved";
CM_ SG_ 1345 VFCVectorBECMVFCid6 "UserInputSettings";
CM_ SG_ 1345 VFCVectorBECMVFCid60 "Reserved";
CM_ SG_ 1345 VFCVectorBECMVFCid61 "Reserved";
CM_ SG_ 1345 VFCVectorBECMVFCid7 "Reserved";
CM_ SG_ 1345 VFCVectorBECMVFCid8 "VehicleAPI";
CM_ SG_ 1345 VFCVectorBECMVFCid9 "IPWakeup";
CM_ SG_ 331 DcDcActvd "DCDC actived state";
CM_ SG_ 331 FltElecDcDc "The electrical fault indication of DCDC";
CM_ SG_ 331 FltTDcDc "The temperature fault indication of DCDC";
CM_ SG_ 331 IDcDcActHiSide "Actual measured current on the HV side";
CM_ SG_ 331 IDcDcAvlMaxLoSide "The maximum available current for low voltage loads";
CM_ SG_ 331 UDcDcActHiSide "Measured voltage on the HV side";
CM_ SG_ 521 DcDcCoolgReq "Request for increased cooling flow to DCDC";
CM_ SG_ 521 IDcDcActLoSideChks "Actul current output checksum";
CM_ SG_ 521 IDcDcActLoSideCntr "Actul current output counter";
CM_ SG_ 521 IDcDcActLoSideIDcDcActLoSide "Actul current output";
CM_ SG_ 521 LimnIndcnDcDc "Indication signal from the DcDc that tells that a DTC is set";
CM_ SG_ 521 TDcDc "Temperature of DCDC";
CM_ SG_ 1109 DcDcMinCooltFlow "Minimun coolant flow for DCDC";
CM_ SG_ 1109 DcDcNetIntHeatg "Net internal heating for DCDC";
CM_ SG_ 1109 TDcDcCoolt "Inlet Coolant Temperature of the DCDC";
CM_ SG_ 536 OnBdChrgrCoolgReq "Request for cooling of the onboard charger. ";
CM_ SG_ 536 OnBdChrgrErrIndcnReqChks "Checksum";
CM_ SG_ 536 OnBdChrgrErrIndcnReqCntr "Counter";
CM_ SG_ 536 OnBdChrgrErrIndcnReqOnBdChrgrErrIndcnReq "Error indication requirement";
CM_ SG_ 536 OnBdChrgrHndlSts1 "Status of the Onboard Charger connection to the grid. ";
CM_ SG_ 536 OnBdChrgrRdyTi "The charging ready time";
CM_ SG_ 536 OnBdChrgrT "Temperature of the onboard charger.";
CM_ SG_ 536 PwrEgyMgrAvl "Available power from OBC to HVEEM";
CM_ SG_ 534 DchaIAct "The discharging current of AC";
CM_ SG_ 534 DchaPwrAct "Acutual discharing power ";
CM_ SG_ 534 DchaPwrReq "Discharging power request to EEM";
CM_ SG_ 534 DchaUAct "The discharging voltage of AC";
CM_ SG_ 534 OnBdChrgrClrRdyReq "Clear diagnostic trouble code request";
CM_ SG_ 534 OnBdChrgrIAct "The actual AC input current";
CM_ SG_ 534 OnBdChrgrSt "The charging state of OBC";
CM_ SG_ 298 HndlLockgSts "Status of charge inlet electric lock";
CM_ SG_ 298 OnBdChrgrIDc "The actual DC output current of OBC";
CM_ SG_ 298 OnBdChrgrUAct "The actual AC input voltage";
CM_ SG_ 298 OnBdChrgrUDc "The actual DC output voltage of OBC";
CM_ SG_ 1041 OnBdChrgrCooltT "Inlet Coolant Temperature of the OBC";
CM_ SG_ 1041 OnBdChrgrMinCooltFlow "Minimun coolant flow for OBC";
CM_ SG_ 1041 OnBdChrgrNetIntHeatg "Net internal heating for OBC";
CM_ SG_ 1249 DftlCtrlInfo10 "Debug signals for development purposes.";
CM_ SG_ 1249 DftlCtrlInfo11 "Debug signals for development purposes.";
CM_ SG_ 1249 DftlCtrlInfo12 "Debug signals for development purposes.";
CM_ SG_ 1249 DftlCtrlInfo13 "Debug signals for development purposes.";
CM_ SG_ 1249 DftlCtrlInfo14 "Debug signals for development purposes.";
CM_ SG_ 1249 DftlCtrlInfo15 "Debug signals for development purposes.";
CM_ SG_ 1249 DftlCtrlInfo16 "Debug signals for development purposes.";
CM_ SG_ 1249 DftlCtrlInfo17 "Debug signals for development purposes.";
CM_ SG_ 1250 DftlCtrlInfo20 "Debug signals for development purposes.";
CM_ SG_ 1250 DftlCtrlInfo21 "Debug signals for development purposes.";
CM_ SG_ 1250 DftlCtrlInfo22 "Debug signals for development purposes.";
CM_ SG_ 1250 DftlCtrlInfo23 "Debug signals for development purposes.";
CM_ SG_ 1250 DftlCtrlInfo24 "Debug signals for development purposes.";
CM_ SG_ 1250 DftlCtrlInfo25 "Debug signals for development purposes.";
CM_ SG_ 1250 DftlCtrlInfo26 "Debug signals for development purposes.";
CM_ SG_ 1250 DftlCtrlInfo27 "Debug signals for development purposes.";
CM_ SG_ 1251 DftlCtrlInfo30 "Debug signals for development purposes.";
CM_ SG_ 1251 DftlCtrlInfo31 "Debug signals for development purposes.";
CM_ SG_ 1251 DftlCtrlInfo32 "Debug signals for development purposes.";
CM_ SG_ 1251 DftlCtrlInfo33 "Debug signals for development purposes.";
CM_ SG_ 1251 DftlCtrlInfo34 "Debug signals for development purposes.";
CM_ SG_ 1251 DftlCtrlInfo35 "Debug signals for development purposes.";
CM_ SG_ 1251 DftlCtrlInfo36 "Debug signals for development purposes.";
CM_ SG_ 1251 DftlCtrlInfo37 "Debug signals for development purposes.";
CM_ SG_ 1252 DftlCtrlInfo40 "Debug signals for development purposes.";
CM_ SG_ 1252 DftlCtrlInfo41 "Debug signals for development purposes.";
CM_ SG_ 1252 DftlCtrlInfo42 "Debug signals for development purposes.";
CM_ SG_ 1252 DftlCtrlInfo43 "Debug signals for development purposes.";
CM_ SG_ 1252 DftlCtrlInfo44 "Debug signals for development purposes.";
CM_ SG_ 1252 DftlCtrlInfo45 "Debug signals for development purposes.";
CM_ SG_ 1252 DftlCtrlInfo46 "Debug signals for development purposes.";
CM_ SG_ 1252 DftlCtrlInfo47 "Debug signals for development purposes.";
CM_ SG_ 1253 DftlCtrlInfo50 "Debug signals for development purposes.";
CM_ SG_ 1253 DftlCtrlInfo51 "Debug signals for development purposes.";
CM_ SG_ 1253 DftlCtrlInfo52 "Debug signals for development purposes.";
CM_ SG_ 1253 DftlCtrlInfo53 "Debug signals for development purposes.";
CM_ SG_ 1253 DftlCtrlInfo54 "Debug signals for development purposes.";
CM_ SG_ 1253 DftlCtrlInfo55 "Debug signals for development purposes.";
CM_ SG_ 1253 DftlCtrlInfo56 "Debug signals for development purposes.";
CM_ SG_ 1253 DftlCtrlInfo57 "Debug signals for development purposes.";
CM_ SG_ 1254 DftlCtrlInfo60 "Debug signals for development purposes.";
CM_ SG_ 1254 DftlCtrlInfo61 "Debug signals for development purposes.";
CM_ SG_ 1254 DftlCtrlInfo62 "Debug signals for development purposes.";
CM_ SG_ 1254 DftlCtrlInfo63 "Debug signals for development purposes.";
CM_ SG_ 1254 DftlCtrlInfo64 "Debug signals for development purposes.";
CM_ SG_ 1254 DftlCtrlInfo65 "Debug signals for development purposes.";
CM_ SG_ 1254 DftlCtrlInfo66 "Debug signals for development purposes.";
CM_ SG_ 1254 DftlCtrlInfo67 "Debug signals for development purposes.";
CM_ SG_ 294 DftlFltIndcn "Differential system fault indication";
CM_ SG_ 294 TrsmStAxleReActr "Status of the longitudinal differential clutch";
CM_ SG_ 294 TrsmTqDftlAxleReAct "Actual torque capacity of the longitudinal differential clutch.";
CM_ SG_ 567 MvIsgBltPretensionReq "Belt pretension request";
CM_ SG_ 567 MvIsgESAEndSpd "ESA mode end speed";
CM_ SG_ 567 MvIsgESAEndSpdGrdt "Negative speed gradient in ESA mode";
CM_ SG_ 567 MvIsgESATiMax "ESA mode duration max";
CM_ SG_ 567 MvIsgESATqLimn "Output torque limitation in ESA mode";
CM_ SG_ 567 MvIsgGenTqLimn "Machine torque limitation in GENERATOR mode";
CM_ SG_ 567 MvIsgILimDcha "Maximum excitation current during discharge";
CM_ SG_ 567 MvIsgUReq "Voltage regulation Value in GENERATOR mode";
CM_ SG_ 569 MvIsgIDcLim "Current limit for ISGM";
CM_ SG_ 569 MvIsgSpdStabn "Machine speed stabilization";
CM_ SG_ 569 MvIsgStrtrEndSpd "End of cranking operation machine speed";
CM_ SG_ 569 MvIsgStrtrSpdGrdt "Starter Mode Machine speed gradient";
CM_ SG_ 569 MvIsgStrtrTiMax "Maximum cranking phase duration";
CM_ SG_ 569 MvIsgStrtrTqMax "Maximum Starter Mode Torque";
CM_ SG_ 68 MvIsgModReqChks "Checksum for MvIsgModReq";
CM_ SG_ 68 MvIsgModReqCntr "Counter for MvIsgModReq";
CM_ SG_ 68 MvIsgModReqMvIsgModReq "Machine Mode choice";
CM_ SG_ 68 MvIsgTqNegGrdt "Machine negative torque gradient in torque regulation mode";
CM_ SG_ 68 MvIsgTqPosGrdt "Machine positive torque gradient in torque regulation mode";
CM_ SG_ 68 MvIsgTqReqChks "Counter for MvIsgTqReq";
CM_ SG_ 68 MvIsgTqReqCntr "Checksum for MvIsgTqReq";
CM_ SG_ 68 MvIsgTqReqMvIsgTqReq "Machine torque request in Torque control mode";
CM_ SG_ 333 MvDcDcModReqChks "CheckSum";
CM_ SG_ 333 MvDcDcModReqCntr "Counter";
CM_ SG_ 333 MvDcDcModReqMvDcDcModReq "MV DcDc mode request";
CM_ SG_ 333 MvIsgSpdNegGrdt "Machine negative speed gradient in speed regulation mode";
CM_ SG_ 333 MvIsgSpdPosGrdt "Machine positive speed gradient in speed regulation mode";
CM_ SG_ 333 MvIsgSpdRgln "Speed regulation setpoint  in Speed ctrl mode";
CM_ SG_ 333 MvIsgSpdTqPosLim "Machine positive torque limitation in speed regulation mode";
CM_ SG_ 67 MvBattRlyReq "MV Battery relay position request";
CM_ SG_ 67 MvChrgnUReq "Voltage set-point to the DcDc for the high voltage side";
CM_ SG_ 67 MvDcDcModReqSec "Mode request to secondary medium voltage DcDc";
CM_ SG_ 67 MvIDcDcMax "Maximal current that can be taken output network";
CM_ SG_ 67 MvIDcDcMaxSec "Maximal current that can be taken at secondary output network";
CM_ SG_ 67 MvIsgTqNegAllwd "Machine Negative torque limitation in Torque control";
CM_ SG_ 67 MvIsgTqPosAllwd "Machine Positive torque limitation in Torque control";
CM_ SG_ 67 MvUDcDcRgInReq "Voltage regulation setpoint either for LV or HV network voltage regulation operating mode direct or reverse";
CM_ SG_ 131 ChrgnUReqSec "Requested secondary charging voltage from Voltage Control";
CM_ SG_ 131 MvIsgSpdTqNegLim "Machine Negative torque limitation in speed regulation mode";
CM_ SG_ 131 SecBattSftySigChks "Check Sum";
CM_ SG_ 131 SecBattSftySigCntr "Counter";
CM_ SG_ 131 SecBattSftySigSysSaftyBattI "Secondary System Safety Battery Current";
CM_ SG_ 131 SecBattSftySigSysSaftyBattU "Secondary System Safety Battery Voltage";
CM_ SG_ 341 EngTiOff "Time since engine is stoped (i.e. 0 rpm)";
CM_ SG_ 341 PtToTrsmRatMgrIfPtGearReq "Requested gear";
CM_ SG_ 341 PtToTrsmRatMgrIfPtGearReqInter "Requested intermidiate gear";
CM_ SG_ 341 PtToTrsmRatMgrIfPtLockFwAtGearFirst "Engine brake request on first gear not free wheel";
CM_ SG_ 341 PtToTrsmRatMgrIfPtLockUpReq "Requested lock-up";
CM_ SG_ 341 PtToTrsmRatMgrIfPtLockUpSlipReq "Slip request for lock-up";
CM_ SG_ 341 PtToTrsmRatMgrIfPtShiftTypReq "Requested shift quality";
CM_ SG_ 341 PtToTrsmRatMgrIfPtTrsmModReq "Requested transmission mode (engaged / neutral)";
CM_ SG_ 341 TrsmParkLockdChks "Checksum for TrsmParkLockd";
CM_ SG_ 341 TrsmParkLockdCntr "Counter for TrsmParkLockd";
CM_ SG_ 341 TrsmParkLockdTrsmParkLockd "Transmission park lock status";
CM_ SG_ 577 BookChrgTarValLnr "Convert Book charge target SOC to BECM";
CM_ SG_ 577 EngCooltInhbFlow "Inhibitation of non-crucial coolant flow requests. Sent out to inform that the eninge is in heat up phase and that all additional coolant flow will postphone the time when the engine has reached normal operating temperature.";
CM_ SG_ 577 EngKdSts "Kick down marker. Signal is used for limp home functionality in the gearbox.";
CM_ SG_ 577 LoadValCalcd "The ECU shall make the signal Calculated Load Value according to SAE J1979 available on CAN.";
CM_ SG_ 577 PtTiToCluEngmt "Time to clutch engagement. Reciever needs to compensate for CAN delays.   ";
CM_ SG_ 577 TrsmActrKeyChks "Checksum for TrsmActrKey";
CM_ SG_ 577 TrsmActrKeyCntr "Counter for TrsmActrKey";
CM_ SG_ 577 TrsmActrKeyEna "Transmission Actuator Enable Key";
CM_ SG_ 74 AccrPedlLnr "CVC filtered accelerator pedal";
CM_ SG_ 74 AccrPedlRatAccrPedlRat "Accelerator Pedal Position with adapted 0 point. Value as percentage of fully pressed pedal";
CM_ SG_ 74 AccrPedlRatChks "Accelerator Pedal Position with adapted 0 point. Value as percentage of fully pressed pedal. Checksum";
CM_ SG_ 74 AccrPedlRatCntr "Accelerator Pedal Position with adapted 0 point. Value as percentage of fully pressed pedal. Counter";
CM_ SG_ 74 IsgSpdReq "ISG speed request for engine speed control by ISG.";
CM_ SG_ 80 IsgModReq "Mode request for ISG motor drive system.";
CM_ SG_ 80 IsgTqReq "Requested ISG motor torque on the crankshaft. The torque is positive in the forward rotation direction. ";
CM_ SG_ 80 PrpsnTqFrntReq "Propulsion wheel torque request at front wheel axle. This request is arbitrated from driver request and autonomous driving functions (CC, ACC, etc) requests. The torque includes effects from auxiliary loads, transmissions, etc.";
CM_ SG_ 80 PtCluTqReq "Requested crank shaft torque.";
CM_ SG_ 102 EngNSafeEngN "Engine Speed [rpm] and Engine Speed derivative [rpm/s]";
CM_ SG_ 102 EngNSafeEngNChks "Engine Speed [rpm] and Engine Speed derivative [rpm/s]";
CM_ SG_ 102 EngNSafeEngNCntr "Engine Speed [rpm] and Engine Speed derivative [rpm/s]";
CM_ SG_ 102 EngNSafeEngNGrdt "Engine Speed [rpm] and Engine Speed derivative [rpm/s]";
CM_ SG_ 102 EngTqLimDly "Estimated time to when the expected intervention torque from transmission can be reached using air control. This signal is a part of the information exchange between ECM and TCM for coordination of transmission fast and slow torque request with the transmission actuator control during gearchange.";
CM_ SG_ 102 PtGearAct "Actual gear.";
CM_ SG_ 102 WhlMotSysModReq "Mode request for motor drive system connected to wheel shaft.";
CM_ SG_ 277 PtCluTqDyn "Acual crank shaft torque. Crankshaft torque dynamic";
CM_ SG_ 277 PtCluTqPtCluTq "Acual crank shaft torque. Crankshaft torque";
CM_ SG_ 277 PtCluTqQly "Acual crank shaft torque. Crankshaft torque quality factor";
CM_ SG_ 277 PtCluTqReqWoTrsmIntv "Requested crank shaft torque without gearbox limitations. Also named arbitrated crankshaft torque.";
CM_ SG_ 277 PtDirAllwdToTrsmActrAuxChks "Checksum for PtDirAllwdToTrsmActrAux";
CM_ SG_ 277 PtDirAllwdToTrsmActrAuxCntr "Counter for PtDirAllwdToTrsmActrAux";
CM_ SG_ 277 PtDirAllwdToTrsmActrAuxFwd "Powertrain direction allowance to transmission actuator Forward";
CM_ SG_ 277 PtDirAllwdToTrsmActrAuxNeut "Powertrain direction allowance to transmission actuator Neutral";
CM_ SG_ 277 PtDirAllwdToTrsmActrAuxParkRls "Powertrain direction allowance to transmission actuator Park Release";
CM_ SG_ 277 PtDirAllwdToTrsmActrAuxRvs "Powertrain direction allowance to transmission actuator Reverse";
CM_ SG_ 277 PtReqToTrsmActr "Request to transmission actuator (PRND)";
CM_ SG_ 305 DcDcActvdReq "Signal requesting the DCDC to be activated after conditions are fullfilled. ";
CM_ SG_ 305 DispHvBattLvlOfChrg "HV battery State-Of-Charge (SOC) value for display to driver. Note: this value may differ from the actual battery SOC. ";
CM_ SG_ 305 IsgActvDampgGain "Active damping (anti-shuffle) gain factor.";
CM_ SG_ 305 PtAllwdToTrsmActrSafeChks "Checksum for PtAllwdToTrsmActr";
CM_ SG_ 305 PtAllwdToTrsmActrSafeCntr "Counter for PtAllwdToTrsmActr";
CM_ SG_ 305 PtAllwdToTrsmActrSafePtAllwdToTrsmActr "Powertrain allowed to transmission actuator.";
CM_ SG_ 305 WhlMotSysPwrLimMax "Maximum electric motor powerlimit on DC side. Positive power means power flowing into inverter. ";
CM_ SG_ 405 HvPwrEgyPrio "Information about which session is prioritized (charging, cooling, climatization etc).";
CM_ SG_ 405 IsgPwrLimMax "Maximum ISG motor drive system powerlimit on DC side. Positive power means power flowing into inverter.";
CM_ SG_ 405 IsgPwrLimMin "Minimum ISG motor drive system powerlimit on DC side. Positive power means power flowing into inverter.";
CM_ SG_ 405 OnBdChrgrPwrEnaAllwd "Signaling that the OBC is allowed to deliver power to the car and battery. Flag to sync battery contactor state with OBC power. Battery Contactor shall be closed when OBC supplies HV power; 0 = Do not supply HV power; 1 = Do supply HV power";
CM_ SG_ 405 WhlMotSysTqAllwdChks "Checksum for WhlMotSysTqAllwd";
CM_ SG_ 405 WhlMotSysTqAllwdCntr "Counter for WhlMotSysTqAllwd";
CM_ SG_ 405 WhlMotSysTqAllwdWhlMotSysTqAllwd "Indication if ERAD is allowed to apply propulsive or regenerative torque on wheels. Bit 0: Propulsive torque allowed Bit 1: Regenerative torque allowed";
CM_ SG_ 816 HvCooltHeatrStsSig "Informs of HVCH status.";
CM_ SG_ 816 HvCooltWtrHeatrWtrTInOutl "Coolant temperature in heater outlet.";
CM_ SG_ 512 PtTqAtWhlFrntActPtTqAtWhlFrntAct "Actual torque delivered by the powertrain to the front axle";
CM_ SG_ 512 PtTqAtWhlFrntActPtTqAtWhlFrntLeAct "Actual torque delivered by the powertrain to the front left wheel.";
CM_ SG_ 512 PtTqAtWhlFrntActPtTqAtWhlFrntQly "quality factor";
CM_ SG_ 512 PtTqAtWhlFrntActPtTqAtWhlFrntRiAct "Actual torque delivered by the powertrain to the front right wheel.";
CM_ SG_ 512 PtTqAtWhlFrntActRecChks "checksum";
CM_ SG_ 512 PtTqAtWhlFrntActRecCntr "counter";
CM_ SG_ 545 EngNLim "Indicates the actual maximum allowed engine speed (rpm).";
CM_ SG_ 545 EngTEngT "Engine coolant temperature. Resolution 1 degC
";
CM_ SG_ 545 EngTQf "Engine coolant temperature quality factor.Engine coolant temperature";
CM_ SG_ 545 GearLvrEna "Allowance for moving gear lever, based on determining driver in the vehicle via brake pedal and vehicle state via vehicle speed.
";
CM_ SG_ 545 HvBattCoolgCmd "Information for HvBatt if batterycooling is allowed";
CM_ SG_ 545 HvOnMaiReq "Command to high voltage battery controller to open, close, or retain the high voltage contactor position";
CM_ SG_ 545 IsgActvDampgModReq "Mode signal for ISG damping. 0 = No damping; 1 = Low damping; 2 = Medium damping; 3 = High damping";
CM_ SG_ 545 PrpsnFbLimnIndcn "Feedback signal that the present limitation has lead to a recofiguraton that has affected the driver.";
CM_ SG_ 545 PtRatMgrMod "Current ratio manager mode";
CM_ SG_ 545 ThrPos " ECM  throttle position (AbsThrottlePosition) on CAN";
CM_ SG_ 545 WrmUpCyc "Transition from 0 to 1 indicates a start of a warm up cycle";
CM_ SG_ 592 AltIAvlAtIdle "Available alternator current at idle speed.";
CM_ SG_ 592 EngEffSts "Engine efficiency status";
CM_ SG_ 592 EngIdleCtrlRefVal "Reference speed for idle speed controler.";
CM_ SG_ 592 HvBattChrgnCmd "Information for HvBatt if charging is allowed.";
CM_ SG_ 592 ObdAccrPedRat "PID 49 acording to SAE 1979DA";
CM_ SG_ 592 PtRatMgrAdpvMod "Current ratio manager adaptive mode";
CM_ SG_ 647 BookChargeSetResponse "Indicate bookcharging set response.";
CM_ SG_ 647 ChrgnSts "Information of vehicle charging status, which is requested from GB/T 32960.";
CM_ SG_ 647 CmptmtCoolgSts "Status of compartment cooling";
CM_ SG_ 647 CooltFlowForDtElec "Predicted coolant low for Electric Drivetrain (ED) coolant circuit.";
CM_ SG_ 647 CooltTSigForDtElec "Coolant temperature measured by sensors installed in emotor cooling citcuit.";
CM_ SG_ 647 DeactvtTestCom "Scantool communication on/ff0=on=scantool communication is on1=off=scantool communication is off.";
CM_ SG_ 647 EngAmbTCalcd "Ambient Temparature calculated by ECM using engine temperature sensors";
CM_ SG_ 647 HvConvPwrAllwd "Power limitation for DC/DC converter (i.e. sets a limit for power consumption for 12V system). ";
CM_ SG_ 647 MonrCycCmpl "OBD Warm Up Cycle Complete. 0= Not Complete; 1= Complete.";
CM_ SG_ 647 PrpsnSysActv "Indicate whether propulsion system activation has complete or not.";
CM_ SG_ 1160 HvBattThermInfoCorrInFuturePwrAtTime "Corrected battery power request at time in the future. ";
CM_ SG_ 1160 HvBattThermInfoCorrInFutureSequenceNo "Sequence number";
CM_ SG_ 1160 HvBattThermInfoCorrInFutureTempAtTime "Correct battery temperature at time in the future.";
CM_ SG_ 1160 HvBattThermInfoCorrInFutureThermModAtTime "Corrected battery thermal mode at time in the future.";
CM_ SG_ 1160 HvBattThermInfoCorrInFutureTime "Corrected time in the future";
CM_ SG_ 1160 HvBattThermInfoCorrInFutureVersionNo "Version number";
CM_ SG_ 586 DchaPwrAllwd "Power available for Discharging in real time. From wall socket if plugged in, from propulsion or high voltage battery.";
CM_ SG_ 586 HvBattChrgnPwrAllwd1 "Power available for charging in real time. From wall socket if plugged in, from propulsion or high voltage battery.";
CM_ SG_ 586 HvBattFlwEstmd "Battery estimated coolant flow.";
CM_ SG_ 586 HvBattThermReqFb "Battery thermal request feedback.";
CM_ SG_ 75 DrvrDesDirChks "Desired Driver Direction is an interpretation of driver input. It specifies in which longitudinal direction the driver requests that any accelerating propulsive torque shall be delivered. There are three possible directions: 1. Forward 2. Reverse 3. Neutral. Checksum";
CM_ SG_ 75 DrvrDesDirCntr "Desired Driver Direction is an interpretation of driver input. It specifies in which longitudinal direction the driver requests that any accelerating propulsive torque shall be delivered. There are three possible directions: 1. Forward 2. Reverse 3. Neutral. Counter";
CM_ SG_ 75 DrvrDesDirDrvrDesDir "Desired Driver Direction is an interpretation of driver input. It specifies in which longitudinal direction the driver requests that any accelerating propulsive torque shall be delivered. There are three possible directions: 1. Forward 2. Reverse 3. Neutral";
CM_ SG_ 75 EngSt1WdStsChks "checksum";
CM_ SG_ 75 EngSt1WdStsCntr "counter";
CM_ SG_ 75 EngSt1WdStsEngSt1WdSts "Signaling the state of the powerpack";
CM_ SG_ 75 GearLvrIndcn "Gear lever indication (drivetrain position) to the driver. If drivetrain position is not possible to decide signal is set to undefined. Valid for automatic vehicles.
";
CM_ SG_ 75 HvchSts "HVCH status";
CM_ SG_ 75 WhlMotSysTqReq "Requested electric motor torque referred to the wheel axle. The torque is positive in the forward rotation direction. ";

// Attribute definitions
BA_DEF_  "Baudrate" INT 1000 1000000; // [bps]
BA_DEF_ BO_ "GenMsgSendType" ENUM "cyclic", "spontaneous", "not-used", "not-used", "not-used", "cyclicAndSpontaneous", "not-used", "cyclicIfActive", "NoMsgSendType"; // [us]
BA_DEF_ BO_ "GenMsgCycleTime" INT 0 65536; // [ms]
BA_DEF_ BO_ "GenMsgStartDelayTime" INT 0 65536; // [ms]
BA_DEF_ BO_ "GenMsgDelayTime" INT 0 65536; // [ms]
BA_DEF_ SG_ "GenSigSendType" ENUM "Cyclic","OnWrite","OnWriteWithRepetition","OnChange","OnChangeWithRepetition","IfActive","IfActiveWithRepetition","NoSigSendType";
BA_DEF_ SG_ "GenSigStartValue" HEX 0 80000000;
BA_DEF_ BU_ "NmAsrNodeIdentifier" INT 0 255;
BA_DEF_  "DBName" STRING;
BA_DEF_  "BusType" STRING;
BA_DEF_  "ProtocolType" STRING;
BA_DEF_ BO_ "GenMsgILSupport" ENUM "No","Yes";
BA_DEF_ BO_ "NmAsrMessage" ENUM "No","Yes";
BA_DEF_  "NmAsrBaseAddress" HEX 0 536870911;
BA_DEF_  "NmAsrMessageCount" INT 0 255;
BA_DEF_ BU_ "NodeLayerModules" STRING;
BA_DEF_ BU_ "NmAsrNode" ENUM "No","Yes";
BA_DEF_ BU_ "ILused" ENUM "No","Yes";
BA_DEF_ SG_ "GenSigFuncType" ENUM "NoFunction","n/a","n/a","n/a","n/a","n/a","n/a","n/a","n/a","n/a","n/a","n/a","n/a","n/a","n/a","CHK","CNTR","n/a","n/a","n/a","CNTR_AR_01","CRC_AR_01_BOTH","CRC_AR_01_ALT","CRC_AR_01_LOW","CRC_AR_01_NIBBLE","CNTR_AR_04","CRC_AR_04A","CNTR_AR_05","CRC_AR_05";
BA_DEF_ SG_ "GenSigDataID" STRING;

BA_DEF_DEF_ "GenSigStartValue" 0;
BA_DEF_DEF_ "GenSigSendType" "NoSigSendType";
BA_DEF_DEF_ "DBName" "";
BA_DEF_DEF_ "BusType" "";
BA_DEF_DEF_ "ProtocolType" "";
BA_DEF_DEF_ "GenMsgCycleTime" 0;
BA_DEF_DEF_ "GenMsgDelayTime" 0;
BA_DEF_DEF_ "GenMsgStartDelayTime" 0;
BA_DEF_DEF_ "GenMsgSendType" "NoMsgSendType";
BA_DEF_DEF_ "GenMsgILSupport" "Yes";
BA_DEF_DEF_ "NmAsrMessage" "No";
BA_DEF_DEF_ "NmAsrBaseAddress" 1280;
BA_DEF_DEF_ "NmAsrMessageCount" 64;
BA_DEF_DEF_ "NodeLayerModules" "CANoeILNLSPA.dll";
BA_DEF_DEF_ "NmAsrNode" "No";
BA_DEF_DEF_ "NmAsrNodeIdentifier" 0;
BA_DEF_DEF_ "ILused" "Yes";
BA_DEF_DEF_ "GenSigFuncType" "NoFunction";
BA_DEF_DEF_ "GenSigDataID" "";

// Network
BA_ "DBName" "PropulsionCAN";
BA_ "BusType" "CAN";
BA_ "ProtocolType" "CAN";
BA_ "Baudrate" 500000;
// ECU: BECM
BA_ "NmAsrNodeIdentifier" BU_ BECM 25;
BA_ "NmAsrNode" BU_ BECM 1;
BA_ "NodeLayerModules" BU_ BECM "CANoeILNLSPA.dll,AsrNM33.dll";
// ECU: DEM
BA_ "NmAsrNodeIdentifier" BU_ DEM 30;
BA_ "NmAsrNode" BU_ DEM 1;
BA_ "NodeLayerModules" BU_ DEM "CANoeILNLSPA.dll,AsrNM33.dll";
// ECU: ECM
BA_ "NmAsrNodeIdentifier" BU_ ECM 32;
BA_ "NmAsrNode" BU_ ECM 1;
BA_ "NodeLayerModules" BU_ ECM "CANoeILNLSPA.dll,AsrNM33.dll";
// ECU: EGSM
BA_ "NmAsrNodeIdentifier" BU_ EGSM 22;
BA_ "NmAsrNode" BU_ EGSM 1;
BA_ "NodeLayerModules" BU_ EGSM "CANoeILNLSPA.dll,AsrNM33.dll";
// ECU: ESM
BA_ "NmAsrNodeIdentifier" BU_ ESM 40;
BA_ "NmAsrNode" BU_ ESM 1;
BA_ "NodeLayerModules" BU_ ESM "CANoeILNLSPA.dll,AsrNM33.dll";
// ECU: ETC
BA_ "ILused" BU_ ETC 0;
// ECU: IEM
BA_ "NmAsrNodeIdentifier" BU_ IEM 28;
BA_ "NmAsrNode" BU_ IEM 1;
BA_ "NodeLayerModules" BU_ IEM "CANoeILNLSPA.dll,AsrNM33.dll";
// ECU: IGM
BA_ "NmAsrNodeIdentifier" BU_ IGM 27;
BA_ "NmAsrNode" BU_ IGM 1;
BA_ "NodeLayerModules" BU_ IGM "CANoeILNLSPA.dll,AsrNM33.dll";
// ECU: ISGM
BA_ "NmAsrNodeIdentifier" BU_ ISGM 36;
BA_ "NmAsrNode" BU_ ISGM 1;
BA_ "NodeLayerModules" BU_ ISGM "CANoeILNLSPA.dll,AsrNM33.dll";
// ECU: MVBM
BA_ "NmAsrNodeIdentifier" BU_ MVBM 34;
BA_ "NmAsrNode" BU_ MVBM 1;
BA_ "NodeLayerModules" BU_ MVBM "CANoeILNLSPA.dll,AsrNM33.dll";
// ECU: MVCM
BA_ "NmAsrNodeIdentifier" BU_ MVCM 35;
BA_ "NmAsrNode" BU_ MVCM 1;
BA_ "NodeLayerModules" BU_ MVCM "CANoeILNLSPA.dll,AsrNM33.dll";
// ECU: MVEM
BA_ "ILused" BU_ MVEM 0;
// ECU: OBC
BA_ "NmAsrNodeIdentifier" BU_ OBC 24;
BA_ "NmAsrNode" BU_ OBC 1;
BA_ "NodeLayerModules" BU_ OBC "CANoeILNLSPA.dll,AsrNM33.dll";
// ECU: SRS
BA_ "NmAsrNodeIdentifier" BU_ SRS 26;
BA_ "NmAsrNode" BU_ SRS 1;
BA_ "NodeLayerModules" BU_ SRS "CANoeILNLSPA.dll,AsrNM33.dll";
// ECU: TACM
BA_ "NmAsrNodeIdentifier" BU_ TACM 43;
BA_ "NmAsrNode" BU_ TACM 1;
BA_ "NodeLayerModules" BU_ TACM "CANoeILNLSPA.dll,AsrNM33.dll";
// ECU: TCM
BA_ "NmAsrNodeIdentifier" BU_ TCM 23;
BA_ "NmAsrNode" BU_ TCM 1;
BA_ "NodeLayerModules" BU_ TCM "CANoeILNLSPA.dll,AsrNM33.dll";
// ECU: VDDM
BA_ "NmAsrNodeIdentifier" BU_ VDDM 38;
BA_ "NmAsrNode" BU_ VDDM 1;
BA_ "NodeLayerModules" BU_ VDDM "CANoeILNLSPA.dll,AsrNM33.dll";
// ECU: VGM
BA_ "NmAsrNodeIdentifier" BU_ VGM 44;
BA_ "NmAsrNode" BU_ VGM 1;
BA_ "NodeLayerModules" BU_ VGM "AsrNM33.dll";
// Frame: BecmPropFr01
BA_ "GenMsgSendType" BO_ 321 0;
BA_ "GenMsgCycleTime" BO_ 321 20.000;
BA_ "GenSigSendType" SG_ 321 HvBattUDc 0;
BA_ "GenSigSendType" SG_ 321 HvBattUDynMaxLim 0;
BA_ "GenSigSendType" SG_ 321 HvSysActvnInhb 0;
BA_ "GenSigSendType" SG_ 321 HvSysPwrOff 0;
BA_ "GenSigSendType" SG_ 321 HvSysRlyStsChks 0;
BA_ "GenSigFuncType" SG_ 321 HvSysRlyStsChks 15;
BA_ "GenSigDataID" SG_ 321 HvSysRlyStsChks "0x15";
BA_ "GenSigSendType" SG_ 321 HvSysRlyStsCntr 0;
BA_ "GenSigFuncType" SG_ 321 HvSysRlyStsCntr 16;
BA_ "GenSigStartValue" SG_ 321 HvSysRlyStsHvSysRlySts 2;
BA_ "GenSigSendType" SG_ 321 HvSysRlyStsHvSysRlySts 0;
BA_ "GenSigSendType" SG_ 321 HvSysSts 0;
// Frame: BecmPropFr02
BA_ "GenMsgSendType" BO_ 373 0;
BA_ "GenMsgCycleTime" BO_ 373 100.000;
BA_ "GenSigSendType" SG_ 373 ACChrgnConnectSts 0;
BA_ "GenSigSendType" SG_ 373 ACChrgnCPSts 0;
BA_ "GenSigSendType" SG_ 373 ACChrgnCurrentLimn 0;
BA_ "GenSigSendType" SG_ 373 ACChrgnIfErr 0;
BA_ "GenSigSendType" SG_ 373 ACChrgnS2Sts 0;
BA_ "GenSigSendType" SG_ 373 HvBattLimnIndcnChks 0;
BA_ "GenSigFuncType" SG_ 373 HvBattLimnIndcnChks 15;
BA_ "GenSigDataID" SG_ 373 HvBattLimnIndcnChks "0x20";
BA_ "GenSigSendType" SG_ 373 HvBattLimnIndcnCntr 0;
BA_ "GenSigFuncType" SG_ 373 HvBattLimnIndcnCntr 16;
BA_ "GenSigSendType" SG_ 373 HvBattLimnIndcnHvBattLimnIndcn 0;
BA_ "GenSigSendType" SG_ 373 HvBattUDynMinLim 0;
BA_ "GenSigSendType" SG_ 373 MaintainBattTFb 1;
// Frame: BecmPropFr03
BA_ "GenMsgSendType" BO_ 581 0;
BA_ "GenMsgCycleTime" BO_ 581 70.000;
BA_ "GenSigSendType" SG_ 581 HvBattChrgnCmpl 0;
BA_ "GenSigSendType" SG_ 581 HvBattCoolgReq 0;
BA_ "GenSigSendType" SG_ 581 HvBattILim 0;
BA_ "GenSigSendType" SG_ 581 HvBattSoc 0;
BA_ "GenSigSendType" SG_ 581 HvBattULim 0;
BA_ "GenSigSendType" SG_ 581 HvSysLimnIndcn 0;
// Frame: BecmPropFr04
BA_ "GenMsgSendType" BO_ 659 0;
BA_ "GenMsgCycleTime" BO_ 659 400.000;
BA_ "GenSigSendType" SG_ 659 HvBattEgyCdn 0;
BA_ "GenSigSendType" SG_ 659 HvBattErrIndcnReq 0;
BA_ "GenSigSendType" SG_ 659 HvBattHeatgReq 0;
BA_ "GenSigSendType" SG_ 659 HvBattSocLimHi 0;
BA_ "GenSigSendType" SG_ 659 HvBattSocLimLo 0;
BA_ "GenSigSendType" SG_ 659 HvBattSocLimMax 0;
BA_ "GenSigSendType" SG_ 659 HvBattSocLimMin 0;
// Frame: BecmPropFr05
BA_ "GenMsgSendType" BO_ 661 0;
BA_ "GenMsgCycleTime" BO_ 661 600.000;
BA_ "GenSigStartValue" SG_ 661 HvBattCoolgSts 1;
BA_ "GenSigSendType" SG_ 661 HvBattCoolgSts 0;
BA_ "GenSigStartValue" SG_ 661 HVIL1Sts 1;
BA_ "GenSigSendType" SG_ 661 HVIL1Sts 0;
BA_ "GenSigStartValue" SG_ 661 HVIL2Sts 1;
BA_ "GenSigSendType" SG_ 661 HVIL2Sts 0;
BA_ "GenSigStartValue" SG_ 661 HVIL3Sts 1;
BA_ "GenSigSendType" SG_ 661 HVIL3Sts 0;
BA_ "GenSigSendType" SG_ 661 HvIsoSts 0;
BA_ "GenSigSendType" SG_ 661 HvSysCrashFb 0;
// Frame: BecmPropFr07
BA_ "GenMsgSendType" BO_ 662 0;
BA_ "GenMsgCycleTime" BO_ 662 600.000;
BA_ "GenSigSendType" SG_ 662 FastChrgnLockCtrl 0;
BA_ "GenSigStartValue" SG_ 662 HvBattCooltTReq 50;
BA_ "GenSigSendType" SG_ 662 HvBattCooltTReq 0;
// Frame: BecmPropFr08
BA_ "GenMsgSendType" BO_ 834 0;
BA_ "GenMsgCycleTime" BO_ 834 1000.000;
BA_ "GenSigStartValue" SG_ 834 HvBattCodLen 1;
BA_ "GenSigSendType" SG_ 834 HvBattCodLen 0;
BA_ "GenSigSendType" SG_ 834 HvBattMismatchFlt 0;
BA_ "GenSigStartValue" SG_ 834 HvBattNr 1;
BA_ "GenSigSendType" SG_ 834 HvBattNr 0;
BA_ "GenSigSendType" SG_ 834 HvCellTDifFlt 0;
BA_ "GenSigSendType" SG_ 834 HvCellTOverFlt 0;
BA_ "GenSigSendType" SG_ 834 HvCellUDifFlt 0;
BA_ "GenSigSendType" SG_ 834 HvCellUOverFlt 0;
BA_ "GenSigSendType" SG_ 834 HvCellUUnderFlt 0;
BA_ "GenSigSendType" SG_ 834 HvilFlt 0;
BA_ "GenSigSendType" SG_ 834 HvIsoFlt 0;
BA_ "GenSigSendType" SG_ 834 HvPackOverChrgFlt 0;
BA_ "GenSigSendType" SG_ 834 HvPackUOverFlt 0;
BA_ "GenSigSendType" SG_ 834 HvPackUUnderFlt 0;
BA_ "GenSigSendType" SG_ 834 HvSocHiFlt 0;
BA_ "GenSigSendType" SG_ 834 HvSocHopFlt 0;
BA_ "GenSigSendType" SG_ 834 HvSocLoFlt 0;
// Frame: BecmPropFr09
BA_ "GenMsgSendType" BO_ 789 0;
BA_ "GenMsgCycleTime" BO_ 789 800.000;
BA_ "GenSigStartValue" SG_ 789 HvBattChrgnSts 1;
BA_ "GenSigSendType" SG_ 789 HvBattChrgnSts 0;
BA_ "GenSigSendType" SG_ 789 HvBattTAvg 0;
BA_ "GenSigSendType" SG_ 789 HvBattTMax 0;
BA_ "GenSigSendType" SG_ 789 HvBattTMin 0;
// Frame: BecmPropFr11
BA_ "GenMsgSendType" BO_ 817 0;
BA_ "GenMsgCycleTime" BO_ 817 1000.000;
BA_ "GenSigSendType" SG_ 817 HvBattCoolgEgyReq1 0;
BA_ "GenSigSendType" SG_ 817 HvBattCooltFlowReq 0;
BA_ "GenSigStartValue" SG_ 817 HvBattCooltT 50;
BA_ "GenSigSendType" SG_ 817 HvBattCooltT 0;
// Frame: BecmPropFr12
BA_ "GenMsgSendType" BO_ 769 0;
BA_ "GenMsgCycleTime" BO_ 769 600.000;
BA_ "GenSigSendType" SG_ 769 HvBattPwrCdn 0;
// Frame: BecmPropFr13
BA_ "GenMsgSendType" BO_ 664 0;
BA_ "GenMsgCycleTime" BO_ 664 600.000;
BA_ "GenSigSendType" SG_ 664 HvBattChrgnPwrCns1 0;
BA_ "GenSigSendType" SG_ 664 HvBattChrgnPwrCritDes1 0;
BA_ "GenSigSendType" SG_ 664 HvBattChrgnPwrNormDes1 0;
BA_ "GenSigSendType" SG_ 664 HvBattEgyAvlChrg1 0;
// Frame: BecmPropFr14
BA_ "GenMsgSendType" BO_ 646 0;
BA_ "GenMsgCycleTime" BO_ 646 140.000;
BA_ "GenSigSendType" SG_ 646 HvBattEgyAvlDcha1 0;
BA_ "GenSigSendType" SG_ 646 HvBattHeatGenn 0;
BA_ "GenSigSendType" SG_ 646 HvBattPreHeatFaild 0;
BA_ "GenSigStartValue" SG_ 646 PackNr 1;
BA_ "GenSigSendType" SG_ 646 PackNr 0;
// Frame: BecmPropFr15
BA_ "GenMsgSendType" BO_ 323 0;
BA_ "GenMsgCycleTime" BO_ 323 20.000;
BA_ "GenSigSendType" SG_ 323 DCChrgnHndlSts 0;
BA_ "GenSigStartValue" SG_ 323 HvBattIDc1 16380;
BA_ "GenSigSendType" SG_ 323 HvBattIDc1 0;
BA_ "GenSigSendType" SG_ 323 HvBattPwrLimChrg1 0;
BA_ "GenSigSendType" SG_ 323 HvBattPwrLimDcha1 0;
BA_ "GenSigSendType" SG_ 323 HvBattPwrLimDchaSoft 0;
// Frame: BecmPropFr16
BA_ "GenMsgSendType" BO_ 833 0;
BA_ "GenMsgCycleTime" BO_ 833 1000.000;
BA_ "GenSigSendType" SG_ 833 HvBattClimaPwr 0;
BA_ "GenSigSendType" SG_ 833 HvBattClrRdyReq 0;
BA_ "GenSigSendType" SG_ 833 HvBattHeatgEgyReq 0;
// Frame: BecmPropFr17
BA_ "GenMsgSendType" BO_ 837 0;
BA_ "GenMsgCycleTime" BO_ 837 1000.000;
BA_ "GenSigSendType" SG_ 837 HvBattCellTNr 0;
BA_ "GenSigStartValue" SG_ 837 HvBattCooltMaxTReq 50;
BA_ "GenSigSendType" SG_ 837 HvBattCooltMaxTReq 0;
BA_ "GenSigStartValue" SG_ 837 HvBattCooltMinTReq 50;
BA_ "GenSigSendType" SG_ 837 HvBattCooltMinTReq 0;
BA_ "GenSigSendType" SG_ 837 HvBattPreHeatgReq 0;
BA_ "GenSigSendType" SG_ 837 HvBattThermMod 0;
BA_ "GenSigStartValue" SG_ 837 HvBattTMaxSerlNr 1;
BA_ "GenSigSendType" SG_ 837 HvBattTMaxSerlNr 0;
BA_ "GenSigStartValue" SG_ 837 HvBattTMinSerlNr 1;
BA_ "GenSigSendType" SG_ 837 HvBattTMinSerlNr 0;
// Frame: BecmPropFr18
BA_ "GenMsgSendType" BO_ 838 0;
BA_ "GenMsgCycleTime" BO_ 838 1000.000;
BA_ "GenSigSendType" SG_ 838 HvBattCooltLvl 0;
BA_ "GenSigStartValue" SG_ 838 HvBattCooltOutletT 50;
BA_ "GenSigSendType" SG_ 838 HvBattCooltOutletT 0;
BA_ "GenSigSendType" SG_ 838 HvBattHeatgPwr 0;
BA_ "GenSigStartValue" SG_ 838 HvBattVoltMaxSerlNr 1;
BA_ "GenSigSendType" SG_ 838 HvBattVoltMaxSerlNr 0;
BA_ "GenSigStartValue" SG_ 838 HvBattVoltMinSerlNr 1;
BA_ "GenSigSendType" SG_ 838 HvBattVoltMinSerlNr 0;
// Frame: BecmPropFr19
BA_ "GenMsgSendType" BO_ 839 0;
BA_ "GenMsgCycleTime" BO_ 839 1000.000;
BA_ "GenSigSendType" SG_ 839 HvBattCodPackCodeX1 0;
BA_ "GenSigSendType" SG_ 839 HvBattCodPackCodeX2 0;
BA_ "GenSigSendType" SG_ 839 HvBattCodPackCodeX3 0;
BA_ "GenSigSendType" SG_ 839 HvBattCodPackCodeX4 0;
BA_ "GenSigSendType" SG_ 839 HvBattCodPackCodeX5 0;
BA_ "GenSigSendType" SG_ 839 HvBattCodPackCodeX6 0;
BA_ "GenSigSendType" SG_ 839 HvBattCodPackIndex 0;
// Frame: BecmPropFr20
BA_ "GenMsgSendType" BO_ 325 0;
BA_ "GenMsgCycleTime" BO_ 325 100.000;
BA_ "GenSigSendType" SG_ 325 CellUMax 0;
BA_ "GenSigSendType" SG_ 325 CellUMaxId 0;
BA_ "GenSigSendType" SG_ 325 CellUMaxLim 0;
BA_ "GenSigSendType" SG_ 325 CellUMin 0;
BA_ "GenSigSendType" SG_ 325 CellUMinId 0;
// Frame: BecmPropFr21
BA_ "GenMsgSendType" BO_ 648 0;
BA_ "GenMsgCycleTime" BO_ 648 100.000;
BA_ "GenSigSendType" SG_ 648 ACChrgnProximityDetn 0;
BA_ "GenSigStartValue" SG_ 648 ChrgnDchaTyp 15;
BA_ "GenSigSendType" SG_ 648 ChrgnDchaTyp 0;
BA_ "GenSigSendType" SG_ 648 DCChrgSt 0;
BA_ "GenSigSendType" SG_ 648 FastChrgnLEDIndctn 0;
BA_ "GenSigSendType" SG_ 648 HvBattChrgnTiEstimd 0;
BA_ "GenSigSendType" SG_ 648 HvBattWMDSts 0;
BA_ "GenSigStartValue" SG_ 648 HvIsoR 5000;
BA_ "GenSigSendType" SG_ 648 HvIsoR 0;
// Frame: BecmPropFr22
BA_ "GenMsgSendType" BO_ 83 0;
BA_ "GenMsgCycleTime" BO_ 83 100.000;
BA_ "GenSigStartValue" SG_ 83 ChrgEquipIDc 16380;
BA_ "GenSigSendType" SG_ 83 ChrgEquipIDc 0;
BA_ "GenSigSendType" SG_ 83 CpAmp 0;
BA_ "GenSigSendType" SG_ 83 CpDuty 0;
// Frame: BecmPropFr23
BA_ "GenMsgSendType" BO_ 322 0;
BA_ "GenMsgCycleTime" BO_ 322 20.000;
BA_ "GenSigSendType" SG_ 322 HvBattCellUInfoU1 0;
BA_ "GenSigSendType" SG_ 322 HvBattCellUInfoU2 0;
BA_ "GenSigSendType" SG_ 322 HvBattCellUInfoU3 0;
BA_ "GenSigSendType" SG_ 322 HvBattCellUInfoU4 0;
// Frame: BecmPropFr24
BA_ "GenMsgSendType" BO_ 656 0;
BA_ "GenMsgCycleTime" BO_ 656 100.000;
BA_ "GenSigStartValue" SG_ 656 HvBattCellTInfoHvBattSnsrT 40;
BA_ "GenSigSendType" SG_ 656 HvBattCellTInfoHvBattSnsrT 0;
BA_ "GenSigStartValue" SG_ 656 HvBattCellTInfoHvBattTMax 40;
BA_ "GenSigSendType" SG_ 656 HvBattCellTInfoHvBattTMax 0;
BA_ "GenSigStartValue" SG_ 656 HvBattCellTInfoHvBattTMin 40;
BA_ "GenSigSendType" SG_ 656 HvBattCellTInfoHvBattTMin 0;
BA_ "GenSigSendType" SG_ 656 HvBattCellTInfoHvBattTSnsrNr 0;
BA_ "GenSigSendType" SG_ 656 HvBattCellTInfoHvTempSnsrTMaxsSerlNr 0;
BA_ "GenSigSendType" SG_ 656 HvBattCellTInfoHvTempSnsrTMinSerlNr 0;
// Frame: BecmPropFr25
BA_ "GenMsgSendType" BO_ 654 0;
BA_ "GenMsgCycleTime" BO_ 654 1000.000;
BA_ "GenSigSendType" SG_ 654 OnceChrgnEgy 0;
BA_ "GenSigSendType" SG_ 654 OnceDchaEgy 0;
// Frame: BecmPropFr27
BA_ "GenMsgSendType" BO_ 1177 0;
BA_ "GenMsgCycleTime" BO_ 1177 1000.000;
BA_ "GenSigSendType" SG_ 1177 HvBattCap 0;
BA_ "GenSigSendType" SG_ 1177 TotChrgCap 0;
// Frame: BecmPropFr28
BA_ "GenMsgSendType" BO_ 1180 0;
BA_ "GenMsgCycleTime" BO_ 1180 1000.000;
BA_ "GenSigSendType" SG_ 1180 TotDchaCap 0;
// Frame: BecmPropFr29
BA_ "GenMsgSendType" BO_ 1161 0;
BA_ "GenMsgCycleTime" BO_ 1161 900.000;
BA_ "GenSigStartValue" SG_ 1161 HvBattThermInfoInFuturePwrAtTime 500;
BA_ "GenSigSendType" SG_ 1161 HvBattThermInfoInFuturePwrAtTime 0;
BA_ "GenSigSendType" SG_ 1161 HvBattThermInfoInFutureSequenceNo 0;
BA_ "GenSigStartValue" SG_ 1161 HvBattThermInfoInFutureTempAtTime 50;
BA_ "GenSigSendType" SG_ 1161 HvBattThermInfoInFutureTempAtTime 0;
BA_ "GenSigSendType" SG_ 1161 HvBattThermInfoInFutureThermModAtTime 0;
BA_ "GenSigSendType" SG_ 1161 HvBattThermInfoInFutureTime 0;
BA_ "GenSigSendType" SG_ 1161 HvBattThermInfoInFutureVersionNo 0;
// Frame: BecmPropNMFr
BA_ "GenMsgSendType" BO_ 1305 1;
BA_ "GenMsgDelayTime" BO_ 1305 20.000;
BA_ "GenMsgILSupport" BO_ 1305 0;
BA_ "NmAsrMessage" BO_ 1305 1;
// Frame: BecmPropVFCVectorFr
BA_ "GenMsgSendType" BO_ 1345 1;
BA_ "GenMsgDelayTime" BO_ 1345 495.000;
BA_ "GenSigSendType" SG_ 1345 VFCVectorBECMBlockID 1;
BA_ "GenSigSendType" SG_ 1345 VFCVectorBECMVFCid0 1;
BA_ "GenSigSendType" SG_ 1345 VFCVectorBECMVFCid1 1;
BA_ "GenSigSendType" SG_ 1345 VFCVectorBECMVFCid10 1;
BA_ "GenSigSendType" SG_ 1345 VFCVectorBECMVFCid11 1;
BA_ "GenSigSendType" SG_ 1345 VFCVectorBECMVFCid12 1;
BA_ "GenSigSendType" SG_ 1345 VFCVectorBECMVFCid13 1;
BA_ "GenSigSendType" SG_ 1345 VFCVectorBECMVFCid14 1;
BA_ "GenSigSendType" SG_ 1345 VFCVectorBECMVFCid15 1;
BA_ "GenSigSendType" SG_ 1345 VFCVectorBECMVFCid16 1;
BA_ "GenSigSendType" SG_ 1345 VFCVectorBECMVFCid17 1;
BA_ "GenSigSendType" SG_ 1345 VFCVectorBECMVFCid18 1;
BA_ "GenSigSendType" SG_ 1345 VFCVectorBECMVFCid19 1;
BA_ "GenSigSendType" SG_ 1345 VFCVectorBECMVFCid2 1;
BA_ "GenSigSendType" SG_ 1345 VFCVectorBECMVFCid20 1;
BA_ "GenSigSendType" SG_ 1345 VFCVectorBECMVFCid21 1;
BA_ "GenSigSendType" SG_ 1345 VFCVectorBECMVFCid22 1;
BA_ "GenSigSendType" SG_ 1345 VFCVectorBECMVFCid23 1;
BA_ "GenSigSendType" SG_ 1345 VFCVectorBECMVFCid24 1;
BA_ "GenSigSendType" SG_ 1345 VFCVectorBECMVFCid25 1;
BA_ "GenSigSendType" SG_ 1345 VFCVectorBECMVFCid26 1;
BA_ "GenSigSendType" SG_ 1345 VFCVectorBECMVFCid27 1;
BA_ "GenSigSendType" SG_ 1345 VFCVectorBECMVFCid28 1;
BA_ "GenSigSendType" SG_ 1345 VFCVectorBECMVFCid29 1;
BA_ "GenSigSendType" SG_ 1345 VFCVectorBECMVFCid3 1;
BA_ "GenSigSendType" SG_ 1345 VFCVectorBECMVFCid30 1;
BA_ "GenSigSendType" SG_ 1345 VFCVectorBECMVFCid31 1;
BA_ "GenSigSendType" SG_ 1345 VFCVectorBECMVFCid32 1;
BA_ "GenSigSendType" SG_ 1345 VFCVectorBECMVFCid33 1;
BA_ "GenSigSendType" SG_ 1345 VFCVectorBECMVFCid34 1;
BA_ "GenSigSendType" SG_ 1345 VFCVectorBECMVFCid35 1;
BA_ "GenSigSendType" SG_ 1345 VFCVectorBECMVFCid36 1;
BA_ "GenSigSendType" SG_ 1345 VFCVectorBECMVFCid37 1;
BA_ "GenSigSendType" SG_ 1345 VFCVectorBECMVFCid38 1;
BA_ "GenSigSendType" SG_ 1345 VFCVectorBECMVFCid39 1;
BA_ "GenSigSendType" SG_ 1345 VFCVectorBECMVFCid4 1;
BA_ "GenSigSendType" SG_ 1345 VFCVectorBECMVFCid40 1;
BA_ "GenSigSendType" SG_ 1345 VFCVectorBECMVFCid41 1;
BA_ "GenSigSendType" SG_ 1345 VFCVectorBECMVFCid42 1;
BA_ "GenSigSendType" SG_ 1345 VFCVectorBECMVFCid43 1;
BA_ "GenSigSendType" SG_ 1345 VFCVectorBECMVFCid44 1;
BA_ "GenSigSendType" SG_ 1345 VFCVectorBECMVFCid45 1;
BA_ "GenSigSendType" SG_ 1345 VFCVectorBECMVFCid46 1;
BA_ "GenSigSendType" SG_ 1345 VFCVectorBECMVFCid47 1;
BA_ "GenSigSendType" SG_ 1345 VFCVectorBECMVFCid48 1;
BA_ "GenSigSendType" SG_ 1345 VFCVectorBECMVFCid49 1;
BA_ "GenSigSendType" SG_ 1345 VFCVectorBECMVFCid5 1;
BA_ "GenSigSendType" SG_ 1345 VFCVectorBECMVFCid50 1;
BA_ "GenSigSendType" SG_ 1345 VFCVectorBECMVFCid51 1;
BA_ "GenSigSendType" SG_ 1345 VFCVectorBECMVFCid52 1;
BA_ "GenSigSendType" SG_ 1345 VFCVectorBECMVFCid53 1;
BA_ "GenSigSendType" SG_ 1345 VFCVectorBECMVFCid54 1;
BA_ "GenSigSendType" SG_ 1345 VFCVectorBECMVFCid55 1;
BA_ "GenSigSendType" SG_ 1345 VFCVectorBECMVFCid56 1;
BA_ "GenSigSendType" SG_ 1345 VFCVectorBECMVFCid57 1;
BA_ "GenSigSendType" SG_ 1345 VFCVectorBECMVFCid58 1;
BA_ "GenSigSendType" SG_ 1345 VFCVectorBECMVFCid59 1;
BA_ "GenSigSendType" SG_ 1345 VFCVectorBECMVFCid6 1;
BA_ "GenSigSendType" SG_ 1345 VFCVectorBECMVFCid60 1;
BA_ "GenSigSendType" SG_ 1345 VFCVectorBECMVFCid61 1;
BA_ "GenSigSendType" SG_ 1345 VFCVectorBECMVFCid7 1;
BA_ "GenSigSendType" SG_ 1345 VFCVectorBECMVFCid8 1;
BA_ "GenSigSendType" SG_ 1345 VFCVectorBECMVFCid9 1;
// Frame: BecmToVddmPropDiagResFrame
BA_ "GenMsgSendType" BO_ 1589 1;
BA_ "GenMsgDelayTime" BO_ 1589 5.000;
// Frame: BecmToVgmJ1979OBDPropDiagResFrame11
BA_ "GenMsgSendType" BO_ 2026 1;
BA_ "GenMsgDelayTime" BO_ 2026 5.000;
// Frame: CddIgmPropFr01
BA_ "GenMsgSendType" BO_ 331 0;
BA_ "GenMsgCycleTime" BO_ 331 50.000;
BA_ "GenSigSendType" SG_ 331 DcDcActvd 0;
BA_ "GenSigSendType" SG_ 331 FltElecDcDc 0;
BA_ "GenSigSendType" SG_ 331 FltTDcDc 0;
BA_ "GenSigStartValue" SG_ 331 IDcDcActHiSide 4100;
BA_ "GenSigSendType" SG_ 331 IDcDcActHiSide 0;
BA_ "GenSigSendType" SG_ 331 IDcDcAvlMaxLoSide 0;
BA_ "GenSigSendType" SG_ 331 UDcDcActHiSide 0;
// Frame: CddIgmPropFr02
BA_ "GenMsgSendType" BO_ 521 0;
BA_ "GenMsgCycleTime" BO_ 521 50.000;
BA_ "GenSigSendType" SG_ 521 DcDcCoolgReq 0;
BA_ "GenSigSendType" SG_ 521 IDcDcActLoSideChks 0;
BA_ "GenSigFuncType" SG_ 521 IDcDcActLoSideChks 15;
BA_ "GenSigDataID" SG_ 521 IDcDcActLoSideChks "0x14";
BA_ "GenSigSendType" SG_ 521 IDcDcActLoSideCntr 0;
BA_ "GenSigFuncType" SG_ 521 IDcDcActLoSideCntr 16;
BA_ "GenSigSendType" SG_ 521 IDcDcActLoSideIDcDcActLoSide 0;
BA_ "GenSigSendType" SG_ 521 LimnIndcnDcDc 0;
BA_ "GenSigStartValue" SG_ 521 TDcDc 40;
BA_ "GenSigSendType" SG_ 521 TDcDc 0;
// Frame: CddIgmPropFr05
BA_ "GenMsgSendType" BO_ 1109 0;
BA_ "GenMsgCycleTime" BO_ 1109 800.000;
BA_ "GenSigStartValue" SG_ 1109 DcDcMinCooltFlow 20;
BA_ "GenSigSendType" SG_ 1109 DcDcMinCooltFlow 0;
BA_ "GenSigStartValue" SG_ 1109 DcDcNetIntHeatg 1000;
BA_ "GenSigSendType" SG_ 1109 DcDcNetIntHeatg 0;
BA_ "GenSigStartValue" SG_ 1109 TDcDcCoolt 40;
BA_ "GenSigSendType" SG_ 1109 TDcDcCoolt 0;
// Frame: CddObcPropFr01
BA_ "GenMsgSendType" BO_ 536 0;
BA_ "GenMsgCycleTime" BO_ 536 100.000;
BA_ "GenSigSendType" SG_ 536 OnBdChrgrCoolgReq 0;
BA_ "GenSigSendType" SG_ 536 OnBdChrgrErrIndcnReqChks 0;
BA_ "GenSigFuncType" SG_ 536 OnBdChrgrErrIndcnReqChks 15;
BA_ "GenSigDataID" SG_ 536 OnBdChrgrErrIndcnReqChks "0x1A";
BA_ "GenSigSendType" SG_ 536 OnBdChrgrErrIndcnReqCntr 0;
BA_ "GenSigFuncType" SG_ 536 OnBdChrgrErrIndcnReqCntr 16;
BA_ "GenSigSendType" SG_ 536 OnBdChrgrErrIndcnReqOnBdChrgrErrIndcnReq 0;
BA_ "GenSigSendType" SG_ 536 OnBdChrgrHndlSts1 0;
BA_ "GenSigSendType" SG_ 536 OnBdChrgrRdyTi 0;
BA_ "GenSigStartValue" SG_ 536 OnBdChrgrT 40;
BA_ "GenSigSendType" SG_ 536 OnBdChrgrT 0;
BA_ "GenSigSendType" SG_ 536 PwrEgyMgrAvl 0;
// Frame: CddObcPropFr02
BA_ "GenMsgSendType" BO_ 534 0;
BA_ "GenMsgCycleTime" BO_ 534 100.000;
BA_ "GenSigSendType" SG_ 534 DchaIAct 0;
BA_ "GenSigSendType" SG_ 534 DchaPwrAct 0;
BA_ "GenSigSendType" SG_ 534 DchaPwrReq 0;
BA_ "GenSigSendType" SG_ 534 DchaUAct 0;
BA_ "GenSigSendType" SG_ 534 OnBdChrgrClrRdyReq 0;
BA_ "GenSigStartValue" SG_ 534 OnBdChrgrIAct 640;
BA_ "GenSigSendType" SG_ 534 OnBdChrgrIAct 0;
BA_ "GenSigSendType" SG_ 534 OnBdChrgrSt 0;
// Frame: CddObcPropFr03
BA_ "GenMsgSendType" BO_ 298 0;
BA_ "GenMsgCycleTime" BO_ 298 100.000;
BA_ "GenSigSendType" SG_ 298 HndlLockgSts 0;
BA_ "GenSigStartValue" SG_ 298 OnBdChrgrIDc 640;
BA_ "GenSigSendType" SG_ 298 OnBdChrgrIDc 0;
BA_ "GenSigSendType" SG_ 298 OnBdChrgrUAct 0;
BA_ "GenSigSendType" SG_ 298 OnBdChrgrUDc 0;
// Frame: CddObcPropFr04
BA_ "GenMsgSendType" BO_ 1041 0;
BA_ "GenMsgCycleTime" BO_ 1041 400.000;
BA_ "GenSigStartValue" SG_ 1041 OnBdChrgrCooltT 40;
BA_ "GenSigSendType" SG_ 1041 OnBdChrgrCooltT 0;
BA_ "GenSigStartValue" SG_ 1041 OnBdChrgrMinCooltFlow 20;
BA_ "GenSigSendType" SG_ 1041 OnBdChrgrMinCooltFlow 0;
BA_ "GenSigStartValue" SG_ 1041 OnBdChrgrNetIntHeatg 1000;
BA_ "GenSigSendType" SG_ 1041 OnBdChrgrNetIntHeatg 0;
// Frame: DemPropFr01
BA_ "GenMsgSendType" BO_ 1249 1;
BA_ "GenMsgDelayTime" BO_ 1249 1000.000;
BA_ "GenSigSendType" SG_ 1249 DftlCtrlInfo10 1;
BA_ "GenSigSendType" SG_ 1249 DftlCtrlInfo11 1;
BA_ "GenSigSendType" SG_ 1249 DftlCtrlInfo12 1;
BA_ "GenSigSendType" SG_ 1249 DftlCtrlInfo13 1;
BA_ "GenSigSendType" SG_ 1249 DftlCtrlInfo14 1;
BA_ "GenSigSendType" SG_ 1249 DftlCtrlInfo15 1;
BA_ "GenSigSendType" SG_ 1249 DftlCtrlInfo16 1;
BA_ "GenSigSendType" SG_ 1249 DftlCtrlInfo17 1;
// Frame: DemPropFr02
BA_ "GenMsgSendType" BO_ 1250 1;
BA_ "GenMsgDelayTime" BO_ 1250 1000.000;
BA_ "GenSigSendType" SG_ 1250 DftlCtrlInfo20 1;
BA_ "GenSigSendType" SG_ 1250 DftlCtrlInfo21 1;
BA_ "GenSigSendType" SG_ 1250 DftlCtrlInfo22 1;
BA_ "GenSigSendType" SG_ 1250 DftlCtrlInfo23 1;
BA_ "GenSigSendType" SG_ 1250 DftlCtrlInfo24 1;
BA_ "GenSigSendType" SG_ 1250 DftlCtrlInfo25 1;
BA_ "GenSigSendType" SG_ 1250 DftlCtrlInfo26 1;
BA_ "GenSigSendType" SG_ 1250 DftlCtrlInfo27 1;
// Frame: DemPropFr03
BA_ "GenMsgSendType" BO_ 1251 1;
BA_ "GenMsgDelayTime" BO_ 1251 1000.000;
BA_ "GenSigSendType" SG_ 1251 DftlCtrlInfo30 1;
BA_ "GenSigSendType" SG_ 1251 DftlCtrlInfo31 1;
BA_ "GenSigSendType" SG_ 1251 DftlCtrlInfo32 1;
BA_ "GenSigSendType" SG_ 1251 DftlCtrlInfo33 1;
BA_ "GenSigSendType" SG_ 1251 DftlCtrlInfo34 1;
BA_ "GenSigSendType" SG_ 1251 DftlCtrlInfo35 1;
BA_ "GenSigSendType" SG_ 1251 DftlCtrlInfo36 1;
BA_ "GenSigSendType" SG_ 1251 DftlCtrlInfo37 1;
// Frame: DemPropFr04
BA_ "GenMsgSendType" BO_ 1252 1;
BA_ "GenMsgDelayTime" BO_ 1252 1000.000;
BA_ "GenSigSendType" SG_ 1252 DftlCtrlInfo40 1;
BA_ "GenSigSendType" SG_ 1252 DftlCtrlInfo41 1;
BA_ "GenSigSendType" SG_ 1252 DftlCtrlInfo42 1;
BA_ "GenSigSendType" SG_ 1252 DftlCtrlInfo43 1;
BA_ "GenSigSendType" SG_ 1252 DftlCtrlInfo44 1;
BA_ "GenSigSendType" SG_ 1252 DftlCtrlInfo45 1;
BA_ "GenSigSendType" SG_ 1252 DftlCtrlInfo46 1;
BA_ "GenSigSendType" SG_ 1252 DftlCtrlInfo47 1;
// Frame: DemPropFr05
BA_ "GenMsgSendType" BO_ 1253 1;
BA_ "GenMsgDelayTime" BO_ 1253 1000.000;
BA_ "GenSigSendType" SG_ 1253 DftlCtrlInfo50 1;
BA_ "GenSigSendType" SG_ 1253 DftlCtrlInfo51 1;
BA_ "GenSigSendType" SG_ 1253 DftlCtrlInfo52 1;
BA_ "GenSigSendType" SG_ 1253 DftlCtrlInfo53 1;
BA_ "GenSigSendType" SG_ 1253 DftlCtrlInfo54 1;
BA_ "GenSigSendType" SG_ 1253 DftlCtrlInfo55 1;
BA_ "GenSigSendType" SG_ 1253 DftlCtrlInfo56 1;
BA_ "GenSigSendType" SG_ 1253 DftlCtrlInfo57 1;
// Frame: DemPropFr06
BA_ "GenMsgSendType" BO_ 1254 1;
BA_ "GenMsgDelayTime" BO_ 1254 1000.000;
BA_ "GenSigSendType" SG_ 1254 DftlCtrlInfo60 1;
BA_ "GenSigSendType" SG_ 1254 DftlCtrlInfo61 1;
BA_ "GenSigSendType" SG_ 1254 DftlCtrlInfo62 1;
BA_ "GenSigSendType" SG_ 1254 DftlCtrlInfo63 1;
BA_ "GenSigSendType" SG_ 1254 DftlCtrlInfo64 1;
BA_ "GenSigSendType" SG_ 1254 DftlCtrlInfo65 1;
BA_ "GenSigSendType" SG_ 1254 DftlCtrlInfo66 1;
BA_ "GenSigSendType" SG_ 1254 DftlCtrlInfo67 1;
// Frame: DemPropFr08
BA_ "GenMsgSendType" BO_ 294 0;
BA_ "GenMsgCycleTime" BO_ 294 20.000;
BA_ "GenSigSendType" SG_ 294 DftlFltIndcn 0;
BA_ "GenSigSendType" SG_ 294 TrsmStAxleReActr 0;
BA_ "GenSigSendType" SG_ 294 TrsmTqDftlAxleReAct 0;
// Frame: DemPropNMFr
BA_ "GenMsgSendType" BO_ 1310 1;
BA_ "GenMsgDelayTime" BO_ 1310 20.000;
BA_ "GenMsgILSupport" BO_ 1310 0;
BA_ "NmAsrMessage" BO_ 1310 1;
// Frame: DEMtoETCXcpFr01
BA_ "GenMsgSendType" BO_ 1431 1;
BA_ "GenMsgDelayTime" BO_ 1431 20.000;
// Frame: DEMtoETCXcpFr02
BA_ "GenMsgSendType" BO_ 1432 1;
BA_ "GenMsgDelayTime" BO_ 1432 20.000;
// Frame: DEMtoETCXcpFr03
BA_ "GenMsgSendType" BO_ 1433 1;
BA_ "GenMsgDelayTime" BO_ 1433 20.000;
// Frame: DEMtoETCXcpFr04
BA_ "GenMsgSendType" BO_ 1434 1;
BA_ "GenMsgDelayTime" BO_ 1434 20.000;
// Frame: DEMtoETCXcpFr05
BA_ "GenMsgSendType" BO_ 1435 1;
BA_ "GenMsgDelayTime" BO_ 1435 20.000;
// Frame: DEMtoETCXcpFr06
BA_ "GenMsgSendType" BO_ 1436 1;
BA_ "GenMsgDelayTime" BO_ 1436 20.000;
// Frame: DemToVddmPropDiagResFrame
BA_ "GenMsgSendType" BO_ 1592 1;
BA_ "GenMsgDelayTime" BO_ 1592 5.000;
// Frame: EcmPropBSGFr17
BA_ "GenMsgSendType" BO_ 567 0;
BA_ "GenMsgCycleTime" BO_ 567 50.000;
BA_ "GenSigSendType" SG_ 567 MvIsgBltPretensionReq 0;
BA_ "GenSigStartValue" SG_ 567 MvIsgESAEndSpd 10;
BA_ "GenSigSendType" SG_ 567 MvIsgESAEndSpd 0;
BA_ "GenSigStartValue" SG_ 567 MvIsgESAEndSpdGrdt 200;
BA_ "GenSigSendType" SG_ 567 MvIsgESAEndSpdGrdt 0;
BA_ "GenSigStartValue" SG_ 567 MvIsgESATiMax 10;
BA_ "GenSigSendType" SG_ 567 MvIsgESATiMax 0;
BA_ "GenSigSendType" SG_ 567 MvIsgESATqLimn 0;
BA_ "GenSigStartValue" SG_ 567 MvIsgGenTqLimn 10;
BA_ "GenSigSendType" SG_ 567 MvIsgGenTqLimn 0;
BA_ "GenSigStartValue" SG_ 567 MvIsgILimDcha 20;
BA_ "GenSigSendType" SG_ 567 MvIsgILimDcha 0;
BA_ "GenSigStartValue" SG_ 567 MvIsgUReq 480;
BA_ "GenSigSendType" SG_ 567 MvIsgUReq 0;
// Frame: EcmPropBSGFr18
BA_ "GenMsgSendType" BO_ 569 0;
BA_ "GenMsgCycleTime" BO_ 569 50.000;
BA_ "GenSigStartValue" SG_ 569 MvIsgIDcLim 410;
BA_ "GenSigSendType" SG_ 569 MvIsgIDcLim 0;
BA_ "GenSigSendType" SG_ 569 MvIsgSpdStabn 0;
BA_ "GenSigStartValue" SG_ 569 MvIsgStrtrEndSpd 180;
BA_ "GenSigSendType" SG_ 569 MvIsgStrtrEndSpd 0;
BA_ "GenSigStartValue" SG_ 569 MvIsgStrtrSpdGrdt 200;
BA_ "GenSigSendType" SG_ 569 MvIsgStrtrSpdGrdt 0;
BA_ "GenSigStartValue" SG_ 569 MvIsgStrtrTiMax 10;
BA_ "GenSigSendType" SG_ 569 MvIsgStrtrTiMax 0;
BA_ "GenSigStartValue" SG_ 569 MvIsgStrtrTqMax 20;
BA_ "GenSigSendType" SG_ 569 MvIsgStrtrTqMax 0;
// Frame: EcmPropBSGFr19
BA_ "GenMsgSendType" BO_ 68 0;
BA_ "GenMsgCycleTime" BO_ 68 10.000;
BA_ "GenSigSendType" SG_ 68 MvIsgModReqChks 0;
BA_ "GenSigFuncType" SG_ 68 MvIsgModReqChks 15;
BA_ "GenSigDataID" SG_ 68 MvIsgModReqChks "0x0B";
BA_ "GenSigSendType" SG_ 68 MvIsgModReqCntr 0;
BA_ "GenSigFuncType" SG_ 68 MvIsgModReqCntr 16;
BA_ "GenSigSendType" SG_ 68 MvIsgModReqMvIsgModReq 0;
BA_ "GenSigStartValue" SG_ 68 MvIsgTqNegGrdt 10;
BA_ "GenSigSendType" SG_ 68 MvIsgTqNegGrdt 0;
BA_ "GenSigStartValue" SG_ 68 MvIsgTqPosGrdt 10;
BA_ "GenSigSendType" SG_ 68 MvIsgTqPosGrdt 0;
BA_ "GenSigSendType" SG_ 68 MvIsgTqReqChks 0;
BA_ "GenSigFuncType" SG_ 68 MvIsgTqReqChks 15;
BA_ "GenSigDataID" SG_ 68 MvIsgTqReqChks "0x21";
BA_ "GenSigSendType" SG_ 68 MvIsgTqReqCntr 0;
BA_ "GenSigFuncType" SG_ 68 MvIsgTqReqCntr 16;
BA_ "GenSigStartValue" SG_ 68 MvIsgTqReqMvIsgTqReq 700;
BA_ "GenSigSendType" SG_ 68 MvIsgTqReqMvIsgTqReq 0;
// Frame: EcmPropBSGFr20
BA_ "GenMsgSendType" BO_ 333 0;
BA_ "GenMsgCycleTime" BO_ 333 20.000;
BA_ "GenSigSendType" SG_ 333 MvDcDcModReqChks 0;
BA_ "GenSigFuncType" SG_ 333 MvDcDcModReqChks 15;
BA_ "GenSigDataID" SG_ 333 MvDcDcModReqChks "0x1D";
BA_ "GenSigSendType" SG_ 333 MvDcDcModReqCntr 0;
BA_ "GenSigFuncType" SG_ 333 MvDcDcModReqCntr 16;
BA_ "GenSigSendType" SG_ 333 MvDcDcModReqMvDcDcModReq 0;
BA_ "GenSigStartValue" SG_ 333 MvIsgSpdNegGrdt 200;
BA_ "GenSigSendType" SG_ 333 MvIsgSpdNegGrdt 0;
BA_ "GenSigStartValue" SG_ 333 MvIsgSpdPosGrdt 200;
BA_ "GenSigSendType" SG_ 333 MvIsgSpdPosGrdt 0;
BA_ "GenSigStartValue" SG_ 333 MvIsgSpdRgln 60;
BA_ "GenSigSendType" SG_ 333 MvIsgSpdRgln 0;
BA_ "GenSigStartValue" SG_ 333 MvIsgSpdTqPosLim 30;
BA_ "GenSigSendType" SG_ 333 MvIsgSpdTqPosLim 0;
// Frame: EcmPropBSGFr21
BA_ "GenMsgSendType" BO_ 67 0;
BA_ "GenMsgCycleTime" BO_ 67 20.000;
BA_ "GenSigSendType" SG_ 67 MvBattRlyReq 0;
BA_ "GenSigSendType" SG_ 67 MvChrgnUReq 0;
BA_ "GenSigSendType" SG_ 67 MvDcDcModReqSec 0;
BA_ "GenSigSendType" SG_ 67 MvIDcDcMax 0;
BA_ "GenSigSendType" SG_ 67 MvIDcDcMaxSec 0;
BA_ "GenSigStartValue" SG_ 67 MvIsgTqNegAllwd 30;
BA_ "GenSigSendType" SG_ 67 MvIsgTqNegAllwd 0;
BA_ "GenSigSendType" SG_ 67 MvIsgTqPosAllwd 0;
BA_ "GenSigSendType" SG_ 67 MvUDcDcRgInReq 0;
// Frame: EcmPropBSGFr22
BA_ "GenMsgSendType" BO_ 131 0;
BA_ "GenMsgCycleTime" BO_ 131 20.000;
BA_ "GenSigSendType" SG_ 131 ChrgnUReqSec 0;
BA_ "GenSigStartValue" SG_ 131 MvIsgSpdTqNegLim 30;
BA_ "GenSigSendType" SG_ 131 MvIsgSpdTqNegLim 0;
BA_ "GenSigSendType" SG_ 131 SecBattSftySigChks 0;
BA_ "GenSigFuncType" SG_ 131 SecBattSftySigChks 15;
BA_ "GenSigDataID" SG_ 131 SecBattSftySigChks "0x0C";
BA_ "GenSigSendType" SG_ 131 SecBattSftySigCntr 0;
BA_ "GenSigFuncType" SG_ 131 SecBattSftySigCntr 16;
BA_ "GenSigStartValue" SG_ 131 SecBattSftySigSysSaftyBattI 32768;
BA_ "GenSigSendType" SG_ 131 SecBattSftySigSysSaftyBattI 0;
BA_ "GenSigSendType" SG_ 131 SecBattSftySigSysSaftyBattU 0;
// Frame: EcmPropComFr10
BA_ "GenMsgSendType" BO_ 341 0;
BA_ "GenMsgCycleTime" BO_ 341 25.000;
BA_ "GenSigSendType" SG_ 341 EngTiOff 0;
BA_ "GenSigSendType" SG_ 341 PtToTrsmRatMgrIfPtGearReq 0;
BA_ "GenSigSendType" SG_ 341 PtToTrsmRatMgrIfPtGearReqInter 0;
BA_ "GenSigSendType" SG_ 341 PtToTrsmRatMgrIfPtLockFwAtGearFirst 0;
BA_ "GenSigSendType" SG_ 341 PtToTrsmRatMgrIfPtLockUpReq 0;
BA_ "GenSigStartValue" SG_ 341 PtToTrsmRatMgrIfPtLockUpSlipReq 8191;
BA_ "GenSigSendType" SG_ 341 PtToTrsmRatMgrIfPtLockUpSlipReq 0;
BA_ "GenSigSendType" SG_ 341 PtToTrsmRatMgrIfPtShiftTypReq 0;
BA_ "GenSigSendType" SG_ 341 PtToTrsmRatMgrIfPtTrsmModReq 0;
BA_ "GenSigSendType" SG_ 341 TrsmParkLockdChks 0;
BA_ "GenSigFuncType" SG_ 341 TrsmParkLockdChks 15;
BA_ "GenSigDataID" SG_ 341 TrsmParkLockdChks "0x32";
BA_ "GenSigSendType" SG_ 341 TrsmParkLockdCntr 0;
BA_ "GenSigFuncType" SG_ 341 TrsmParkLockdCntr 16;
BA_ "GenSigStartValue" SG_ 341 TrsmParkLockdTrsmParkLockd 3;
BA_ "GenSigSendType" SG_ 341 TrsmParkLockdTrsmParkLockd 0;
// Frame: EcmPropComFr12
BA_ "GenMsgSendType" BO_ 577 0;
BA_ "GenMsgCycleTime" BO_ 577 20.000;
BA_ "GenSigStartValue" SG_ 577 BookChrgTarValLnr 2000;
BA_ "GenSigSendType" SG_ 577 BookChrgTarValLnr 0;
BA_ "GenSigSendType" SG_ 577 EngCooltInhbFlow 0;
BA_ "GenSigSendType" SG_ 577 EngKdSts 0;
BA_ "GenSigSendType" SG_ 577 LoadValCalcd 0;
BA_ "GenSigStartValue" SG_ 577 PtTiToCluEngmt 255;
BA_ "GenSigSendType" SG_ 577 PtTiToCluEngmt 0;
BA_ "GenSigSendType" SG_ 577 TrsmActrKeyChks 0;
BA_ "GenSigFuncType" SG_ 577 TrsmActrKeyChks 15;
BA_ "GenSigDataID" SG_ 577 TrsmActrKeyChks "0x85";
BA_ "GenSigSendType" SG_ 577 TrsmActrKeyCntr 0;
BA_ "GenSigFuncType" SG_ 577 TrsmActrKeyCntr 16;
BA_ "GenSigSendType" SG_ 577 TrsmActrKeyEna 0;
// Frame: EcmPropFr00
BA_ "GenMsgSendType" BO_ 74 0;
BA_ "GenMsgCycleTime" BO_ 74 10.000;
BA_ "GenSigSendType" SG_ 74 AccrPedlLnr 0;
BA_ "GenSigSendType" SG_ 74 AccrPedlRatAccrPedlRat 0;
BA_ "GenSigSendType" SG_ 74 AccrPedlRatChks 0;
BA_ "GenSigFuncType" SG_ 74 AccrPedlRatChks 15;
BA_ "GenSigDataID" SG_ 74 AccrPedlRatChks "0x364";
BA_ "GenSigSendType" SG_ 74 AccrPedlRatCntr 0;
BA_ "GenSigFuncType" SG_ 74 AccrPedlRatCntr 16;
BA_ "GenSigSendType" SG_ 74 IsgSpdReq 0;
// Frame: EcmPropFr01
BA_ "GenMsgSendType" BO_ 80 0;
BA_ "GenMsgCycleTime" BO_ 80 10.000;
BA_ "GenSigSendType" SG_ 80 IsgModReq 0;
BA_ "GenSigStartValue" SG_ 80 IsgTqReq 8188;
BA_ "GenSigSendType" SG_ 80 IsgTqReq 0;
BA_ "GenSigSendType" SG_ 80 PrpsnTqFrntReq 0;
BA_ "GenSigStartValue" SG_ 80 PtCluTqReq 1024;
BA_ "GenSigSendType" SG_ 80 PtCluTqReq 0;
// Frame: EcmPropFr02
BA_ "GenMsgSendType" BO_ 102 0;
BA_ "GenMsgCycleTime" BO_ 102 15.000;
BA_ "GenSigSendType" SG_ 102 EngNSafeEngN 0;
BA_ "GenSigSendType" SG_ 102 EngNSafeEngNChks 0;
BA_ "GenSigFuncType" SG_ 102 EngNSafeEngNChks 15;
BA_ "GenSigDataID" SG_ 102 EngNSafeEngNChks "0x44";
BA_ "GenSigSendType" SG_ 102 EngNSafeEngNCntr 0;
BA_ "GenSigFuncType" SG_ 102 EngNSafeEngNCntr 16;
BA_ "GenSigSendType" SG_ 102 EngNSafeEngNGrdt 0;
BA_ "GenSigSendType" SG_ 102 EngTqLimDly 0;
BA_ "GenSigSendType" SG_ 102 PtGearAct 0;
BA_ "GenSigSendType" SG_ 102 WhlMotSysModReq 0;
// Frame: EcmPropFr03
BA_ "GenMsgSendType" BO_ 277 0;
BA_ "GenMsgCycleTime" BO_ 277 15.000;
BA_ "GenSigStartValue" SG_ 277 PtCluTqDyn 1024;
BA_ "GenSigSendType" SG_ 277 PtCluTqDyn 0;
BA_ "GenSigStartValue" SG_ 277 PtCluTqPtCluTq 1024;
BA_ "GenSigSendType" SG_ 277 PtCluTqPtCluTq 0;
BA_ "GenSigSendType" SG_ 277 PtCluTqQly 0;
BA_ "GenSigStartValue" SG_ 277 PtCluTqReqWoTrsmIntv 1024;
BA_ "GenSigSendType" SG_ 277 PtCluTqReqWoTrsmIntv 0;
BA_ "GenSigSendType" SG_ 277 PtDirAllwdToTrsmActrAuxChks 0;
BA_ "GenSigFuncType" SG_ 277 PtDirAllwdToTrsmActrAuxChks 15;
BA_ "GenSigDataID" SG_ 277 PtDirAllwdToTrsmActrAuxChks "0xC5";
BA_ "GenSigSendType" SG_ 277 PtDirAllwdToTrsmActrAuxCntr 0;
BA_ "GenSigFuncType" SG_ 277 PtDirAllwdToTrsmActrAuxCntr 16;
BA_ "GenSigSendType" SG_ 277 PtDirAllwdToTrsmActrAuxFwd 0;
BA_ "GenSigSendType" SG_ 277 PtDirAllwdToTrsmActrAuxNeut 0;
BA_ "GenSigSendType" SG_ 277 PtDirAllwdToTrsmActrAuxParkRls 0;
BA_ "GenSigSendType" SG_ 277 PtDirAllwdToTrsmActrAuxRvs 0;
BA_ "GenSigStartValue" SG_ 277 PtReqToTrsmActr 4;
BA_ "GenSigSendType" SG_ 277 PtReqToTrsmActr 0;
// Frame: EcmPropFr04
BA_ "GenMsgSendType" BO_ 305 0;
BA_ "GenMsgCycleTime" BO_ 305 20.000;
BA_ "GenSigSendType" SG_ 305 DcDcActvdReq 0;
BA_ "GenSigSendType" SG_ 305 DispHvBattLvlOfChrg 0;
BA_ "GenSigSendType" SG_ 305 IsgActvDampgGain 0;
BA_ "GenSigSendType" SG_ 305 PtAllwdToTrsmActrSafeChks 0;
BA_ "GenSigFuncType" SG_ 305 PtAllwdToTrsmActrSafeChks 15;
BA_ "GenSigDataID" SG_ 305 PtAllwdToTrsmActrSafeChks "0x3F";
BA_ "GenSigSendType" SG_ 305 PtAllwdToTrsmActrSafeCntr 0;
BA_ "GenSigFuncType" SG_ 305 PtAllwdToTrsmActrSafeCntr 16;
BA_ "GenSigSendType" SG_ 305 PtAllwdToTrsmActrSafePtAllwdToTrsmActr 0;
BA_ "GenSigSendType" SG_ 305 WhlMotSysPwrLimMax 0;
// Frame: EcmPropFr05
BA_ "GenMsgSendType" BO_ 405 0;
BA_ "GenMsgCycleTime" BO_ 405 25.000;
BA_ "GenSigSendType" SG_ 405 HvPwrEgyPrio 0;
BA_ "GenSigSendType" SG_ 405 IsgPwrLimMax 0;
BA_ "GenSigStartValue" SG_ 405 IsgPwrLimMin 1022;
BA_ "GenSigSendType" SG_ 405 IsgPwrLimMin 0;
BA_ "GenSigSendType" SG_ 405 OnBdChrgrPwrEnaAllwd 0;
BA_ "GenSigSendType" SG_ 405 WhlMotSysTqAllwdChks 0;
BA_ "GenSigFuncType" SG_ 405 WhlMotSysTqAllwdChks 15;
BA_ "GenSigDataID" SG_ 405 WhlMotSysTqAllwdChks "0x4F";
BA_ "GenSigSendType" SG_ 405 WhlMotSysTqAllwdCntr 0;
BA_ "GenSigFuncType" SG_ 405 WhlMotSysTqAllwdCntr 16;
BA_ "GenSigSendType" SG_ 405 WhlMotSysTqAllwdWhlMotSysTqAllwd 0;
// Frame: EcmPropFr06
BA_ "GenMsgSendType" BO_ 816 0;
BA_ "GenMsgCycleTime" BO_ 816 260.000;
BA_ "GenSigSendType" SG_ 816 HvCooltHeatrStsSig 0;
BA_ "GenSigStartValue" SG_ 816 HvCooltWtrHeatrWtrTInOutl 40;
BA_ "GenSigSendType" SG_ 816 HvCooltWtrHeatrWtrTInOutl 0;
// Frame: EcmPropFr07
BA_ "GenMsgSendType" BO_ 512 0;
BA_ "GenMsgCycleTime" BO_ 512 25.000;
BA_ "GenSigSendType" SG_ 512 PtTqAtWhlFrntActPtTqAtWhlFrntAct 0;
BA_ "GenSigSendType" SG_ 512 PtTqAtWhlFrntActPtTqAtWhlFrntLeAct 0;
BA_ "GenSigSendType" SG_ 512 PtTqAtWhlFrntActPtTqAtWhlFrntQly 0;
BA_ "GenSigSendType" SG_ 512 PtTqAtWhlFrntActPtTqAtWhlFrntRiAct 0;
BA_ "GenSigSendType" SG_ 512 PtTqAtWhlFrntActRecChks 0;
BA_ "GenSigFuncType" SG_ 512 PtTqAtWhlFrntActRecChks 15;
BA_ "GenSigDataID" SG_ 512 PtTqAtWhlFrntActRecChks "0x4E";
BA_ "GenSigSendType" SG_ 512 PtTqAtWhlFrntActRecCntr 0;
BA_ "GenSigFuncType" SG_ 512 PtTqAtWhlFrntActRecCntr 16;
// Frame: EcmPropFr08
BA_ "GenMsgSendType" BO_ 545 0;
BA_ "GenMsgCycleTime" BO_ 545 50.000;
BA_ "GenSigSendType" SG_ 545 EngNLim 0;
BA_ "GenSigStartValue" SG_ 545 EngTEngT 50;
BA_ "GenSigSendType" SG_ 545 EngTEngT 0;
BA_ "GenSigSendType" SG_ 545 EngTQf 0;
BA_ "GenSigSendType" SG_ 545 GearLvrEna 0;
BA_ "GenSigStartValue" SG_ 545 HvBattCoolgCmd 1;
BA_ "GenSigSendType" SG_ 545 HvBattCoolgCmd 0;
BA_ "GenSigStartValue" SG_ 545 HvOnMaiReq 2;
BA_ "GenSigSendType" SG_ 545 HvOnMaiReq 0;
BA_ "GenSigStartValue" SG_ 545 IsgActvDampgModReq 2;
BA_ "GenSigSendType" SG_ 545 IsgActvDampgModReq 0;
BA_ "GenSigSendType" SG_ 545 PrpsnFbLimnIndcn 0;
BA_ "GenSigSendType" SG_ 545 PtRatMgrMod 0;
BA_ "GenSigSendType" SG_ 545 ThrPos 0;
BA_ "GenSigSendType" SG_ 545 WrmUpCyc 0;
// Frame: EcmPropFr09
BA_ "GenMsgSendType" BO_ 592 0;
BA_ "GenMsgCycleTime" BO_ 592 70.000;
BA_ "GenSigSendType" SG_ 592 AltIAvlAtIdle 0;
BA_ "GenSigSendType" SG_ 592 EngEffSts 0;
BA_ "GenSigSendType" SG_ 592 EngIdleCtrlRefVal 0;
BA_ "GenSigStartValue" SG_ 592 HvBattChrgnCmd 1;
BA_ "GenSigSendType" SG_ 592 HvBattChrgnCmd 0;
BA_ "GenSigSendType" SG_ 592 ObdAccrPedRat 0;
BA_ "GenSigSendType" SG_ 592 PtRatMgrAdpvMod 0;
// Frame: EcmPropFr11
BA_ "GenMsgSendType" BO_ 647 0;
BA_ "GenMsgCycleTime" BO_ 647 300.000;
BA_ "GenSigSendType" SG_ 647 BookChargeSetResponse 0;
BA_ "GenSigStartValue" SG_ 647 ChrgnSts 3;
BA_ "GenSigSendType" SG_ 647 ChrgnSts 0;
BA_ "GenSigSendType" SG_ 647 CmptmtCoolgSts 0;
BA_ "GenSigSendType" SG_ 647 CooltFlowForDtElec 0;
BA_ "GenSigStartValue" SG_ 647 CooltTSigForDtElec 400;
BA_ "GenSigSendType" SG_ 647 CooltTSigForDtElec 0;
BA_ "GenSigSendType" SG_ 647 DeactvtTestCom 0;
BA_ "GenSigStartValue" SG_ 647 EngAmbTCalcd 120;
BA_ "GenSigSendType" SG_ 647 EngAmbTCalcd 0;
BA_ "GenSigStartValue" SG_ 647 HvConvPwrAllwd 1023;
BA_ "GenSigSendType" SG_ 647 HvConvPwrAllwd 0;
BA_ "GenSigSendType" SG_ 647 MonrCycCmpl 0;
BA_ "GenSigSendType" SG_ 647 PrpsnSysActv 0;
// Frame: EcmPropFr14
BA_ "GenMsgSendType" BO_ 1160 0;
BA_ "GenMsgCycleTime" BO_ 1160 800.000;
BA_ "GenSigStartValue" SG_ 1160 HvBattThermInfoCorrInFuturePwrAtTime 500;
BA_ "GenSigSendType" SG_ 1160 HvBattThermInfoCorrInFuturePwrAtTime 0;
BA_ "GenSigSendType" SG_ 1160 HvBattThermInfoCorrInFutureSequenceNo 0;
BA_ "GenSigStartValue" SG_ 1160 HvBattThermInfoCorrInFutureTempAtTime 50;
BA_ "GenSigSendType" SG_ 1160 HvBattThermInfoCorrInFutureTempAtTime 0;
BA_ "GenSigSendType" SG_ 1160 HvBattThermInfoCorrInFutureThermModAtTime 0;
BA_ "GenSigSendType" SG_ 1160 HvBattThermInfoCorrInFutureTime 0;
BA_ "GenSigSendType" SG_ 1160 HvBattThermInfoCorrInFutureVersionNo 0;
// Frame: EcmPropFr22
BA_ "GenMsgSendType" BO_ 586 0;
BA_ "GenMsgCycleTime" BO_ 586 70.000;
BA_ "GenSigSendType" SG_ 586 DchaPwrAllwd 0;
BA_ "GenSigSendType" SG_ 586 HvBattChrgnPwrAllwd1 0;
BA_ "GenSigSendType" SG_ 586 HvBattFlwEstmd 0;
BA_ "GenSigSendType" SG_ 586 HvBattThermReqFb 0;
// Frame: EcmPropFr24
BA_ "GenMsgSendType" BO_ 75 0;
BA_ "GenMsgCycleTime" BO_ 75 15.000;
BA_ "GenSigSendType" SG_ 75 DrvrDesDirChks 0;
BA_ "GenSigFuncType" SG_ 75 DrvrDesDirChks 15;
BA_ "GenSigDataID" SG_ 75 DrvrDesDirChks "0x273";
BA_ "GenSigSendType" SG_ 75 DrvrDesDirCntr 0;
BA_ "GenSigFuncType" SG_ 75 DrvrDesDirCntr 16;
BA_ "GenSigSendType" SG_ 75 DrvrDesDirDrvrDesDir 0;
BA_ "GenSigSendType" SG_ 75 EngSt1WdStsChks 0;
BA_ "GenSigFuncType" SG_ 75 EngSt1WdStsChks 15;
BA_ "GenSigDataID" SG_ 75 EngSt1WdStsChks "0x89";
BA_ "GenSigSendType" SG_ 75 EngSt1WdStsCntr 0;
BA_ "GenSigFuncType" SG_ 75 EngSt1WdStsCntr 16;
BA_ "GenSigSendType" SG_ 75 EngSt1WdStsEngSt1WdSts 0;
BA_ "GenSigStartValue" SG_ 75 GearLvrIndcn 7;
BA_ "GenSigSendType" SG_ 75 GearLvrIndcn 0;
BA_ "GenSigSendType" SG_ 75 HvchSts 0;
BA_ "GenSigStartValue" SG_ 75 WhlMotSysTqReq 2047;
BA_ "GenSigSendType" SG_ 75 WhlMotSysTqReq 0;
// Frame: MvbmToVgmJ1979OBDPropCanResFrame11
BA_ "GenMsgSendType" BO_ 2026 1;
BA_ "GenMsgDelayTime" BO_ 2026 5.000;

VAL_ 321 HvSysActvnInhb 0 "OkNotOk1_Ok" 1 "OkNotOk1_NotOk";
VAL_ 321 HvSysPwrOff 0 "OkNotOk1_Ok" 1 "OkNotOk1_NotOk";
VAL_ 321 HvSysRlyStsHvSysRlySts 0 "HvActvnSts_Open" 1 "HvActvnSts_Clsd" 2 "HvActvnSts_KeepSt" 3 "HvActvnSts_OpenAndReqActvDcha";
VAL_ 321 HvSysSts 0 "HvSysSts_Inin" 1 "HvSysSts_Test" 2 "HvSysSts_Rdy";
VAL_ 373 ACChrgnConnectSts 0 "ConnectionSts_Disconnect" 1 "ConnectionSts_Connect";
VAL_ 373 ACChrgnCPSts 0 "Normalwarning_Normal" 1 "Normalwarning_Warning";
VAL_ 373 ACChrgnS2Sts 0 "OpenClose_Open" 1 "OpenClose_Close";
VAL_ 373 MaintainBattTFb 0 "BookChrgnStsFb_Default" 1 "BookChrgnStsFb_Success" 2 "BookChrgnStsFb_Fail" 3 "BookChrgnStsFb_Finished";
VAL_ 581 HvBattChrgnCmpl 0 "NoYes1_No" 1 "NoYes1_Yes";
VAL_ 581 HvBattCoolgReq 0 "HvBattCoolgReq_NotReqd" 1 "HvBattCoolgReq_LoReq" 2 "HvBattCoolgReq_MedReq" 3 "HvBattCoolgReq_HiReq";
VAL_ 659 HvBattErrIndcnReq 0 "OnOff1_Off" 1 "OnOff1_On";
VAL_ 659 HvBattHeatgReq 0 "HvBattCoolgReq_NotReqd" 1 "HvBattCoolgReq_LoReq" 2 "HvBattCoolgReq_MedReq" 3 "HvBattCoolgReq_HiReq";
VAL_ 661 HvBattCoolgSts 0 "ClimaSts_Start" 1 "ClimaSts_Finish";
VAL_ 661 HVIL1Sts 0 "OpenClose_Open" 1 "OpenClose_Close";
VAL_ 661 HVIL2Sts 0 "OpenClose_Open" 1 "OpenClose_Close";
VAL_ 661 HVIL3Sts 0 "OpenClose_Open" 1 "OpenClose_Close";
VAL_ 661 HvIsoSts 0 "Insulation_Default" 1 "Insulation_Error_Battery_before_HV_Ready" 2 "Insulation_Error_HV_bus_after_HV_Ready" 3 "Insulation_OK";
VAL_ 661 HvSysCrashFb 0 "CrashFb_Idle" 1 "CrashFb_Evln" 2 "CrashFb_Nok" 3 "CrashFb_Ok";
VAL_ 662 FastChrgnLockCtrl 0 "OnOff1_Off" 1 "OnOff1_On";
VAL_ 834 HvBattMismatchFlt 0 "DevErrSts2_NoFlt" 1 "DevErrSts2_Flt";
VAL_ 834 HvCellTDifFlt 0 "FauLevel_Normal" 1 "FauLevel_LevelI" 2 "FauLevel_LevelII" 3 "FauLevel_LevelIII";
VAL_ 834 HvCellTOverFlt 0 "FauLevel_Normal" 1 "FauLevel_LevelI" 2 "FauLevel_LevelII" 3 "FauLevel_LevelIII";
VAL_ 834 HvCellUDifFlt 0 "FauLevel_Normal" 1 "FauLevel_LevelI" 2 "FauLevel_LevelII" 3 "FauLevel_LevelIII";
VAL_ 834 HvCellUOverFlt 0 "FauLevel_Normal" 1 "FauLevel_LevelI" 2 "FauLevel_LevelII" 3 "FauLevel_LevelIII";
VAL_ 834 HvCellUUnderFlt 0 "FauLevel_Normal" 1 "FauLevel_LevelI" 2 "FauLevel_LevelII" 3 "FauLevel_LevelIII";
VAL_ 834 HvilFlt 0 "DevErrSts2_NoFlt" 1 "DevErrSts2_Flt";
VAL_ 834 HvIsoFlt 0 "FauLevel_Normal" 1 "FauLevel_LevelI" 2 "FauLevel_LevelII" 3 "FauLevel_LevelIII";
VAL_ 834 HvPackOverChrgFlt 0 "FauLevel_Normal" 1 "FauLevel_LevelI" 2 "FauLevel_LevelII" 3 "FauLevel_LevelIII";
VAL_ 834 HvPackUOverFlt 0 "FauLevel_Normal" 1 "FauLevel_LevelI" 2 "FauLevel_LevelII" 3 "FauLevel_LevelIII";
VAL_ 834 HvPackUUnderFlt 0 "FauLevel_Normal" 1 "FauLevel_LevelI" 2 "FauLevel_LevelII" 3 "FauLevel_LevelIII";
VAL_ 834 HvSocHiFlt 0 "FauLevel_Normal" 1 "FauLevel_LevelI" 2 "FauLevel_LevelII" 3 "FauLevel_LevelIII";
VAL_ 834 HvSocHopFlt 0 "FauLevel_Normal" 1 "FauLevel_LevelI" 2 "FauLevel_LevelII" 3 "FauLevel_LevelIII";
VAL_ 834 HvSocLoFlt 0 "FauLevel_Normal" 1 "FauLevel_LevelI" 2 "FauLevel_LevelII" 3 "FauLevel_LevelIII";
VAL_ 789 HvBattChrgnSts 0 "ClimaSts_Start" 1 "ClimaSts_Finish";
VAL_ 646 HvBattPreHeatFaild 0 "OnOff1_Off" 1 "OnOff1_On";
VAL_ 323 DCChrgnHndlSts 0 "OnBdChrgrHndlSts_Disconnected" 1 "OnBdChrgrHndlSts_ConnectedWithoutPower" 2 "OnBdChrgrHndlSts_PowerAvailableButNotActivated" 3 "OnBdChrgrHndlSts_ConnectedWithPower" 4 "OnBdChrgrHndlSts_Init" 5 "OnBdChrgrHndlSts_Fault";
VAL_ 833 HvBattClrRdyReq 0 "OnOff1_Off" 1 "OnOff1_On";
VAL_ 837 HvBattPreHeatgReq 0 "PreHeatgReq_Default" 1 "PreHeatgReq_On" 2 "PreHeatgReq_Off" 3 "PreHeatgReq_Reserved";
VAL_ 837 HvBattThermMod 0 "HvBattThermMod_Idle" 1 "HvBattThermMod_ThermalBalancing" 2 "HvBattThermMod_PassiveHeating" 3 "HvBattThermMod_ActiveHeating" 4 "HvBattThermMod_PassiveCooling" 5 "HvBattThermMod_ActiveCooling" 6 "HvBattThermMod_CombinedCooling" 7 "HvBattThermMod_Reserved";
VAL_ 838 HvBattCooltLvl 0 "HvBattCooltLvl_Full" 1 "HvBattCooltLvl_Empty";
VAL_ 648 DCChrgSt 0 "ChrgrSts1_Idle" 1 "ChrgrSts1_PreStrt" 2 "ChrgrSts1_Chrgn" 3 "ChrgrSts1_Alrm" 4 "ChrgrSts1_Srv" 5 "ChrgrSts1_Diagc" 6 "ChrgrSts1_Boot" 7 "ChrgrSts1_Rstrt" 8 "ChrgrSts1_DisChrgn" 9 "ChrgrSts1_BookChrgn" 10 "ChrgrSts1_Shutdown" 11 "ChrgrSts1_Heating" 12 "ChrgrSts1_Cooling";
VAL_ 648 FastChrgnLEDIndctn 0 "FastChrgnLEDIndctn_Default" 1 "FastChrgnLEDIndctn_Green1" 2 "FastChrgnLEDIndctn_Green2" 3 "FastChrgnLEDIndctn_Green3" 4 "FastChrgnLEDIndctn_Green4" 5 "FastChrgnLEDIndctn_Red" 6 "FastChrgnLEDIndctn_Green5" 7 "FastChrgnLEDIndctn_Reserved";
VAL_ 1161 HvBattThermInfoInFutureThermModAtTime 0 "Idle" 1 "ThermalBalancing" 2 "PassiveHeating" 3 "ActiveHeating" 4 "PassiveCooling" 5 "ActiveCooling" 6 "CombinedCooling" 7 "Reserved";
VAL_ 1345 VFCVectorBECMVFCid0 0 "VFCOnOff_Off" 1 "VFCOnOff_On";
VAL_ 1345 VFCVectorBECMVFCid1 0 "VFCOnOff_Off" 1 "VFCOnOff_On";
VAL_ 1345 VFCVectorBECMVFCid10 0 "VFCOnOff_Off" 1 "VFCOnOff_On";
VAL_ 1345 VFCVectorBECMVFCid11 0 "VFCOnOff_Off" 1 "VFCOnOff_On";
VAL_ 1345 VFCVectorBECMVFCid12 0 "VFCOnOff_Off" 1 "VFCOnOff_On";
VAL_ 1345 VFCVectorBECMVFCid13 0 "VFCOnOff_Off" 1 "VFCOnOff_On";
VAL_ 1345 VFCVectorBECMVFCid14 0 "VFCOnOff_Off" 1 "VFCOnOff_On";
VAL_ 1345 VFCVectorBECMVFCid15 0 "VFCOnOff_Off" 1 "VFCOnOff_On";
VAL_ 1345 VFCVectorBECMVFCid16 0 "VFCOnOff_Off" 1 "VFCOnOff_On";
VAL_ 1345 VFCVectorBECMVFCid17 0 "VFCOnOff_Off" 1 "VFCOnOff_On";
VAL_ 1345 VFCVectorBECMVFCid18 0 "VFCOnOff_Off" 1 "VFCOnOff_On";
VAL_ 1345 VFCVectorBECMVFCid19 0 "VFCOnOff_Off" 1 "VFCOnOff_On";
VAL_ 1345 VFCVectorBECMVFCid2 0 "VFCOnOff_Off" 1 "VFCOnOff_On";
VAL_ 1345 VFCVectorBECMVFCid20 0 "VFCOnOff_Off" 1 "VFCOnOff_On";
VAL_ 1345 VFCVectorBECMVFCid21 0 "VFCOnOff_Off" 1 "VFCOnOff_On";
VAL_ 1345 VFCVectorBECMVFCid22 0 "VFCOnOff_Off" 1 "VFCOnOff_On";
VAL_ 1345 VFCVectorBECMVFCid23 0 "VFCOnOff_Off" 1 "VFCOnOff_On";
VAL_ 1345 VFCVectorBECMVFCid24 0 "VFCOnOff_Off" 1 "VFCOnOff_On";
VAL_ 1345 VFCVectorBECMVFCid25 0 "VFCOnOff_Off" 1 "VFCOnOff_On";
VAL_ 1345 VFCVectorBECMVFCid26 0 "VFCOnOff_Off" 1 "VFCOnOff_On";
VAL_ 1345 VFCVectorBECMVFCid27 0 "VFCOnOff_Off" 1 "VFCOnOff_On";
VAL_ 1345 VFCVectorBECMVFCid28 0 "VFCOnOff_Off" 1 "VFCOnOff_On";
VAL_ 1345 VFCVectorBECMVFCid29 0 "VFCOnOff_Off" 1 "VFCOnOff_On";
VAL_ 1345 VFCVectorBECMVFCid3 0 "VFCOnOff_Off" 1 "VFCOnOff_On";
VAL_ 1345 VFCVectorBECMVFCid30 0 "VFCOnOff_Off" 1 "VFCOnOff_On";
VAL_ 1345 VFCVectorBECMVFCid31 0 "VFCOnOff_Off" 1 "VFCOnOff_On";
VAL_ 1345 VFCVectorBECMVFCid32 0 "VFCOnOff_Off" 1 "VFCOnOff_On";
VAL_ 1345 VFCVectorBECMVFCid33 0 "VFCOnOff_Off" 1 "VFCOnOff_On";
VAL_ 1345 VFCVectorBECMVFCid34 0 "VFCOnOff_Off" 1 "VFCOnOff_On";
VAL_ 1345 VFCVectorBECMVFCid35 0 "VFCOnOff_Off" 1 "VFCOnOff_On";
VAL_ 1345 VFCVectorBECMVFCid36 0 "VFCOnOff_Off" 1 "VFCOnOff_On";
VAL_ 1345 VFCVectorBECMVFCid37 0 "VFCOnOff_Off" 1 "VFCOnOff_On";
VAL_ 1345 VFCVectorBECMVFCid38 0 "VFCOnOff_Off" 1 "VFCOnOff_On";
VAL_ 1345 VFCVectorBECMVFCid39 0 "VFCOnOff_Off" 1 "VFCOnOff_On";
VAL_ 1345 VFCVectorBECMVFCid4 0 "VFCOnOff_Off" 1 "VFCOnOff_On";
VAL_ 1345 VFCVectorBECMVFCid40 0 "VFCOnOff_Off" 1 "VFCOnOff_On";
VAL_ 1345 VFCVectorBECMVFCid41 0 "VFCOnOff_Off" 1 "VFCOnOff_On";
VAL_ 1345 VFCVectorBECMVFCid42 0 "VFCOnOff_Off" 1 "VFCOnOff_On";
VAL_ 1345 VFCVectorBECMVFCid43 0 "VFCOnOff_Off" 1 "VFCOnOff_On";
VAL_ 1345 VFCVectorBECMVFCid44 0 "VFCOnOff_Off" 1 "VFCOnOff_On";
VAL_ 1345 VFCVectorBECMVFCid45 0 "VFCOnOff_Off" 1 "VFCOnOff_On";
VAL_ 1345 VFCVectorBECMVFCid46 0 "VFCOnOff_Off" 1 "VFCOnOff_On";
VAL_ 1345 VFCVectorBECMVFCid47 0 "VFCOnOff_Off" 1 "VFCOnOff_On";
VAL_ 1345 VFCVectorBECMVFCid48 0 "VFCOnOff_Off" 1 "VFCOnOff_On";
VAL_ 1345 VFCVectorBECMVFCid49 0 "VFCOnOff_Off" 1 "VFCOnOff_On";
VAL_ 1345 VFCVectorBECMVFCid5 0 "VFCOnOff_Off" 1 "VFCOnOff_On";
VAL_ 1345 VFCVectorBECMVFCid50 0 "VFCOnOff_Off" 1 "VFCOnOff_On";
VAL_ 1345 VFCVectorBECMVFCid51 0 "VFCOnOff_Off" 1 "VFCOnOff_On";
VAL_ 1345 VFCVectorBECMVFCid52 0 "VFCOnOff_Off" 1 "VFCOnOff_On";
VAL_ 1345 VFCVectorBECMVFCid53 0 "VFCOnOff_Off" 1 "VFCOnOff_On";
VAL_ 1345 VFCVectorBECMVFCid54 0 "VFCOnOff_Off" 1 "VFCOnOff_On";
VAL_ 1345 VFCVectorBECMVFCid55 0 "VFCOnOff_Off" 1 "VFCOnOff_On";
VAL_ 1345 VFCVectorBECMVFCid56 0 "VFCOnOff_Off" 1 "VFCOnOff_On";
VAL_ 1345 VFCVectorBECMVFCid57 0 "VFCOnOff_Off" 1 "VFCOnOff_On";
VAL_ 1345 VFCVectorBECMVFCid58 0 "VFCOnOff_Off" 1 "VFCOnOff_On";
VAL_ 1345 VFCVectorBECMVFCid59 0 "VFCOnOff_Off" 1 "VFCOnOff_On";
VAL_ 1345 VFCVectorBECMVFCid6 0 "VFCOnOff_Off" 1 "VFCOnOff_On";
VAL_ 1345 VFCVectorBECMVFCid60 0 "VFCOnOff_Off" 1 "VFCOnOff_On";
VAL_ 1345 VFCVectorBECMVFCid61 0 "VFCOnOff_Off" 1 "VFCOnOff_On";
VAL_ 1345 VFCVectorBECMVFCid7 0 "VFCOnOff_Off" 1 "VFCOnOff_On";
VAL_ 1345 VFCVectorBECMVFCid8 0 "VFCOnOff_Off" 1 "VFCOnOff_On";
VAL_ 1345 VFCVectorBECMVFCid9 0 "VFCOnOff_Off" 1 "VFCOnOff_On";
VAL_ 331 DcDcActvd 0 "DcDcActvd_NoConversionToLVSide" 1 "DcDcActvd_ConversionToLVSide";
VAL_ 331 FltElecDcDc 0 "DevErrSts2_NoFlt" 1 "DevErrSts2_Flt";
VAL_ 331 FltTDcDc 0 "DevErrSts2_NoFlt" 1 "DevErrSts2_Flt";
VAL_ 521 DcDcCoolgReq 0 "HvCoolg1_NoRequestForMoreCoolantPower" 1 "HvCoolg1_IncreaseLevel1ForMoreCoolantPower" 2 "HvCoolg1_IncreaseLevel2ForMoreCoolantPower" 3 "HvCoolg1_MaxCoolingPower" 4 "HvCoolg1_NotDefined";
VAL_ 536 OnBdChrgrCoolgReq 0 "HvCoolg1_NoRequestForMoreCoolantPower" 1 "HvCoolg1_IncreaseLevel1ForMoreCoolantPower" 2 "HvCoolg1_IncreaseLevel2ForMoreCoolantPower" 3 "HvCoolg1_MaxCoolingPower" 4 "HvCoolg1_NotDefined";
VAL_ 536 OnBdChrgrErrIndcnReqOnBdChrgrErrIndcnReq 0 "OnOff1_Off" 1 "OnOff1_On";
VAL_ 536 OnBdChrgrHndlSts1 0 "OnBdChrgrHndlSts1_Disconnected" 1 "OnBdChrgrHndlSts1_ConnectedWithoutPower" 2 "OnBdChrgrHndlSts1_PowerAvailableButNotActivated" 3 "OnBdChrgrHndlSts1_ConnectedWithPower" 4 "OnBdChrgrHndlSts1_DischargeConnectwithoutpowerincar" 5 "OnBdChrgrHndlSts1_DischargeConnectwithoutpoweroutcar" 6 "OnBdChrgrHndlSts1_DischargeConnectwithpowerincar" 7 "OnBdChrgrHndlSts1_DischargeConnectwithpoweroutcar" 8 "OnBdChrgrHndlSts1_Init" 9 "OnBdChrgrHndlSts1_Fault" 10 "OnBdChrgrHndlSts1_NotCompleteConnnected" 11 "OnBdChrgrHndlSts1_Reserved0" 12 "OnBdChrgrHndlSts1_Reserved1" 13 "OnBdChrgrHndlSts1_Reserved2";
VAL_ 534 OnBdChrgrClrRdyReq 0 "OnOff1_Off" 1 "OnOff1_On";
VAL_ 534 OnBdChrgrSt 0 "ChrgrSts1_Idle" 1 "ChrgrSts1_PreStrt" 2 "ChrgrSts1_Chrgn" 3 "ChrgrSts1_Alrm" 4 "ChrgrSts1_Srv" 5 "ChrgrSts1_Diagc" 6 "ChrgrSts1_Boot" 7 "ChrgrSts1_Rstrt" 8 "ChrgrSts1_DisChrgn" 9 "ChrgrSts1_BookChrgn" 10 "ChrgrSts1_Shutdown" 11 "ChrgrSts1_Heating" 12 "ChrgrSts1_Cooling";
VAL_ 298 HndlLockgSts 0 "LockgSts_Unknown" 1 "LockgSts_Locked" 2 "LockgSts_Unlocked" 3 "LockgSts_Fault";
VAL_ 294 DftlFltIndcn 0 "DftlFltIndcn1_Ok" 1 "DftlFltIndcn1_DftlTHi" 2 "DftlFltIndcn1_DftlSysPfmncLo" 3 "DftlFltIndcn1_DftlSysSrvRqrd" 4 "DftlFltIndcn1_Resd1" 5 "DftlFltIndcn1_Resd2" 6 "DftlFltIndcn1_Resd3" 7 "DftlFltIndcn1_Resd4";
VAL_ 294 TrsmStAxleReActr 0 "TrsmStAxleReActr1_DftlInWOk" 1 "TrsmStAxleReActr1_DftlCluOpen" 2 "TrsmStAxleReActr1_DftlCluClsd";
VAL_ 567 MvIsgBltPretensionReq 0 "NotActvActv1_NotActv" 1 "NotActvActv1_Actv";
VAL_ 68 MvIsgModReqMvIsgModReq 0 "MvIsgModReq_Reserved1" 1 "MvIsgModReq_Stb" 2 "MvIsgModReq_TqCtrl" 3 "MvIsgModReq_STARTER" 4 "MvIsgModReq_UDcCtrl" 5 "MvIsgModReq_Reserved2" 6 "MvIsgModReq_SpdCtrl" 7 "MvIsgModReq_ESA" 8 "MvIsgModReq_DISCHARGE" 9 "MvIsgModReq_Reserved3" 10 "MvIsgModReq_GENERATORNoBATT";
VAL_ 333 MvDcDcModReqMvDcDcModReq 0 "MvDcDcModReq1_StbBy" 1 "MvDcDcModReq1_PreChrgReq" 4 "MvDcDcModReq1_Fwd" 5 "MvDcDcModReq1_Rvs";
VAL_ 67 MvBattRlyReq 0 "BattRly_Open" 1 "BattRly_Clsd";
VAL_ 67 MvDcDcModReqSec 0 "MvDcDcModReq2_StbBy" 1 "MvDcDcModReq2_Fwd";
VAL_ 341 PtToTrsmRatMgrIfPtGearReq 0 "PtGearReq1_Gear1" 1 "PtGearReq1_Gear2" 2 "PtGearReq1_Gear3" 3 "PtGearReq1_Gear4" 4 "PtGearReq1_Gear5" 5 "PtGearReq1_Gear6" 6 "PtGearReq1_Gear7" 7 "PtGearReq1_Gear8" 8 "PtGearReq1_Spare";
VAL_ 341 PtToTrsmRatMgrIfPtGearReqInter 0 "PtGearReq1_Gear1" 1 "PtGearReq1_Gear2" 2 "PtGearReq1_Gear3" 3 "PtGearReq1_Gear4" 4 "PtGearReq1_Gear5" 5 "PtGearReq1_Gear6" 6 "PtGearReq1_Gear7" 7 "PtGearReq1_Gear8" 8 "PtGearReq1_Spare";
VAL_ 341 PtToTrsmRatMgrIfPtLockFwAtGearFirst 0 "Boolean_FALSE" 1 "Boolean_TRUE";
VAL_ 341 PtToTrsmRatMgrIfPtLockUpReq 0 "PtLockUpType_OpenLockUp" 1 "PtLockUpType_SlipLockUp" 2 "PtLockUpType_MicroSlipLockUp" 3 "PtLockUpType_LockUpLockd";
VAL_ 341 PtToTrsmRatMgrIfPtShiftTypReq 0 "PtShiftTypReq2_ShiftQly0" 1 "PtShiftTypReq2_ShiftQly1" 2 "PtShiftTypReq2_ShiftQly2" 3 "PtShiftTypReq2_ShiftQly3" 4 "PtShiftTypReq2_ShiftQly4" 5 "PtShiftTypReq2_ShiftQly5" 6 "PtShiftTypReq2_ShiftQly6" 7 "PtShiftTypReq2_ShiftQly7" 8 "PtShiftTypReq2_ShiftQly8" 9 "PtShiftTypReq2_ShiftQly9" 10 "PtShiftTypReq2_ShiftQly10" 11 "PtShiftTypReq2_ShiftQly11" 12 "PtShiftTypReq2_AShiftQly0" 13 "PtShiftTypReq2_AShiftQly1" 14 "PtShiftTypReq2_AShiftQly2" 15 "PtShiftTypReq2_AShiftQly3";
VAL_ 341 PtToTrsmRatMgrIfPtTrsmModReq 0 "PtTrsmModReq_EngdWithPMax" 1 "PtTrsmModReq_Engd" 2 "PtTrsmModReq_EngdEco" 3 "PtTrsmModReq_Resd1" 4 "PtTrsmModReq_Neut" 5 "PtTrsmModReq_NeutEco" 6 "PtTrsmModReq_Tran" 7 "PtTrsmModReq_TranWithTqCpChg";
VAL_ 341 TrsmParkLockdTrsmParkLockd 0 "TrsmParkLock1_ParkNotEngd" 1 "TrsmParkLock1_ParkEngd" 2 "TrsmParkLock1_NotInUse" 3 "TrsmParkLock1_Undefd";
VAL_ 577 EngCooltInhbFlow 0 "CooltInhb_CoolntFlowReqToEngAllwd" 1 "CooltInhb_CoolntFlowReqToEngNotAllwd";
VAL_ 577 EngKdSts 0 "EngKdSts_Resd0" 1 "EngKdSts_NotActv" 2 "EngKdSts_Actv" 3 "EngKdSts_Resd3";
VAL_ 80 IsgModReq 0 "IsgModTyp1_Inin" 1 "IsgModTyp1_Stb" 2 "IsgModTyp1_TqCtrl" 3 "IsgModTyp1_SpdCtrl" 4 "IsgModTyp1_UDcCtrl" 5 "IsgModTyp1_PreChrg" 6 "IsgModTyp1_PwrDwn" 7 "IsgModTyp1_Flt" 8 "IsgModTyp1_TcsCtrl" 9 "IsgModTyp1_Reserved1" 10 "IsgModTyp1_Reserved2" 11 "IsgModTyp1_Reserved3" 12 "IsgModTyp1_Reserved4" 13 "IsgModTyp1_Reserved5" 14 "IsgModTyp1_Reserved6" 15 "IsgModTyp1_Reserved7";
VAL_ 102 PtGearAct 0 "PtGearAct1_Neut" 1 "PtGearAct1_Gear1" 2 "PtGearAct1_Gear2" 3 "PtGearAct1_Gear3" 4 "PtGearAct1_Gear4" 5 "PtGearAct1_Gear5" 6 "PtGearAct1_Gear6" 7 "PtGearAct1_Gear7" 8 "PtGearAct1_Gear8" 9 "PtGearAct1_Gear9" 10 "PtGearAct1_Gear10" 11 "PtGearAct1_Gear11" 12 "PtGearAct1_Gear12" 13 "PtGearAct1_Drv" 14 "PtGearAct1_Ukwn" 15 "PtGearAct1_Rvs";
VAL_ 102 WhlMotSysModReq 0 "WhlMotSysModStsTyp1_Inin" 1 "WhlMotSysModStsTyp1_Stb" 2 "WhlMotSysModStsTyp1_TqCtrl" 3 "WhlMotSysModStsTyp1_SpdCtrlIdle" 4 "WhlMotSysModStsTyp1_CluOper" 5 "WhlMotSysModStsTyp1_PreChrg" 6 "WhlMotSysModStsTyp1_PwrDwn" 7 "WhlMotSysModStsTyp1_Flt";
VAL_ 277 PtCluTqQly 0 "Qly3_De0" 1 "Qly3_De1" 2 "Qly3_De2" 3 "Qly3_De3" 4 "Qly3_De4" 5 "Qly3_De5" 6 "Qly3_De6" 7 "Qly3_De7";
VAL_ 277 PtDirAllwdToTrsmActrAuxFwd 0 "Flg1_Rst" 1 "Flg1_Set";
VAL_ 277 PtDirAllwdToTrsmActrAuxNeut 0 "Flg1_Rst" 1 "Flg1_Set";
VAL_ 277 PtDirAllwdToTrsmActrAuxParkRls 0 "Flg1_Rst" 1 "Flg1_Set";
VAL_ 277 PtDirAllwdToTrsmActrAuxRvs 0 "Flg1_Rst" 1 "Flg1_Set";
VAL_ 277 PtReqToTrsmActr 0 "PtReqToTrsmActr2_ParkReq" 1 "PtReqToTrsmActr2_RvsReq" 2 "PtReqToTrsmActr2_NeutReq" 3 "PtReqToTrsmActr2_DrvReq" 4 "PtReqToTrsmActr2_NoMoveReq" 5 "PtReqToTrsmActr2_Resd1" 6 "PtReqToTrsmActr2_Resd2" 7 "PtReqToTrsmActr2_Resd3";
VAL_ 305 DcDcActvdReq 0 "DcDcActvd_NoConversionToLVSide" 1 "DcDcActvd_ConversionToLVSide";
VAL_ 305 PtAllwdToTrsmActrSafePtAllwdToTrsmActr 0 "PtAllwdToTrsmActr1_NotAllwd1" 1 "PtAllwdToTrsmActr1_RvsAllwd" 2 "PtAllwdToTrsmActr1_RvsNotAllwd" 3 "PtAllwdToTrsmActr1_NotAllwd2" 4 "PtAllwdToTrsmActr1_ParkRelsAllwd" 5 "PtAllwdToTrsmActr1_RvsAllwdAndParkRelsAllwd" 6 "PtAllwdToTrsmActr1_RvsNotAllwdAndParkRelsAllwd" 7 "PtAllwdToTrsmActr1_NotAllwd3" 8 "PtAllwdToTrsmActr1_ParkRelsNotAllwd" 9 "PtAllwdToTrsmActr1_RvsAllwdAndParkRelsNotAllwd" 10 "PtAllwdToTrsmActr1_RvsNotAllwdAndParkRelsNotAllwd" 11 "PtAllwdToTrsmActr1_NotAllwd4" 12 "PtAllwdToTrsmActr1_NotAllwd5" 13 "PtAllwdToTrsmActr1_NotAllwd6" 14 "PtAllwdToTrsmActr1_NotAllwd7" 15 "PtAllwdToTrsmActr1_NotAllwd8";
VAL_ 405 HvPwrEgyPrio 0 "HvPwrEgyPrio_Standby" 1 "HvPwrEgyPrio_Dischrgning" 2 "HvPwrEgyPrio_Chrgning" 3 "HvPwrEgyPrio_ClimaWithAc" 4 "HvPwrEgyPrio_ClimaWithoutAc" 5 "HvPwrEgyPrio_RemoteClimatisaiton";
VAL_ 405 OnBdChrgrPwrEnaAllwd 0 "Boolean_FALSE" 1 "Boolean_TRUE";
VAL_ 816 HvCooltHeatrStsSig 0 "HvCooltHeatrSts_Off" 1 "HvCooltHeatrSts_LockedUntilNextStart" 2 "HvCooltHeatrSts_LockedUntilService" 3 "HvCooltHeatrSts_LockedPermanent" 4 "HvCooltHeatrSts_Operation" 5 "HvCooltHeatrSts_Reserved1" 6 "HvCooltHeatrSts_Reserved2" 7 "HvCooltHeatrSts_Reserved3";
VAL_ 512 PtTqAtWhlFrntActPtTqAtWhlFrntQly 0 "Qly3_De0" 1 "Qly3_De1" 2 "Qly3_De2" 3 "Qly3_De3" 4 "Qly3_De4" 5 "Qly3_De5" 6 "Qly3_De6" 7 "Qly3_De7";
VAL_ 545 EngTQf 0 "Qf1_DevOfDataUndefd" 1 "Qf1_DataTmpUndefdAndEvlnInProgs" 2 "Qf1_DevOfDataNotWithinRngAllwd" 3 "Qf1_DataCalcdWithDevDefd";
VAL_ 545 GearLvrEna 0 "NoYes1_No" 1 "NoYes1_Yes";
VAL_ 545 HvBattCoolgCmd 0 "HVBattChargnCmd_OK" 1 "HVBattChargnCmd_NOK" 2 "HVBattChargnCmd_INIT" 3 "HVBattChargnCmd_HOLD";
VAL_ 545 HvOnMaiReq 0 "HvActvnSts_Open" 1 "HvActvnSts_Clsd" 2 "HvActvnSts_KeepSt" 3 "HvActvnSts_OpenAndReqActvDcha";
VAL_ 545 IsgActvDampgModReq 0 "WhlMotSysActvDampgModCodSts_NoDampg" 1 "WhlMotSysActvDampgModCodSts_LoDampg" 2 "WhlMotSysActvDampgModCodSts_MedDampg" 3 "WhlMotSysActvDampgModCodSts_HiDampg";
VAL_ 545 WrmUpCyc 0 "OnOff1_Off" 1 "OnOff1_On";
VAL_ 592 EngEffSts 0 "EffSts1_EffNom" 1 "EffSts1_EffHi" 2 "EffSts1_EffLo" 3 "EffSts1_EffLimn";
VAL_ 592 HvBattChrgnCmd 0 "HVBattChargnCmd_OK" 1 "HVBattChargnCmd_NOK" 2 "HVBattChargnCmd_INIT" 3 "HVBattChargnCmd_HOLD";
VAL_ 647 BookChargeSetResponse 0 "BookChargeSetResponse_Default" 1 "BookChargeSetResponse_Success" 2 "BookChargeSetResponse_Cancelled" 3 "BookChargeSetResponse_Fail";
VAL_ 647 ChrgnSts 0 "ChrgnSts_Fault" 1 "ChrgnSts_ChargingInParkingState" 2 "ChrgnSts_ChargingInDrivingState" 3 "ChrgnSts_NotCharging" 4 "ChrgnSts_ChargingCompleted" 5 "ChrgnSts_Invalid";
VAL_ 647 CmptmtCoolgSts 0 "CmptmtCoolgSts_OffNoReq" 1 "CmptmtCoolgSts_OffByEvaprTLo" 2 "CmptmtCoolgSts_OffByPLo" 3 "CmptmtCoolgSts_OffByAmbTOutOfRng" 4 "CmptmtCoolgSts_OffBySysFailr" 5 "CmptmtCoolgSts_OffByLoadCut" 6 "CmptmtCoolgSts_OnWithBattCoolg" 7 "CmptmtCoolgSts_On";
VAL_ 647 DeactvtTestCom 0 "OnOff2_On" 1 "OnOff2_Off";
VAL_ 647 MonrCycCmpl 0 "NotCmpl1_NotCmpl" 1 "NotCmpl1_Cmpl";
VAL_ 647 PrpsnSysActv 0 "NotCmpl1_NotCmpl" 1 "NotCmpl1_Cmpl";
VAL_ 1160 HvBattThermInfoCorrInFutureThermModAtTime 0 "Idle" 1 "ThermalBalancing" 2 "PassiveHeating" 3 "ActiveHeating" 4 "PassiveCooling" 5 "ActiveCooling" 6 "CombinedCooling" 7 "Reserved";
VAL_ 586 HvBattThermReqFb 0 "HvBattThermReqFb_Default" 1 "HvBattThermReqFb_Heating" 2 "HvBattThermReqFb_HeatFinished" 3 "HvBattThermReqFb_RadiatorCooling" 4 "HvBattThermReqFb_CompressorCooling" 5 "HvBattThermReqFb_CoolingFinish" 6 "HvBattThermReqFb_Inhibited" 7 "HvBattThermReqFb_HeatingByEmotCoolt" 8 "HvBattThermReqFb_Fault";
VAL_ 75 DrvrDesDirDrvrDesDir 0 "DrvrDesDir1_Undefd" 1 "DrvrDesDir1_Fwd" 2 "DrvrDesDir1_Rvs" 3 "DrvrDesDir1_Neut" 4 "DrvrDesDir1_Resd0" 5 "DrvrDesDir1_Resd1" 6 "DrvrDesDir1_Resd2" 7 "DrvrDesDir1_Resd3";
VAL_ 75 EngSt1WdStsEngSt1WdSts 0 "EngSt1_Ini" 1 "EngSt1_Awake" 2 "EngSt1_Rdy" 3 "EngSt1_PreStrtg" 4 "EngSt1_StrtgInProgs" 5 "EngSt1_RunngRunng" 6 "EngSt1_RunngStb" 7 "EngSt1_RunngStrtgInProgs" 8 "EngSt1_RunngRemStrtd" 9 "EngSt1_AftRun";
VAL_ 75 GearLvrIndcn 0 "GearLvrIndcn2_ParkIndcn" 1 "GearLvrIndcn2_RvsIndcn" 2 "GearLvrIndcn2_NeutIndcn" 3 "GearLvrIndcn2_DrvIndcn" 4 "GearLvrIndcn2_ManModeIndcn" 5 "GearLvrIndcn2_Resd1" 6 "GearLvrIndcn2_Resd2" 7 "GearLvrIndcn2_Undefd";
VAL_ 75 HvchSts 0 "HvCooltHeatrSts_Off" 1 "HvCooltHeatrSts_LockedUntilNextStart" 2 "HvCooltHeatrSts_LockedUntilService" 3 "HvCooltHeatrSts_LockedPermanent" 4 "HvCooltHeatrSts_Operation" 5 "HvCooltHeatrSts_Reserved1" 6 "HvCooltHeatrSts_Reserved2" 7 "HvCooltHeatrSts_Reserved3";
SIG_GROUP_ 74 AccrPedlRat 1 : AccrPedlRatAccrPedlRat AccrPedlRatChks AccrPedlRatCntr;
SIG_GROUP_ 1249 DftlCtrlInfo1 1 : DftlCtrlInfo10 DftlCtrlInfo11 DftlCtrlInfo12 DftlCtrlInfo13 DftlCtrlInfo14 DftlCtrlInfo15 DftlCtrlInfo16 DftlCtrlInfo17;
SIG_GROUP_ 1250 DftlCtrlInfo2 1 : DftlCtrlInfo20 DftlCtrlInfo21 DftlCtrlInfo22 DftlCtrlInfo23 DftlCtrlInfo24 DftlCtrlInfo25 DftlCtrlInfo26 DftlCtrlInfo27;
SIG_GROUP_ 1251 DftlCtrlInfo3 1 : DftlCtrlInfo30 DftlCtrlInfo31 DftlCtrlInfo32 DftlCtrlInfo33 DftlCtrlInfo34 DftlCtrlInfo35 DftlCtrlInfo36 DftlCtrlInfo37;
SIG_GROUP_ 1252 DftlCtrlInfo4 1 : DftlCtrlInfo40 DftlCtrlInfo41 DftlCtrlInfo42 DftlCtrlInfo43 DftlCtrlInfo44 DftlCtrlInfo45 DftlCtrlInfo46 DftlCtrlInfo47;
SIG_GROUP_ 1253 DftlCtrlInfo5 1 : DftlCtrlInfo50 DftlCtrlInfo51 DftlCtrlInfo52 DftlCtrlInfo53 DftlCtrlInfo54 DftlCtrlInfo55 DftlCtrlInfo56 DftlCtrlInfo57;
SIG_GROUP_ 1254 DftlCtrlInfo6 1 : DftlCtrlInfo60 DftlCtrlInfo61 DftlCtrlInfo62 DftlCtrlInfo63 DftlCtrlInfo64 DftlCtrlInfo65 DftlCtrlInfo66 DftlCtrlInfo67;
SIG_GROUP_ 75 DrvrDesDir 1 : DrvrDesDirChks DrvrDesDirCntr DrvrDesDirDrvrDesDir;
SIG_GROUP_ 102 EngNSafe 1 : EngNSafeEngN EngNSafeEngNChks EngNSafeEngNCntr EngNSafeEngNGrdt;
SIG_GROUP_ 75 EngSt1WdSts 1 : EngSt1WdStsChks EngSt1WdStsCntr EngSt1WdStsEngSt1WdSts;
SIG_GROUP_ 545 EngT 1 : EngTEngT EngTQf;
SIG_GROUP_ 656 HvBattCellTInfo 1 : HvBattCellTInfoHvBattSnsrT HvBattCellTInfoHvBattTMax HvBattCellTInfoHvBattTMin HvBattCellTInfoHvBattTSnsrNr HvBattCellTInfoHvTempSnsrTMaxsSerlNr HvBattCellTInfoHvTempSnsrTMinSerlNr;
SIG_GROUP_ 322 HvBattCellUInfo 1 : HvBattCellUInfoU1 HvBattCellUInfoU2 HvBattCellUInfoU3 HvBattCellUInfoU4;
SIG_GROUP_ 839 HvBattCod 1 : HvBattCodPackCodeX1 HvBattCodPackCodeX2 HvBattCodPackCodeX3 HvBattCodPackCodeX4 HvBattCodPackCodeX5 HvBattCodPackCodeX6 HvBattCodPackIndex;
SIG_GROUP_ 373 HvBattLimnIndcn 1 : HvBattLimnIndcnChks HvBattLimnIndcnCntr HvBattLimnIndcnHvBattLimnIndcn;
SIG_GROUP_ 789 HvBattT 1 : HvBattTAvg HvBattTMax HvBattTMin;
SIG_GROUP_ 1160 HvBattThermInfoCorrInFuture 1 : HvBattThermInfoCorrInFuturePwrAtTime HvBattThermInfoCorrInFutureSequenceNo HvBattThermInfoCorrInFutureTempAtTime HvBattThermInfoCorrInFutureThermModAtTime HvBattThermInfoCorrInFutureTime HvBattThermInfoCorrInFutureVersionNo;
SIG_GROUP_ 1161 HvBattThermInfoInFuture 1 : HvBattThermInfoInFuturePwrAtTime HvBattThermInfoInFutureSequenceNo HvBattThermInfoInFutureTempAtTime HvBattThermInfoInFutureThermModAtTime HvBattThermInfoInFutureTime HvBattThermInfoInFutureVersionNo;
SIG_GROUP_ 321 HvSysRlySts 1 : HvSysRlyStsChks HvSysRlyStsCntr HvSysRlyStsHvSysRlySts;
SIG_GROUP_ 521 IDcDcActLoSide 1 : IDcDcActLoSideChks IDcDcActLoSideCntr IDcDcActLoSideIDcDcActLoSide;
SIG_GROUP_ 333 MvDcDcModReq 1 : MvDcDcModReqChks MvDcDcModReqCntr MvDcDcModReqMvDcDcModReq;
SIG_GROUP_ 68 MvIsgModReq 1 : MvIsgModReqChks MvIsgModReqCntr MvIsgModReqMvIsgModReq;
SIG_GROUP_ 68 MvIsgTqReq 1 : MvIsgTqReqChks MvIsgTqReqCntr MvIsgTqReqMvIsgTqReq;
SIG_GROUP_ 536 OnBdChrgrErrIndcnReq 1 : OnBdChrgrErrIndcnReqChks OnBdChrgrErrIndcnReqCntr OnBdChrgrErrIndcnReqOnBdChrgrErrIndcnReq;
SIG_GROUP_ 305 PtAllwdToTrsmActrSafe 1 : PtAllwdToTrsmActrSafeChks PtAllwdToTrsmActrSafeCntr PtAllwdToTrsmActrSafePtAllwdToTrsmActr;
SIG_GROUP_ 277 PtCluTq 1 : PtCluTqDyn PtCluTqPtCluTq PtCluTqQly;
SIG_GROUP_ 277 PtDirAllwdToTrsmActrAux 1 : PtDirAllwdToTrsmActrAuxChks PtDirAllwdToTrsmActrAuxCntr PtDirAllwdToTrsmActrAuxFwd PtDirAllwdToTrsmActrAuxNeut PtDirAllwdToTrsmActrAuxParkRls PtDirAllwdToTrsmActrAuxRvs;
SIG_GROUP_ 341 PtToTrsmRatMgrIf 1 : PtToTrsmRatMgrIfPtGearReq PtToTrsmRatMgrIfPtGearReqInter PtToTrsmRatMgrIfPtLockFwAtGearFirst PtToTrsmRatMgrIfPtLockUpReq PtToTrsmRatMgrIfPtLockUpSlipReq PtToTrsmRatMgrIfPtShiftTypReq PtToTrsmRatMgrIfPtTrsmModReq;
SIG_GROUP_ 512 PtTqAtWhlFrntAct 1 : PtTqAtWhlFrntActPtTqAtWhlFrntAct PtTqAtWhlFrntActPtTqAtWhlFrntLeAct PtTqAtWhlFrntActPtTqAtWhlFrntQly PtTqAtWhlFrntActPtTqAtWhlFrntRiAct PtTqAtWhlFrntActRecChks PtTqAtWhlFrntActRecCntr;
SIG_GROUP_ 131 SecBattSftySig 1 : SecBattSftySigChks SecBattSftySigCntr SecBattSftySigSysSaftyBattI SecBattSftySigSysSaftyBattU;
SIG_GROUP_ 577 TrsmActrKey 1 : TrsmActrKeyChks TrsmActrKeyCntr TrsmActrKeyEna;
SIG_GROUP_ 341 TrsmParkLockd 1 : TrsmParkLockdChks TrsmParkLockdCntr TrsmParkLockdTrsmParkLockd;
SIG_GROUP_ 1345 VFCVectorBECM 1 : VFCVectorBECMBlockID VFCVectorBECMVFCid0 VFCVectorBECMVFCid1 VFCVectorBECMVFCid10 VFCVectorBECMVFCid11 VFCVectorBECMVFCid12 VFCVectorBECMVFCid13 VFCVectorBECMVFCid14 VFCVectorBECMVFCid15 VFCVectorBECMVFCid16 VFCVectorBECMVFCid17 VFCVectorBECMVFCid18 VFCVectorBECMVFCid19 VFCVectorBECMVFCid2 VFCVectorBECMVFCid20 VFCVectorBECMVFCid21 VFCVectorBECMVFCid22 VFCVectorBECMVFCid23 VFCVectorBECMVFCid24 VFCVectorBECMVFCid25 VFCVectorBECMVFCid26 VFCVectorBECMVFCid27 VFCVectorBECMVFCid28 VFCVectorBECMVFCid29 VFCVectorBECMVFCid3 VFCVectorBECMVFCid30 VFCVectorBECMVFCid31 VFCVectorBECMVFCid32 VFCVectorBECMVFCid33 VFCVectorBECMVFCid34 VFCVectorBECMVFCid35 VFCVectorBECMVFCid36 VFCVectorBECMVFCid37 VFCVectorBECMVFCid38 VFCVectorBECMVFCid39 VFCVectorBECMVFCid4 VFCVectorBECMVFCid40 VFCVectorBECMVFCid41 VFCVectorBECMVFCid42 VFCVectorBECMVFCid43 VFCVectorBECMVFCid44 VFCVectorBECMVFCid45 VFCVectorBECMVFCid46 VFCVectorBECMVFCid47 VFCVectorBECMVFCid48 VFCVectorBECMVFCid49 VFCVectorBECMVFCid5 VFCVectorBECMVFCid50 VFCVectorBECMVFCid51 VFCVectorBECMVFCid52 VFCVectorBECMVFCid53 VFCVectorBECMVFCid54 VFCVectorBECMVFCid55 VFCVectorBECMVFCid56 VFCVectorBECMVFCid57 VFCVectorBECMVFCid58 VFCVectorBECMVFCid59 VFCVectorBECMVFCid6 VFCVectorBECMVFCid60 VFCVectorBECMVFCid61 VFCVectorBECMVFCid7 VFCVectorBECMVFCid8 VFCVectorBECMVFCid9;
SIG_GROUP_ 405 WhlMotSysTqAllwd 1 : WhlMotSysTqAllwdChks WhlMotSysTqAllwdCntr WhlMotSysTqAllwdWhlMotSysTqAllwd;
